VERSION "HNNBNNNYNNNNNNNNNNNNNNNNNNNNNNNNNNNNNNNNNN/4/%%%/4/'%**4NNN///"

NS_ :

BS_:

BU_: BAP_Tester BCM1 Gateway Klima_MSB Lift_VA VAS_L VAS_R

BO_ 958 Motor_14: 8 Gateway
 SG_ Motor_14_CRC : 0|8@1+ (1,0) [0|255] ""  Vector__XXX
 SG_ Motor_14_BZ : 8|4@1+ (1,0) [0|15] ""  Vector__XXX
 SG_ MO_StartStopp_Status : 12|2@1+ (1.0,0.0) [0.0|3] ""  BCM1,Klima_MSB,Lift_VA
 SG_ MO_StartStopp_Wiederstart : 14|1@1+ (1.0,0.0) [0.0|1] ""  BCM1,Klima_MSB,Lift_VA
 SG_ MO_StartStopp_Motorstopp : 15|1@1+ (1.0,0.0) [0.0|1] ""  BCM1,Klima_MSB,Lift_VA
 SG_ MO_Freig_Reku : 16|2@1+ (1.0,0.0) [0.0|3] ""  Vector__XXX
 SG_ MO_Kl_75 : 18|1@1+ (1.0,0.0) [0.0|1] ""  BCM1,Klima_MSB,VAS_L,VAS_R
 SG_ MO_Kl_50 : 19|1@1+ (1.0,0.0) [0.0|1] ""  Lift_VA
 SG_ MO_Gangposition : 20|4@1+ (1.0,0.0) [0.0|15] ""  BCM1,Klima_MSB,VAS_L,VAS_R
 SG_ MO_StartStopp_Fahrerwunsch : 24|2@1+ (1.0,0.0) [0.0|3] ""  BCM1,Klima_MSB,Lift_VA
 SG_ MO_HYB_Fahrbereitschaft : 26|1@1+ (1.0,0.0) [0.0|1] ""  BCM1,Klima_MSB
 SG_ MO_Ext_E_Fahrt_aktiv : 27|1@1+ (1.0,0.0) [0.0|1] ""  BCM1,Klima_MSB
 SG_ MO_Fahrer_bremst : 28|1@1+ (1.0,0.0) [0.0|1] ""  BCM1
 SG_ MO_QBit_Fahrer_bremst : 29|1@1+ (1.0,0.0) [0.0|1] ""  BCM1
 SG_ MO_BLS : 30|1@1+ (1.0,0.0) [0.0|1] ""  BCM1
 SG_ MO_Konsistenz_Bremsped : 31|1@1+ (1.0,0.0) [0.0|1] ""  Vector__XXX
 SG_ MO_KomFehler_ESP : 32|1@1+ (1.0,0.0) [0.0|1] ""  Vector__XXX
 SG_ MO_Klima_Eingr : 33|2@1+ (1.0,0.0) [0.0|3] ""  BCM1,Klima_MSB
 SG_ MO_Aussp_Anlass : 35|1@1+ (1.0,0.0) [0.0|1] ""  Vector__XXX
 SG_ MO_Freig_Anlass : 36|1@1+ (1.0,0.0) [0.0|1] ""  Vector__XXX
 SG_ MO_Kuppl_schalter : 37|1@1+ (1.0,0.0) [0.0|1] ""  BCM1
 SG_ MO_Interlock : 38|1@1+ (1.0,0.0) [0.0|1] ""  BCM1
 SG_ MO_Motor_laeuft : 39|1@1+ (1.0,0.0) [0.0|1] ""  BCM1,Klima_MSB,Lift_VA
 SG_ MO_Kickdown : 40|1@1+ (1.0,0.0) [0.0|1] ""  BCM1,Klima_MSB
 SG_ MO_QBit_KL_75 : 41|1@1+ (1.0,0.0) [0.0|1] ""  BCM1
 SG_ MO_EKlKomLeiRed : 42|2@1+ (1.0,0.0) [0.0|3] ""  Vector__XXX
 SG_ MO_Handshake_STH : 44|1@1+ (1.0,0.0) [0.0|1] ""  Vector__XXX
 SG_ MO_BKV_Unterdruckwarnung : 45|1@1+ (1.0,0.0) [0.0|1] ""  Vector__XXX
 SG_ MO_Freigabe_Segeln : 46|1@1+ (1.0,0.0) [0.0|1] ""  Vector__XXX
 SG_ MO_PTC_Status : 47|3@1+ (1.0,0.0) [0.0|7] ""  Vector__XXX
 SG_ MO_QBit_Gangposition : 50|1@1+ (1.0,0.0) [0.0|1] ""  Vector__XXX
 SG_ MO_Signalquelle_Gangposition : 51|1@1+ (1.0,0.0) [0.0|1] ""  Vector__XXX
 SG_ MO_Remotestart_Betrieb : 52|1@1+ (1.0,0.0) [0.0|1] ""  Vector__XXX
 SG_ MO_Remotestart_moeglich : 53|1@1+ (1.0,0.0) [0.0|1] ""  Vector__XXX
 SG_ MO_FMAus_aktiv : 55|1@1+ (1.0,0.0) [0.0|1] ""  BCM1,Klima_MSB
 SG_ MO_FMAus_Startvariante : 56|2@1+ (1.0,0.0) [0.0|3] ""  Vector__XXX
 SG_ MO_BMS_NV_Anf_stuetzen : 58|1@1+ (1.0,0.0) [0.0|1] ""  Vector__XXX
 SG_ MO_Zylinderabschaltung : 59|2@1+ (1.0,0.0) [0.0|3] ""  Vector__XXX
 SG_ MO_HYB_VM_aktiv : 61|1@1+ (1.0,0.0) [0.0|1] ""  BCM1,Klima_MSB
 SG_ MO_StartVorauss_erfuellt : 62|2@1+ (1.0,0.0) [0.0|3] ""  Vector__XXX

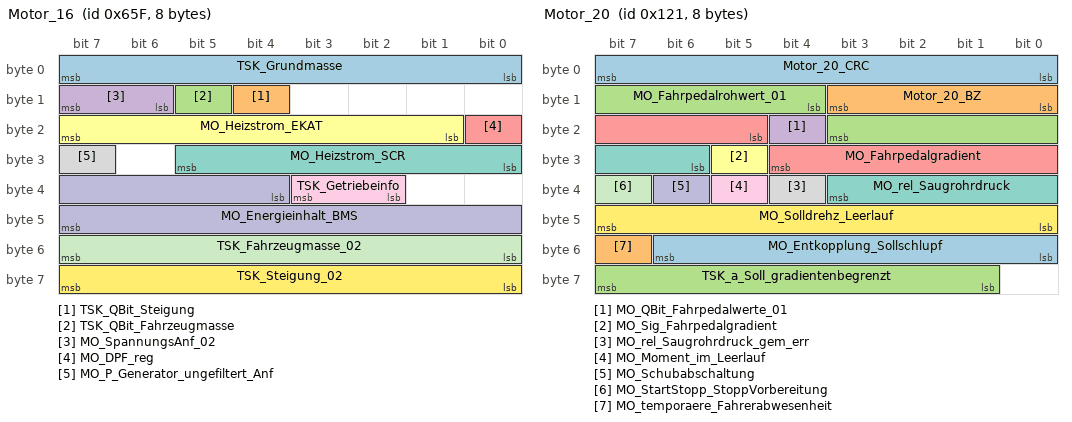
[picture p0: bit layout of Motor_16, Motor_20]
BO_ 1631 Motor_16: 8 Gateway
 SG_ TSK_Grundmasse : 0|8@1+ (32,0) [0|8128] "Unit_KiloGram"  Vector__XXX
 SG_ TSK_QBit_Steigung : 12|1@1+ (1.0,0.0) [0.0|1] ""  BCM1
 SG_ TSK_QBit_Fahrzeugmasse : 13|1@1+ (1.0,0.0) [0.0|1] ""  Vector__XXX
 SG_ MO_SpannungsAnf_02 : 14|2@1+ (1.0,0.0) [0.0|3] ""  Vector__XXX
 SG_ MO_DPF_reg : 16|1@1+ (1.0,0.0) [0.0|1] ""  Vector__XXX
 SG_ MO_Heizstrom_EKAT : 17|7@1+ (1,0) [0|126] "Unit_Amper"  Vector__XXX
 SG_ MO_Heizstrom_SCR : 24|6@1+ (1,0) [0|62] "Unit_Amper"  Vector__XXX
 SG_ MO_P_Generator_ungefiltert_Anf : 31|1@1+ (1.0,0.0) [0.0|1] ""  Vector__XXX
 SG_ TSK_Getriebeinfo : 34|2@1+ (1.0,0.0) [0.0|3] ""  Vector__XXX
 SG_ MO_Energieinhalt_BMS : 36|12@1+ (25,0) [0|102325] "Unit_WattHour"  Vector__XXX
 SG_ TSK_Fahrzeugmasse_02 : 48|8@1+ (32,0) [0|8128] "Unit_KiloGram"  Vector__XXX
 SG_ TSK_Steigung_02 : 56|8@1+ (0.8,-101.6) [-100.8|101.6] "Unit_PerCent"  BCM1

BO_ 812 Motor_17: 8 Gateway
 SG_ MO_Sperrung_FahrPr_BZS : 0|8@1+ (1.0,0.0) [0.0|255] ""  Vector__XXX
 SG_ MO_Rampenzeit_Generator_Anf : 8|4@1+ (1.0,0.0) [0.0|15] ""  Vector__XXX
 SG_ MO_Prio_MAX_Wunschdrehzahl : 12|1@1+ (1.0,0.0) [0.0|1] ""  Vector__XXX
 SG_ MO_Prio_MIN_Wunschdrehzahl : 13|1@1+ (1.0,0.0) [0.0|1] ""  Vector__XXX
 SG_ MO_Luftpfad_aktiv : 14|1@1+ (1.0,0.0) [0.0|1] ""  Vector__XXX
 SG_ MO_v_Begrenz_Aktivierbar : 15|1@1+ (1.0,0.0) [0.0|1] ""  Vector__XXX
 SG_ MO_Drehzahlbeeinflussung : 16|8@1+ (0.39,0) [0.00|99.45] "Unit_PerCent"  Vector__XXX
 SG_ MO_MIN_Wunschdrehzahl : 24|8@1+ (25,0) [0|6350] "Unit_MinutInver"  Vector__XXX
 SG_ MO_MAX_Wunschdrehzahl : 32|9@1+ (25,0) [0|12750] "Unit_MinutInver"  Vector__XXX
 SG_ MO_Charisma_FahrPr : 41|4@1+ (1.0,0.0) [0.0|15] ""  Vector__XXX
 SG_ MO_Charisma_Status : 45|2@1+ (1.0,0.0) [0.0|3] ""  Vector__XXX
 SG_ MO_StSt_Charisma_FahrPr : 47|4@1+ (1.0,0.0) [0.0|15] ""  Vector__XXX
 SG_ MO_StSt_Charisma_Status : 51|2@1+ (1.0,0.0) [0.0|3] ""  Vector__XXX
 SG_ MO_BZS_Charisma_FahrPr : 53|4@1+ (1.0,0.0) [0.0|15] ""  BCM1
 SG_ MO_BZS_Charisma_Status : 57|2@1+ (1.0,0.0) [0.0|3] ""  Vector__XXX
 SG_ MO_NGS_Position : 59|1@1+ (1.0,0.0) [0.0|1] ""  Vector__XXX
 SG_ MO_NGS_Status : 60|2@1+ (1.0,0.0) [0.0|3] ""  Vector__XXX
 SG_ MO_v_Begrenzung_Niveau : 62|2@1+ (1.0,0.0) [0.0|3] ""  Vector__XXX

BO_ 1648 Motor_18: 8 Gateway
 SG_ MO_max_Ladedruck : 0|6@1+ (0.1,0) [0.0|6.3] "Unit_Bar"  Vector__XXX
 SG_ MO_ANC_Kennfeld_Anf : 6|2@1+ (1.0,0.0) [0.0|3] ""  Vector__XXX
 SG_ MO_Bremslicht_Reku : 8|1@1+ (1.0,0.0) [0.0|1] ""  Vector__XXX
 SG_ MO_StartStopp_PopUp : 9|2@1+ (1.0,0.0) [0.0|3] ""  Vector__XXX
 SG_ MO1_Sperr_Info_WFS : 11|1@1+ (1.0,0.0) [0.0|1] ""  Vector__XXX
 SG_ MO1_Freigabe_Info_WFS : 12|1@1+ (1.0,0.0) [0.0|1] ""  Vector__XXX
 SG_ MO_EPCL : 13|3@1+ (1.0,0.0) [0.0|7] ""  Vector__XXX
 SG_ MO_Zylabsch_Texte_02 : 16|4@1+ (1.0,0.0) [0.0|15] ""  Vector__XXX
 SG_ MO_Fahrzeugtyp : 20|3@1+ (1.0,0.0) [0.0|7] ""  Vector__XXX
 SG_ MO_NMAX_Schaltanzeige : 23|9@1+ (25,0) [0|12775] "Unit_MinutInver"  Vector__XXX
 SG_ MO_Abstellzeit : 32|8@1+ (8,0) [0|2024] "Unit_Minut"  BCM1,Klima_MSB
 SG_ MO_Abstellzeit_Status : 40|2@1+ (1.0,0.0) [0.0|3] ""  BCM1,Klima_MSB
 SG_ MO1_Freigabe_Verfallsinfo_WFS : 42|1@1+ (1.0,0.0) [0.0|1] ""  Vector__XXX
 SG_ MO_Hybrid_StartStopp_LED : 43|2@1+ (1.0,0.0) [0.0|3] ""  BCM1
 SG_ MO_Fehler_Zylabsch : 45|2@1+ (1.0,0.0) [0.0|3] ""  Vector__XXX
 SG_ MO_Anzahl_Abgesch_Zyl : 47|3@1+ (1.0,0.0) [0.0|7] ""  Vector__XXX
 SG_ MO_Zylabsch_Texte : 50|2@1+ (1.0,0.0) [0.0|3] ""  Vector__XXX
 SG_ MO_Ethanol_BS_Texte : 52|3@1+ (1.0,0.0) [0.0|7] ""  Vector__XXX
 SG_ MO_Drehzahl_Warnung : 55|1@1+ (1.0,0.0) [0.0|1] ""  Vector__XXX
 SG_ MO_obere_Drehzahlgrenze : 56|8@1+ (50,0) [50|12750] "Unit_MinutInver"  Vector__XXX

BO_ 289 Motor_20: 8 Gateway
 SG_ Motor_20_CRC : 0|8@1+ (1,0) [0|255] ""  Vector__XXX
 SG_ Motor_20_BZ : 8|4@1+ (1,0) [0|15] ""  Vector__XXX
 SG_ MO_Fahrpedalrohwert_01 : 12|8@1+ (0.4,0) [0.0|101.6] "Unit_PerCent"  BCM1
 SG_ MO_QBit_Fahrpedalwerte_01 : 20|1@1+ (1.0,0.0) [0.0|1] ""  Vector__XXX
 SG_ MO_Fahrpedalgradient : 21|8@1+ (25,0) [0|6350] "Unit_PerCentPerSecon"  Vector__XXX
 SG_ MO_Sig_Fahrpedalgradient : 29|1@1+ (1.0,0.0) [0.0|1] ""  Vector__XXX
 SG_ MO_rel_Saugrohrdruck : 30|6@1+ (18,0) [0|1116] "Unit_MilliBar"  Vector__XXX
 SG_ MO_rel_Saugrohrdruck_gem_err : 36|1@1+ (1.0,0.0) [0.0|1] ""  Vector__XXX
 SG_ MO_Moment_im_Leerlauf : 37|1@1+ (1.0,0.0) [0.0|1] ""  Vector__XXX
 SG_ MO_Schubabschaltung : 38|1@1+ (1.0,0.0) [0.0|1] ""  Vector__XXX
 SG_ MO_StartStopp_StoppVorbereitung : 39|1@1+ (1.0,0.0) [0.0|1] ""  Vector__XXX
 SG_ MO_Solldrehz_Leerlauf : 40|8@1+ (10,0) [0|2540] "Unit_MinutInver"  Vector__XXX
 SG_ MO_Entkopplung_Sollschlupf : 48|7@1+ (20,0) [0|2480] "Unit_MinutInver"  Vector__XXX
 SG_ MO_temporaere_Fahrerabwesenheit : 55|1@1+ (1.0,0.0) [0.0|1] ""  Vector__XXX
 SG_ TSK_a_Soll_gradientenbegrenzt : 57|7@1+ (0.1,-7.2) [-7.2|5.4] "Unit_MeterPerSeconSquar"  Vector__XXX

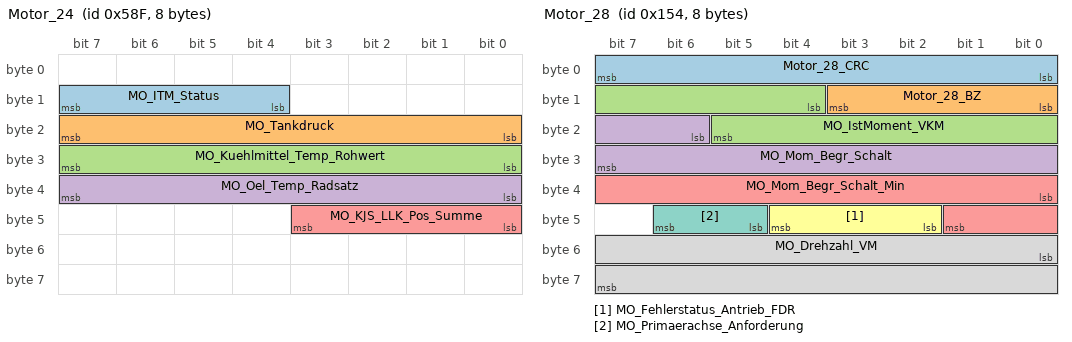
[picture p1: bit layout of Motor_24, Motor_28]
BO_ 1423 Motor_24: 8 Gateway
 SG_ MO_ITM_Status : 12|4@1+ (1.0,0.0) [0.0|15] ""  BCM1,Klima_MSB
 SG_ MO_Tankdruck : 16|8@1+ (2,-250) [-250|256] "Unit_MilliBar"  Vector__XXX
 SG_ MO_Kuehlmittel_Temp_Rohwert : 24|8@1+ (0.75,-48) [-48.00|141.75] "Unit_DegreCelsi"  Vector__XXX
 SG_ MO_Oel_Temp_Radsatz : 32|8@1+ (1,-60) [-60|193] "Unit_DegreCelsi"  Vector__XXX
 SG_ MO_KJS_LLK_Pos_Summe : 40|4@1+ (10,0) [0|100] "Unit_PerCent"  Vector__XXX

BO_ 967 Motor_26: 8 Gateway
 SG_ MO_Kuehlerluefter_MUX M  : 0|1@1+ (1.0,0.0) [0.0|1] ""  BCM1,Klima_MSB
 SG_ MO_Kuehlerluefter_1 m0  : 1|7@1+ (1,0) [0|100] "Unit_PerCent"  BCM1,Klima_MSB
 SG_ MO_Kuehlerluefter_2 m1  : 1|7@1+ (1,0) [0|100] "Unit_PerCent"  BCM1,Klima_MSB
 SG_ MO_EFLEX_Lampe : 8|2@1+ (1.0,0.0) [0.0|3] ""  Vector__XXX
 SG_ MO_KJS_nicht_bereit : 10|1@1+ (1.0,0.0) [0.0|1] ""  Vector__XXX
 SG_ MO_ITM_Warnung_Pumpe : 11|1@1+ (1.0,0.0) [0.0|1] ""  Vector__XXX
 SG_ WIV_Anzeige_aktiv : 12|1@1+ (1.0,0.0) [0.0|1] ""  Vector__XXX
 SG_ WIV_Oelmin_Warn : 13|1@1+ (1.0,0.0) [0.0|1] ""  Vector__XXX
 SG_ WIV_Sensorfehler : 14|1@1+ (1.0,0.0) [0.0|1] ""  Vector__XXX
 SG_ WIV_Schieflage : 15|1@1+ (1.0,0.0) [0.0|1] ""  Vector__XXX
 SG_ WIV_Oelstand : 16|4@1+ (12.5,0) [0.0|100.0] "Unit_PerCent"  Vector__XXX
 SG_ MO_Zustand_HWP : 20|2@1+ (1.0,0.0) [0.0|3] ""  Vector__XXX
 SG_ OLEV_Systemstoerung : 22|1@1+ (1.0,0.0) [0.0|1] ""  Vector__XXX
 SG_ MO_Oelwarnung_max : 23|1@1+ (1.0,0.0) [0.0|1] ""  Vector__XXX
 SG_ WIV_Oelsystem_aktiv : 24|1@1+ (1.0,0.0) [0.0|1] ""  Vector__XXX
 SG_ WIV_nicht_betriebswarm : 25|1@1+ (1.0,0.0) [0.0|1] ""  Vector__XXX
 SG_ WIV_Ueberfuell_Warn : 26|1@1+ (1.0,0.0) [0.0|1] ""  Vector__XXX
 SG_ WIV_laufender_Motor : 27|1@1+ (1.0,0.0) [0.0|1] ""  Vector__XXX
 SG_ MO_E_Warnungen : 28|4@1+ (1.0,0.0) [0.0|15] ""  Vector__XXX
 SG_ MO_Text_Motorstart : 32|4@1+ (1.0,0.0) [0.0|15] ""  Vector__XXX
 SG_ MO_E_Texte : 36|4@1+ (1.0,0.0) [0.0|15] ""  Vector__XXX
 SG_ WIV_Oeldyn_avl : 40|1@1+ (1.0,0.0) [0.0|1] ""  Vector__XXX
 SG_ MO_Text_Partikelfil_Reg : 41|1@1+ (1,0) [0|1] ""  Vector__XXX
 SG_ OLEV_Oelstand_nicht_vorhanden : 42|1@1+ (1.0,0.0) [0.0|1] ""  Vector__XXX
 SG_ WIV_Oelmenge : 43|5@1+ (125,0) [0|3875] "Unit_MilliLiter"  Vector__XXX
 SG_ MO_Systemlampe : 48|1@1+ (1.0,0.0) [0.0|1] ""  Vector__XXX
 SG_ MO_OBD2_Lampe : 49|1@1+ (1.0,0.0) [0.0|1] ""  Vector__XXX
 SG_ MO_Heissleuchte : 50|1@1+ (1.0,0.0) [0.0|1] ""  Vector__XXX
 SG_ MO_Partikel_Lampe : 51|1@1+ (1.0,0.0) [0.0|1] ""  Vector__XXX
 SG_ MO_RedFahrleistung_Lampe : 52|1@1+ (1.0,0.0) [0.0|1] ""  Vector__XXX
 SG_ WIV_Oelstand_nicht_vorhanden : 53|1@1+ (1.0,0.0) [0.0|1] ""  Vector__XXX
 SG_ WIV_nachfuellanzeige_ein : 54|1@1+ (1.0,0.0) [0.0|1] ""  Vector__XXX
 SG_ WIV_Ueberfuell_deaktiv : 55|1@1+ (1.0,0.0) [0.0|1] ""  Vector__XXX
 SG_ WIV_Unterfuell_Warn : 56|1@1+ (1.0,0.0) [0.0|1] ""  Vector__XXX
 SG_ MO_Tankdeckel_Lampe : 57|1@1+ (1.0,0.0) [0.0|1] ""  Vector__XXX
 SG_ MO_Text_Tankdeckelwarn : 58|1@1+ (1.0,0.0) [0.0|1] ""  Vector__XXX
 SG_ MO_Vorglueh_Lampe : 59|1@1+ (1.0,0.0) [0.0|1] ""  Vector__XXX
 SG_ WIV_Oeldr_Warn_Motor : 60|1@1+ (1.0,0.0) [0.0|1] ""  Vector__XXX
 SG_ MO_E_Mode : 61|3@1+ (1.0,0.0) [0.0|7] ""  Vector__XXX

BO_ 340 Motor_28: 8 Gateway
 SG_ Motor_28_CRC : 0|8@1+ (1,0) [0|255] ""  Vector__XXX
 SG_ Motor_28_BZ : 8|4@1+ (1,0) [0|15] ""  Vector__XXX
 SG_ MO_IstMoment_VKM : 12|10@1+ (1,-509) [-509|509] ""  Vector__XXX
 SG_ MO_Mom_Begr_Schalt : 22|10@1+ (1,-509) [-509|509] ""  Vector__XXX
 SG_ MO_Mom_Begr_Schalt_Min : 32|10@1+ (1,-509) [-509|509] ""  Vector__XXX
 SG_ MO_Fehlerstatus_Antrieb_FDR : 42|3@1+ (1.0,0.0) [0.0|7] ""  Vector__XXX
 SG_ MO_Primaerachse_Anforderung : 45|2@1+ (1.0,0.0) [0.0|3] ""  Vector__XXX
 SG_ MO_Drehzahl_VM : 48|16@1+ (0.25,0) [0.00|16383.00] "Unit_MinutInver"  BCM1,Klima_MSB

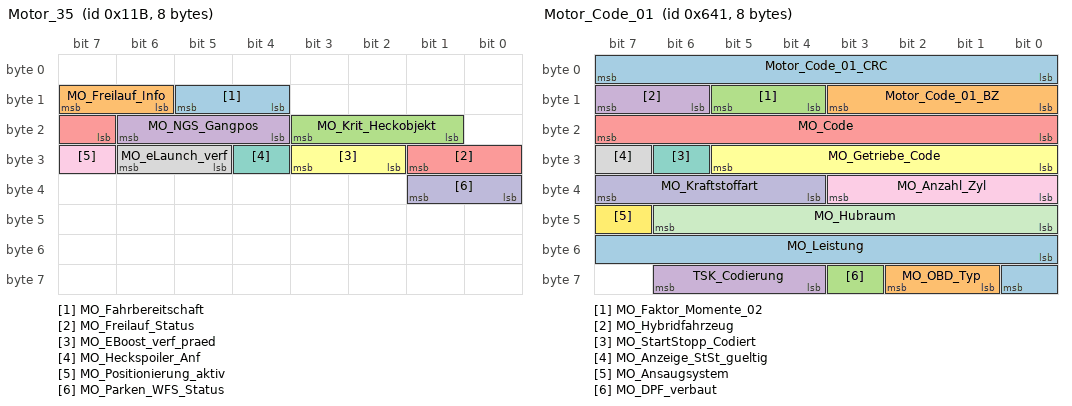
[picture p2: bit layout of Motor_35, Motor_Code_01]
BO_ 283 Motor_35: 8 Gateway
 SG_ MO_Fahrbereitschaft : 12|2@1+ (1.0,0.0) [0.0|3] ""  BCM1
 SG_ MO_Freilauf_Info : 14|2@1+ (1.0,0.0) [0.0|3] ""  Vector__XXX
 SG_ MO_Krit_Heckobjekt : 17|3@1+ (1.0,0.0) [0.0|7] ""  Vector__XXX
 SG_ MO_NGS_Gangpos : 20|3@1+ (1.0,0.0) [0.0|7] ""  Vector__XXX
 SG_ MO_Freilauf_Status : 23|3@1+ (1.0,0.0) [0.0|7] ""  Vector__XXX
 SG_ MO_EBoost_verf_praed : 26|2@1+ (1.0,0.0) [0.0|3] ""  Vector__XXX
 SG_ MO_Heckspoiler_Anf : 28|1@1+ (1.0,0.0) [0.0|1] ""  Vector__XXX
 SG_ MO_eLaunch_verf : 29|2@1+ (1.0,0.0) [0.0|3] ""  Vector__XXX
 SG_ MO_Positionierung_aktiv : 31|1@1+ (1.0,0.0) [0.0|1] ""  Vector__XXX
 SG_ MO_Parken_WFS_Status : 32|2@1+ (1.0,0.0) [0.0|3] ""  Vector__XXX

BO_ 1601 Motor_Code_01: 8 Gateway
 SG_ Motor_Code_01_CRC : 0|8@1+ (1,0) [0|255] ""  BCM1
 SG_ Motor_Code_01_BZ : 8|4@1+ (1,0) [0|15] ""  BCM1
 SG_ MO_Faktor_Momente_02 : 12|2@1+ (1,0) [1|3] "Unit_NewtoMeter"  BCM1
 SG_ MO_Hybridfahrzeug : 14|2@1+ (1.0,0.0) [0.0|3] ""  BCM1
 SG_ MO_Code : 16|8@1+ (1,0) [0|255] ""  BCM1,Klima_MSB
 SG_ MO_Getriebe_Code : 24|6@1+ (1.0,0.0) [0.0|63] ""  BCM1,Klima_MSB
 SG_ MO_StartStopp_Codiert : 30|1@1+ (1.0,0.0) [0.0|1] ""  Lift_VA
 SG_ MO_Anzeige_StSt_gueltig : 31|1@1+ (1.0,0.0) [0.0|1] ""  Vector__XXX
 SG_ MO_Anzahl_Zyl : 32|4@1+ (1.0,0.0) [0.0|15] ""  Vector__XXX
 SG_ MO_Kraftstoffart : 36|4@1+ (1.0,0.0) [0.0|15] ""  BCM1
 SG_ MO_Hubraum : 40|7@1+ (0.1,0) [0.0|12.7] "Unit_Liter"  Vector__XXX
 SG_ MO_Ansaugsystem : 47|1@1+ (1.0,0.0) [0.0|1] ""  Vector__XXX
 SG_ MO_Leistung : 48|9@1+ (1,0) [0|511] "Unit_KiloWatt"  Vector__XXX
 SG_ MO_OBD_Typ : 57|2@1+ (1.0,0.0) [0.0|3] ""  BCM1
 SG_ MO_DPF_verbaut : 59|1@1+ (1.0,0.0) [0.0|1] ""  Vector__XXX
 SG_ TSK_Codierung : 60|3@1+ (1.0,0.0) [0.0|7] ""  Vector__XXX

BO_ 394 Motor_Hybrid_11: 8 Gateway
 SG_ MO_Ablaufstatus : 12|4@1+ (1.0,0.0) [0.0|15] ""  Vector__XXX
 SG_ MO_Ablaufstrg_Betriebszustand : 16|3@1+ (1.0,0.0) [0.0|7] ""  Vector__XXX
 SG_ MO_Ablaufstrg_Zustand_VKM_Ist : 19|1@1+ (1.0,0.0) [0.0|1] ""  Vector__XXX
 SG_ MO_Ablaufstrg_Kraftschluss_Ist : 20|1@1+ (1.0,0.0) [0.0|1] ""  Vector__XXX
 SG_ MO_Ablaufstrg_Zustand_K0_Ist : 21|1@1+ (1.0,0.0) [0.0|1] ""  Vector__XXX
 SG_ MO_Ablaufstrg_Kraftschluss2_Ist : 22|1@1+ (1.0,0.0) [0.0|1] ""  Vector__XXX
 SG_ MO_HYB_LowSpeedModus : 23|1@1+ (1.0,0.0) [0.0|1] ""  Vector__XXX
 SG_ MO_Ablaufstrg_Zustand_VKM_Ziel : 24|1@1+ (1.0,0.0) [0.0|1] ""  Vector__XXX
 SG_ MO_Ablaufstrg_Kraftschluss_Ziel : 25|1@1+ (1.0,0.0) [0.0|1] ""  Vector__XXX
 SG_ MO_Ablaufstrg_Zustand_K0_Ziel : 26|1@1+ (1.0,0.0) [0.0|1] ""  Vector__XXX
 SG_ MO_Ablaufstrg_Kraftschluss2_Ziel : 27|1@1+ (1.0,0.0) [0.0|1] ""  Vector__XXX
 SG_ MO_HYB_Stoppmodus : 28|1@1+ (1.0,0.0) [0.0|1] ""  Vector__XXX
 SG_ MO_Auth_Aufforderung_WFS : 29|1@1+ (1.0,0.0) [0.0|1] ""  Vector__XXX
 SG_ MO_Start_Dynamik : 30|3@1+ (1.0,0.0) [0.0|7] ""  Vector__XXX
 SG_ MO_Start_Art : 33|3@1+ (1.0,0.0) [0.0|7] ""  BCM1,Klima_MSB
 SG_ MO_Abstellposition_02 : 36|8@1+ (2,0) [0|508] "Unit_DegreOfArc"  Vector__XXX
 SG_ MO_Mom_Freiheit_Sekundaerachse : 44|1@1+ (1.0,0.0) [0.0|1] ""  Vector__XXX
 SG_ MO_Nachlaufzeit_Kuehlerluefter : 45|6@1+ (15,0) [0|945] "Unit_Secon"  Vector__XXX
 SG_ MO_Tankklappensteuerung : 51|2@1+ (1.0,0.0) [0.0|3] ""  Vector__XXX
 SG_ MO_HYB_E_Faktor : 53|4@1+ (1.0,0.0) [0.0|15] ""  Vector__XXX
 SG_ MO_HYB_EMode_Info : 57|2@1+ (1.0,0.0) [0.0|3] ""  Vector__XXX
 SG_ MO_HYB_Adaption_aktiv : 59|1@1+ (1.0,0.0) [0.0|1] ""  Vector__XXX

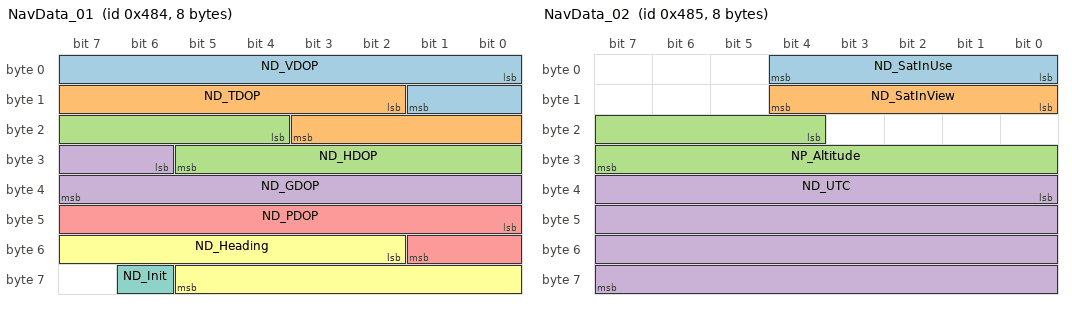
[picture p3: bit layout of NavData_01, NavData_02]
BO_ 1156 NavData_01: 8 Gateway
 SG_ ND_VDOP : 0|10@1+ (0.025,0) [0.000|25.000] ""  Vector__XXX
 SG_ ND_TDOP : 10|10@1+ (0.025,0) [0.000|25.000] ""  Vector__XXX
 SG_ ND_HDOP : 20|10@1+ (0.025,0) [0.000|25.000] ""  Vector__XXX
 SG_ ND_GDOP : 30|10@1+ (0.025,0) [0.000|25.000] ""  Vector__XXX
 SG_ ND_PDOP : 40|10@1+ (0.025,0) [0.000|25.000] ""  Vector__XXX
 SG_ ND_Heading : 50|12@1+ (0.1,0) [0.0|359.9] "Unit_DegreOfArc"  BCM1,Klima_MSB
 SG_ ND_Init : 62|1@1+ (1.0,0.0) [0.0|1] ""  BCM1

BO_ 1157 NavData_02: 8 Gateway
 SG_ ND_SatInUse : 0|5@1+ (1,0) [0|29] ""  Vector__XXX
 SG_ ND_SatInView : 8|5@1+ (1,0) [0|29] ""  Vector__XXX
 SG_ NP_Altitude : 20|12@1+ (2,-500) [-500|7686] "Unit_Meter"  BCM1,Klima_MSB
 SG_ ND_UTC : 32|32@1+ (1,0) [0|4294967293] "Unit_Secon"  BCM1

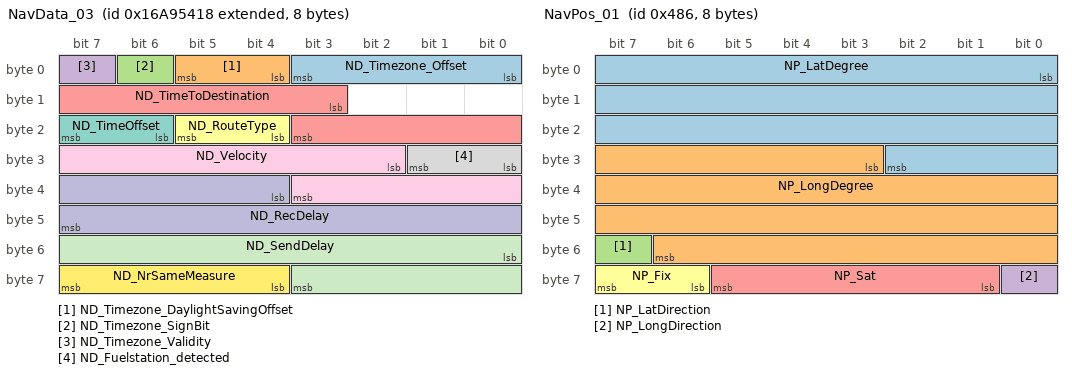
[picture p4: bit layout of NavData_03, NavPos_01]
BO_ 2527679512 NavData_03: 8 Gateway
 SG_ ND_Timezone_Offset : 0|4@1+ (1,0) [0|12] "Unit_Hours"  Klima_MSB
 SG_ ND_Timezone_DaylightSavingOffset : 4|2@1+ (30,0) [0|60] "Unit_Minut"  Klima_MSB
 SG_ ND_Timezone_SignBit : 6|1@1+ (1.0,0.0) [0.0|1] ""  Klima_MSB
 SG_ ND_Timezone_Validity : 7|1@1+ (1.0,0.0) [0.0|1] ""  Klima_MSB
 SG_ ND_TimeToDestination : 11|9@1+ (1,0) [0|509] "Unit_Minut"  Vector__XXX
 SG_ ND_RouteType : 20|2@1+ (1.0,0.0) [0.0|3] ""  Vector__XXX
 SG_ ND_TimeOffset : 22|2@1+ (1.0,0.0) [0.0|3] ""  Vector__XXX
 SG_ ND_Fuelstation_detected : 24|2@1+ (1.0,0.0) [0.0|3] ""  Vector__XXX
 SG_ ND_Velocity : 26|10@1+ (0.1,0) [0.0|102.1] "Unit_MeterPerSecon"  Vector__XXX
 SG_ ND_RecDelay : 36|12@1+ (1,0) [0|4093] "Unit_MilliSecon"  Vector__XXX
 SG_ ND_SendDelay : 48|12@1+ (1,0) [0|4093] "Unit_MilliSecon"  Vector__XXX
 SG_ ND_NrSameMeasure : 60|4@1+ (1,0) [0|8] ""  Vector__XXX

BO_ 1158 NavPos_01: 8 Gateway
 SG_ NP_LatDegree : 0|27@1+ (0.000001,0) [0.000000|90.000000] "Unit_DegreOfArc"  BCM1,Klima_MSB
 SG_ NP_LongDegree : 27|28@1+ (0.000001,0) [0.000000|180.000000] "Unit_DegreOfArc"  BCM1,Klima_MSB
 SG_ NP_LatDirection : 55|1@1+ (1.0,0.0) [0.0|1] ""  BCM1,Klima_MSB
 SG_ NP_LongDirection : 56|1@1+ (1.0,0.0) [0.0|1] ""  BCM1,Klima_MSB
 SG_ NP_Sat : 57|5@1+ (1,0) [0|29] ""  Vector__XXX
 SG_ NP_Fix : 62|2@1+ (1.0,0.0) [0.0|3] ""  Vector__XXX

BO_ 2589283496 NavPos_02_Map_Matched: 8 Gateway
 SG_ POS_MUX M  : 0|2@1+ (1.0,0.0) [0.0|3] ""  Klima_MSB
 SG_ POS_ODD_EVEN : 2|1@1+ (1.0,0.0) [0.0|1] ""  Vector__XXX
 SG_ POS_PosStati m0  : 3|4@1+ (1.0,0.0) [0.0|15] ""  Klima_MSB
 SG_ POS_Heading m1  : 4|12@1+ (0.1,0) [0.0|409.5] "Unit_DegreOfArc"  Klima_MSB
 SG_ POS_LatDirection m0  : 7|1@1+ (1.0,0.0) [0.0|1] ""  Klima_MSB
 SG_ POS_LatDegree m0  : 8|27@1+ (0.000001,0) [0.000000|90.000000] "Unit_DegreOfArc"  Klima_MSB
 SG_ POS_Last_GPS_Sync m1  : 16|14@1+ (1,0) [0|16383] "Unit_Secon"  Vector__XXX
 SG_ POS_Heading_Trust m1  : 30|2@1+ (1.0,0.0) [0.0|3] ""  Klima_MSB
 SG_ POS_UTC_REF m1  : 32|32@1+ (1,0) [0|4294967295] "Unit_Secon"  Klima_MSB
 SG_ POS_LongDirection m0  : 35|1@1+ (1.0,0.0) [0.0|1] ""  Klima_MSB
 SG_ POS_LongDegree m0  : 36|28@1+ (0.000001,0) [0.000000|180.000000] "Unit_DegreOfArc"  Klima_MSB

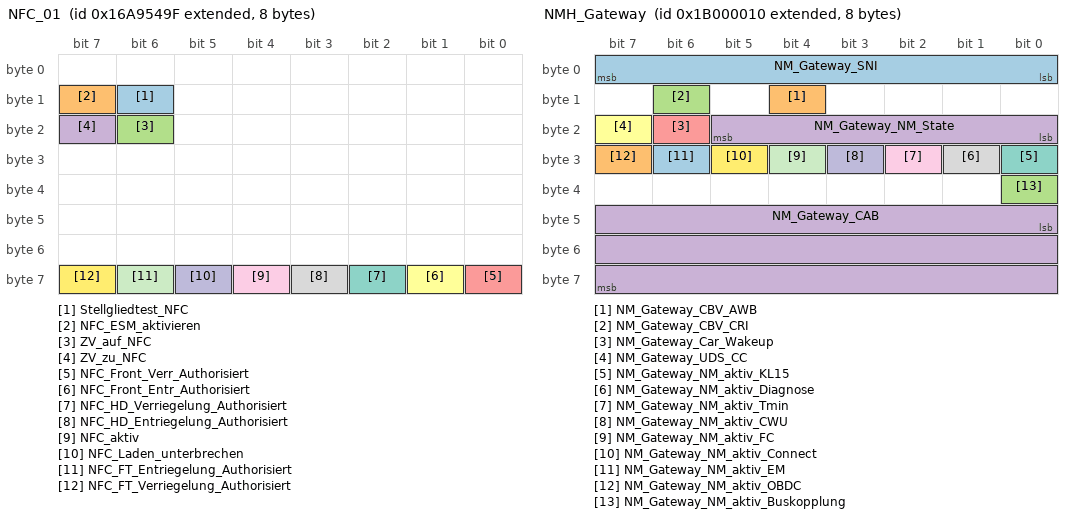
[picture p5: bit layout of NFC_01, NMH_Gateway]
BO_ 2527679647 NFC_01: 8 Gateway
 SG_ Stellgliedtest_NFC : 14|1@1+ (1.0,0.0) [0.0|1] ""  Vector__XXX
 SG_ NFC_ESM_aktivieren : 15|1@1+ (1.0,0.0) [0.0|1] ""  Vector__XXX
 SG_ ZV_auf_NFC : 22|1@1+ (1.0,0.0) [0.0|1] ""  BCM1
 SG_ ZV_zu_NFC : 23|1@1+ (1.0,0.0) [0.0|1] ""  BCM1
 SG_ NFC_Front_Verr_Authorisiert : 56|1@1+ (1.0,0.0) [0.0|1] ""  BCM1
 SG_ NFC_Front_Entr_Authorisiert : 57|1@1+ (1.0,0.0) [0.0|1] ""  BCM1
 SG_ NFC_HD_Verriegelung_Authorisiert : 58|1@1+ (1.0,0.0) [0.0|1] ""  Vector__XXX
 SG_ NFC_HD_Entriegelung_Authorisiert : 59|1@1+ (1.0,0.0) [0.0|1] ""  Vector__XXX
 SG_ NFC_aktiv : 60|1@1+ (1.0,0.0) [0.0|1] ""  Vector__XXX
 SG_ NFC_Laden_unterbrechen : 61|1@1+ (1.0,0.0) [0.0|1] ""  Vector__XXX
 SG_ NFC_FT_Entriegelung_Authorisiert : 62|1@1+ (1.0,0.0) [0.0|1] ""  Vector__XXX
 SG_ NFC_FT_Verriegelung_Authorisiert : 63|1@1+ (1.0,0.0) [0.0|1] ""  Vector__XXX

BO_ 1696 NightVision_01: 8 Gateway
 SG_ NV_aktiv : 12|1@1+ (1.0,0.0) [0.0|1] ""  Vector__XXX
 SG_ NV_Texte : 13|3@1+ (1.0,0.0) [0.0|7] ""  Vector__XXX
 SG_ NV_Gong : 16|2@1+ (1.0,0.0) [0.0|3] ""  Vector__XXX
 SG_ NV_Symbol : 18|1@1+ (1.0,0.0) [0.0|1] ""  BCM1
 SG_ NV_Hinweise : 19|2@1+ (1.0,0.0) [0.0|3] ""  Vector__XXX
 SG_ NV_Piktogramm_aktiv : 21|1@1+ (1.0,0.0) [0.0|1] ""  Vector__XXX
 SG_ NV_Akustik_deaktiviert_Icon : 22|1@1+ (1.0,0.0) [0.0|1] ""  Vector__XXX
 SG_ NV_FGM_deaktiviert_Icon : 23|1@1+ (1.0,0.0) [0.0|1] ""  Vector__XXX
 SG_ NV_Markierungslicht_links : 24|1@1+ (1.0,0.0) [0.0|1] ""  Vector__XXX
 SG_ NV_Markierungslicht_rechts : 25|1@1+ (1.0,0.0) [0.0|1] ""  Vector__XXX
 SG_ NV_Symbol_Tierwarnung : 26|1@1+ (1.0,0.0) [0.0|1] ""  BCM1
 SG_ NV_Anf_Prefill : 27|1@1+ (1.0,0.0) [0.0|1] ""  Vector__XXX
 SG_ NV_HBA_Parameter : 28|2@1+ (1.0,0.0) [0.0|3] ""  Vector__XXX
 SG_ NV_LED_Leiste : 30|2@1+ (1.0,0.0) [0.0|3] ""  Vector__XXX
 SG_ NV_PreSense_Status : 32|2@1+ (1.0,0.0) [0.0|3] ""  Vector__XXX
 SG_ NV_PreSense_Modus_System : 34|1@1+ (1.0,0.0) [0.0|1] ""  Vector__XXX
 SG_ NV_PreSense_Modus_Warnung : 35|3@1+ (1.0,0.0) [0.0|7] ""  Vector__XXX
 SG_ NV_FAS_Fkt_Status : 38|2@1+ (1.0,0.0) [0.0|3] ""  Vector__XXX
 SG_ NV_Akt_Status_MMI : 40|2@1+ (1.0,0.0) [0.0|3] ""  Vector__XXX
 SG_ NV_AnforderungBildaufschaltung : 42|1@1+ (1.0,0.0) [0.0|1] ""  Vector__XXX

BO_ 2600468494 NMH_BCM1: 8 BCM1
 SG_ NM_BCM1_SNI : 0|8@1+ (1.0,0.0) [0.0|255] ""  BCM1,Gateway,Klima_MSB,Lift_VA,VAS_L,VAS_R
 SG_ NM_BCM1_CBV_AWB : 12|1@1+ (1.0,0.0) [0.0|1] ""  Gateway
 SG_ NM_BCM1_CBV_CRI : 14|1@1+ (1.0,0.0) [0.0|1] ""  BCM1,Gateway,Klima_MSB,Lift_VA,VAS_L,VAS_R
 SG_ NM_BCM1_NM_State : 16|6@1+ (1.0,0.0) [0.0|63] ""  Vector__XXX
 SG_ NM_BCM1_Car_Wakeup : 22|1@1+ (1.0,0.0) [0.0|1] ""  Gateway
 SG_ NM_BCM1_UDS_CC : 23|1@1+ (1.0,0.0) [0.0|1] ""  Vector__XXX
 SG_ NM_BCM1_NM_aktiv_KL15 : 24|1@1+ (1.0,0.0) [0.0|1] ""  Vector__XXX
 SG_ NM_BCM1_NM_aktiv_Diagnose : 25|1@1+ (1.0,0.0) [0.0|1] ""  Vector__XXX
 SG_ NM_BCM1_NM_aktiv_Tmin : 26|1@1+ (1.0,0.0) [0.0|1] ""  Vector__XXX
 SG_ NM_BCM1_NM_aktiv_Notlaufblinken : 27|1@1+ (1.0,0.0) [0.0|1] ""  Vector__XXX
 SG_ NM_BCM1_NM_aktiv_ComingHome : 28|1@1+ (1.0,0.0) [0.0|1] ""  Vector__XXX
 SG_ NM_BCM1_NM_aktiv_LeavingHome : 29|1@1+ (1.0,0.0) [0.0|1] ""  Vector__XXX
 SG_ NM_BCM1_NM_aktiv_Taster_Schalter : 30|1@1+ (1.0,0.0) [0.0|1] ""  Vector__XXX
 SG_ NM_BCM1_NM_aktiv_LIM : 31|1@1+ (1.0,0.0) [0.0|1] ""  Vector__XXX
 SG_ NM_BCM1_NM_aktiv_Innenlicht_Dim : 32|1@1+ (1.0,0.0) [0.0|1] ""  Vector__XXX
 SG_ NM_BCM1_NM_aktiv_Aussenlicht : 33|1@1+ (1.0,0.0) [0.0|1] ""  Vector__XXX
 SG_ NM_BCM1_NM_aktiv_Klimatisierung : 34|1@1+ (1.0,0.0) [0.0|1] ""  Vector__XXX
 SG_ NM_BCM1_CAB : 40|24@1+ (1.0,0.0) [0.0|16777215] ""  BCM1,Gateway,Klima_MSB,Lift_VA,VAS_L,VAS_R

BO_ 2600468496 NMH_Gateway: 8 Gateway
 SG_ NM_Gateway_SNI : 0|8@1+ (1.0,0.0) [0.0|255] ""  BCM1,Gateway,Klima_MSB,Lift_VA,VAS_L,VAS_R
 SG_ NM_Gateway_CBV_AWB : 12|1@1+ (1.0,0.0) [0.0|1] ""  Vector__XXX
 SG_ NM_Gateway_CBV_CRI : 14|1@1+ (1.0,0.0) [0.0|1] ""  BCM1,Gateway,Klima_MSB,Lift_VA,VAS_L,VAS_R
 SG_ NM_Gateway_NM_State : 16|6@1+ (1.0,0.0) [0.0|63] ""  Vector__XXX
 SG_ NM_Gateway_Car_Wakeup : 22|1@1+ (1.0,0.0) [0.0|1] ""  Vector__XXX
 SG_ NM_Gateway_UDS_CC : 23|1@1+ (1.0,0.0) [0.0|1] ""  Vector__XXX
 SG_ NM_Gateway_NM_aktiv_KL15 : 24|1@1+ (1.0,0.0) [0.0|1] ""  Vector__XXX
 SG_ NM_Gateway_NM_aktiv_Diagnose : 25|1@1+ (1.0,0.0) [0.0|1] ""  Vector__XXX
 SG_ NM_Gateway_NM_aktiv_Tmin : 26|1@1+ (1.0,0.0) [0.0|1] ""  Vector__XXX
 SG_ NM_Gateway_NM_aktiv_CWU : 27|1@1+ (1.0,0.0) [0.0|1] ""  Vector__XXX
 SG_ NM_Gateway_NM_aktiv_FC : 28|1@1+ (1.0,0.0) [0.0|1] ""  Vector__XXX
 SG_ NM_Gateway_NM_aktiv_Connect : 29|1@1+ (1.0,0.0) [0.0|1] ""  Vector__XXX
 SG_ NM_Gateway_NM_aktiv_EM : 30|1@1+ (1.0,0.0) [0.0|1] ""  Vector__XXX
 SG_ NM_Gateway_NM_aktiv_OBDC : 31|1@1+ (1.0,0.0) [0.0|1] ""  Vector__XXX
 SG_ NM_Gateway_NM_aktiv_Buskopplung : 32|1@1+ (1.0,0.0) [0.0|1] ""  Vector__XXX
 SG_ NM_Gateway_CAB : 40|24@1+ (1.0,0.0) [0.0|16777215] ""  BCM1,Gateway,Klima_MSB,Lift_VA,VAS_L,VAS_R

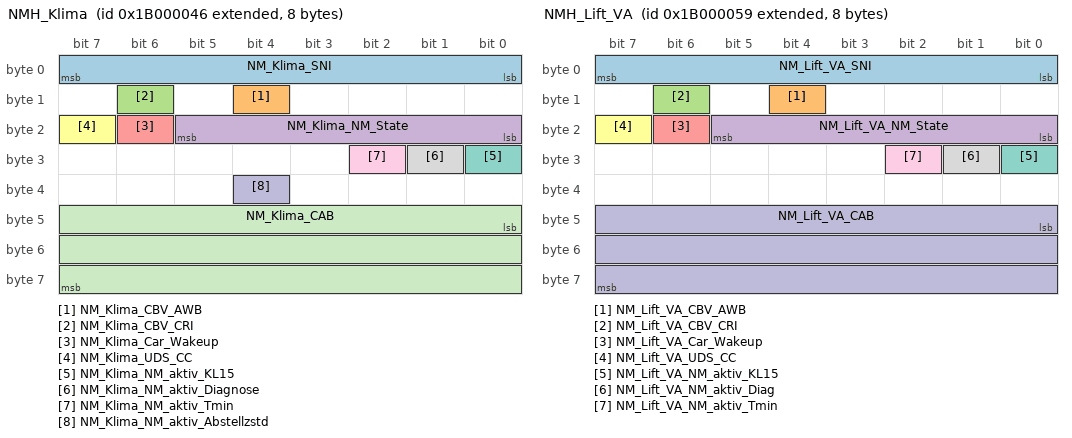
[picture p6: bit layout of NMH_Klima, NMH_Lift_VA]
BO_ 2600468550 NMH_Klima: 8 Klima_MSB
 SG_ NM_Klima_SNI : 0|8@1+ (1.0,0.0) [0.0|255] ""  BCM1,Gateway,Klima_MSB,Lift_VA,VAS_L,VAS_R
 SG_ NM_Klima_CBV_AWB : 12|1@1+ (1.0,0.0) [0.0|1] ""  Gateway
 SG_ NM_Klima_CBV_CRI : 14|1@1+ (1.0,0.0) [0.0|1] ""  BCM1,Gateway,Klima_MSB,Lift_VA,VAS_L,VAS_R
 SG_ NM_Klima_NM_State : 16|6@1+ (1.0,0.0) [0.0|63] ""  Vector__XXX
 SG_ NM_Klima_Car_Wakeup : 22|1@1+ (1.0,0.0) [0.0|1] ""  Gateway
 SG_ NM_Klima_UDS_CC : 23|1@1+ (1.0,0.0) [0.0|1] ""  Vector__XXX
 SG_ NM_Klima_NM_aktiv_KL15 : 24|1@1+ (1.0,0.0) [0.0|1] ""  Vector__XXX
 SG_ NM_Klima_NM_aktiv_Diagnose : 25|1@1+ (1.0,0.0) [0.0|1] ""  Vector__XXX
 SG_ NM_Klima_NM_aktiv_Tmin : 26|1@1+ (1.0,0.0) [0.0|1] ""  Vector__XXX
 SG_ NM_Klima_NM_aktiv_Abstellzstd : 36|1@1+ (1.0,0.0) [0.0|1] ""  Vector__XXX
 SG_ NM_Klima_CAB : 40|24@1+ (1.0,0.0) [0.0|16777215] ""  BCM1,Gateway,Klima_MSB,Lift_VA,VAS_L,VAS_R

BO_ 2600468569 NMH_Lift_VA: 8 Lift_VA
 SG_ NM_Lift_VA_SNI : 0|8@1+ (1.0,0.0) [0.0|255] ""  BCM1,Gateway,Klima_MSB,Lift_VA,VAS_L,VAS_R
 SG_ NM_Lift_VA_CBV_AWB : 12|1@1+ (1.0,0.0) [0.0|1] ""  Vector__XXX
 SG_ NM_Lift_VA_CBV_CRI : 14|1@1+ (1.0,0.0) [0.0|1] ""  BCM1,Gateway,Klima_MSB,Lift_VA,VAS_L,VAS_R
 SG_ NM_Lift_VA_NM_State : 16|6@1+ (1.0,0.0) [0.0|63] ""  Vector__XXX
 SG_ NM_Lift_VA_Car_Wakeup : 22|1@1+ (1.0,0.0) [0.0|1] ""  Vector__XXX
 SG_ NM_Lift_VA_UDS_CC : 23|1@1+ (1.0,0.0) [0.0|1] ""  Vector__XXX
 SG_ NM_Lift_VA_NM_aktiv_KL15 : 24|1@1+ (1.0,0.0) [0.0|1] ""  Vector__XXX
 SG_ NM_Lift_VA_NM_aktiv_Diag : 25|1@1+ (1.0,0.0) [0.0|1] ""  Vector__XXX
 SG_ NM_Lift_VA_NM_aktiv_Tmin : 26|1@1+ (1.0,0.0) [0.0|1] ""  Vector__XXX
 SG_ NM_Lift_VA_CAB : 40|24@1+ (1.0,0.0) [0.0|16777215] ""  BCM1,Gateway,Klima_MSB,Lift_VA,VAS_L,VAS_R

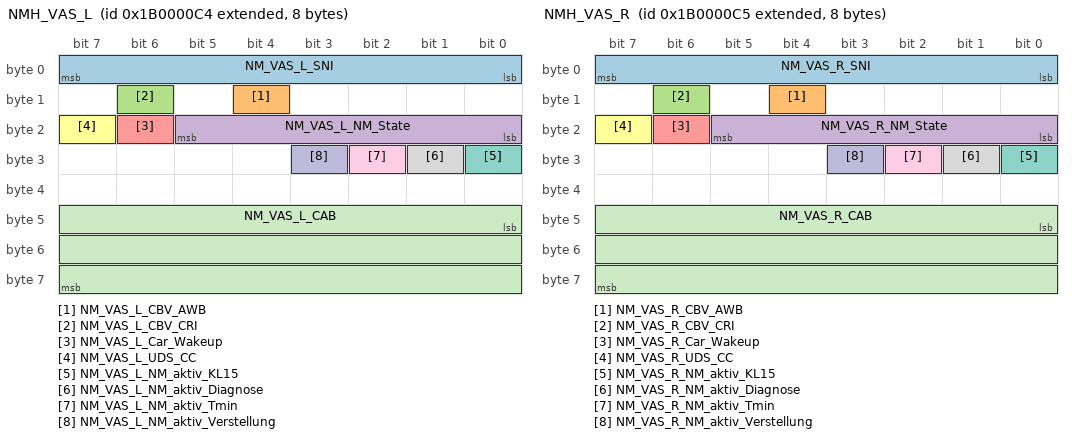
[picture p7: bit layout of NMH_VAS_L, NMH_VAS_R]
BO_ 2600468676 NMH_VAS_L: 8 VAS_L
 SG_ NM_VAS_L_SNI : 0|8@1+ (1.0,0.0) [0.0|255] ""  BCM1,Gateway,Klima_MSB,Lift_VA,VAS_L,VAS_R
 SG_ NM_VAS_L_CBV_AWB : 12|1@1+ (1.0,0.0) [0.0|1] ""  Gateway
 SG_ NM_VAS_L_CBV_CRI : 14|1@1+ (1.0,0.0) [0.0|1] ""  BCM1,Gateway,Klima_MSB,Lift_VA,VAS_L,VAS_R
 SG_ NM_VAS_L_NM_State : 16|6@1+ (1.0,0.0) [0.0|63] ""  Vector__XXX
 SG_ NM_VAS_L_Car_Wakeup : 22|1@1+ (1.0,0.0) [0.0|1] ""  Gateway
 SG_ NM_VAS_L_UDS_CC : 23|1@1+ (1.0,0.0) [0.0|1] ""  Vector__XXX
 SG_ NM_VAS_L_NM_aktiv_KL15 : 24|1@1+ (1.0,0.0) [0.0|1] ""  Vector__XXX
 SG_ NM_VAS_L_NM_aktiv_Diagnose : 25|1@1+ (1.0,0.0) [0.0|1] ""  Vector__XXX
 SG_ NM_VAS_L_NM_aktiv_Tmin : 26|1@1+ (1.0,0.0) [0.0|1] ""  Vector__XXX
 SG_ NM_VAS_L_NM_aktiv_Verstellung : 27|1@1+ (1.0,0.0) [0.0|1] ""  Vector__XXX
 SG_ NM_VAS_L_CAB : 40|24@1+ (1.0,0.0) [0.0|16777215] ""  BCM1,Gateway,Klima_MSB,Lift_VA,VAS_L,VAS_R

BO_ 2600468677 NMH_VAS_R: 8 VAS_R
 SG_ NM_VAS_R_SNI : 0|8@1+ (1.0,0.0) [0.0|255] ""  BCM1,Gateway,Klima_MSB,Lift_VA,VAS_L,VAS_R
 SG_ NM_VAS_R_CBV_AWB : 12|1@1+ (1.0,0.0) [0.0|1] ""  Gateway
 SG_ NM_VAS_R_CBV_CRI : 14|1@1+ (1.0,0.0) [0.0|1] ""  BCM1,Gateway,Klima_MSB,Lift_VA,VAS_L,VAS_R
 SG_ NM_VAS_R_NM_State : 16|6@1+ (1.0,0.0) [0.0|63] ""  Vector__XXX
 SG_ NM_VAS_R_Car_Wakeup : 22|1@1+ (1.0,0.0) [0.0|1] ""  Gateway
 SG_ NM_VAS_R_UDS_CC : 23|1@1+ (1.0,0.0) [0.0|1] ""  Vector__XXX
 SG_ NM_VAS_R_NM_aktiv_KL15 : 24|1@1+ (1.0,0.0) [0.0|1] ""  Vector__XXX
 SG_ NM_VAS_R_NM_aktiv_Diagnose : 25|1@1+ (1.0,0.0) [0.0|1] ""  Vector__XXX
 SG_ NM_VAS_R_NM_aktiv_Tmin : 26|1@1+ (1.0,0.0) [0.0|1] ""  Vector__XXX
 SG_ NM_VAS_R_NM_aktiv_Verstellung : 27|1@1+ (1.0,0.0) [0.0|1] ""  Vector__XXX
 SG_ NM_VAS_R_CAB : 40|24@1+ (1.0,0.0) [0.0|16777215] ""  BCM1,Gateway,Klima_MSB,Lift_VA,VAS_L,VAS_R

CM_ BO_ 1648 "Kombischnittstelle";
CM_ BO_ 1423 "CAN-Botschaft";
CM_ BO_ 967 "MQB - vorher Motor_06 / Umbenennung wg. ID-Wechsel";
CM_ BO_ 1601 "ab MQB mit CRC-8";
CM_ BO_ 1696 "MLBevo ohne KD-Bit";

CM_ SG_ 958 MO_Aussp_Anlass "Das Signal zeigt an, ob die Wiederholstartsperre aktiv ist. D. h. eine Ansteuerung des Anlassers wird auch bei erfüllten Startvoraussetzungen (HS: Interlock betätigt bzw. AT: P/N eingelegt und Bremse betätigt) nicht erfolgen.";
CM_ SG_ 958 MO_BKV_Unterdruckwarnung "Über die Unterdruckwarnung signalisiert das MSG dem ESP, dass kein ausreichender Unterdruck für den BKV zur Verfügung gestellt werden kann.";
CM_ SG_ 958 MO_BLS "Ungefiltertes Rohsignal des Bremslichtschalters, nur wenn HW-Eingang bestückt und ausgewertet wird. Bei Motoren ohne genutzten HW-Eingang wird kein Ersatzwert (bspw. SW-Signal über CAN) ausgegeben!
Bei AUDI muss das Signal wg. Bremslichtfunktion immer be";
CM_ SG_ 958 MO_BMS_NV_Anf_stuetzen "Garantierte Unterstützung des Zusatzspeichers ist erforderlich. Zusatzspeicher muss an das Versorgungsnezt angebunden werden. ";
CM_ SG_ 958 MO_EKlKomLeiRed "Anforderung an die Klimasteuerung, die Leistungsaufnahme des E-Kompressors bei schlechtem SOC und in bestimmten Fahrsituationen zu begrenzen. (Das bereits bestehende Signal 'Klimakompressor aus' als stets umzusetzende Anforderung bleibt unverändert besteh";
CM_ SG_ 958 MO_Ext_E_Fahrt_aktiv "Funktionsrückmeldung zum erw. E-Fahr-Betrieb über Lampe/LED im E-Mode-Taster";
CM_ SG_ 958 MO_Fahrer_bremst "Redundante Bremsinformation vom Motor.

MLB:
AUDI D4: Zykluszeit: 10ms (siehe Zykluszeit schnell/Cycletime Fast)
Im AUDI B8 wird in diesem Bit der Wert der ESP-CAN-Information 'ESP_Fahrer_bremst' ausgegeben.

Achtung:
Reduktion der Zykluszeit Motor";
CM_ SG_ 958 MO_FMAus_aktiv "Das Signal gibt Rückmeldung ob Freilauf Motor aus aktiv ist. Beleibt auch 0km/h (unterhalb der StartStopp Schwelle) weiterhin aktiv.";
CM_ SG_ 958 MO_FMAus_Startvariante "Startvariante beim Motorstart aus der Freilauf-Motor-AUS Phase";
CM_ SG_ 958 MO_Freig_Anlass "Bit wird gesetzt, wenn der Motor beim Automatikstart gestartet werden darf (Motorstillstand, Emissionsmaßnahmen sind erfüllt).";
CM_ SG_ 958 MO_Freig_Reku "Empfehlung des Motor-SG's zur Spannungsabsenkung/-anhebung für den Rekuperationsbetrieb";
CM_ SG_ 958 MO_Freigabe_Segeln "Freigabebit des Segelbetriebs im Getriebe. Bedingt durch bestimmte Diagnosen und Adaptionen des MSGs, die nur im Schub möglich sind, darf nicht jede Schubphase für einen Segelbetrieb genutzt werden. Eine Freigabe bleibt auch außerhalb einer Schubphase bes";
CM_ SG_ 958 MO_Gangposition "MLB:
Stellung des Wählhebels in der Schaltgasse des Handschaltgetriebes.
MLBevo: 
Ausweitung der Bedienung auch auf Automatikgetriebe;
Routing des Signals GE_Fahrstufe: 
1. Position_R (dez. 6) auf MO_Gangposition: Gang_R (dez. 13) wegen Entfall Signa";
CM_ SG_ 958 MO_Handshake_STH "Es gilt: Signalspec MO_Handshake v1.0

Handshake zwischen MSG und STH. Wenn das MSG die EKP aufgrund einer STH-Anforderung ansteuert und kein Fehlereintrag bzgl. EKP/KPE/NDR vorliegt, wird das Bit gesetzt.";
CM_ SG_ 958 MO_HYB_Fahrbereitschaft "Signal steuert u.a. in der Lenkhilfe zusammen mit weiteren Informationen den Modewechsel in den 'Drivemode'
Grüne Anzeige im Kombiinstrument zur Signalisierung der Bereitschaft des Hybridsystems.";
CM_ SG_ 958 MO_HYB_VM_aktiv "0 = VMotor wird nicht aktiv gehalten (nVM < n_min und keine LL-Regelung aktiv)
1 = VMotor aktiv (ab der ersten Einspritzung; gilt auch für Schubbetrieb, wenn VMotor spätestens durch LLRegelung befeuert würde)
Verwendet zur Bestimmung des Ist-Zustandes";
CM_ SG_ 958 MO_Interlock "Das Motorsteuergerät gibt die Information aus, ab wann der Kupplungsschalter durch das Motorsteuergerät als getreten gesehen wird.
Bei Systemen für Start Stopp muss das Interlocksignal für einen Start durch das MSG generiert werden, sobald der Schalthebe";
CM_ SG_ 958 MO_Kickdown "Es gilt: Signalspec MO_Kickdown v1.0";
CM_ SG_ 958 MO_Kl_50 "Klemme 50: Startausführung durch Ritzelstarter

MLB: nicht von allen Motoren gesendet
MQB/MLBevo: gesendet von allen Motoren";
CM_ SG_ 958 MO_Kl_75 "Klemme X
";
CM_ SG_ 958 MO_Klima_Eingr "Eingriffe des Motor bei der Klima";
CM_ SG_ 958 MO_KomFehler_ESP "Anzeige Kommunikationsfehler bei Empfang vom ESP";
CM_ SG_ 958 MO_Konsistenz_Bremsped "MLB:

AUDI D4: Zykluszeit: 10ms (siehe Zykluszeit schnell/Cycletime Fast)
Siehe 'Funktionsspezifikation Bremslichtinfo B8'

Achtung:
Reduktion der Zykluszeit Motor_03 auf 10ms geplant.
Projektabhängig soll künftig mit 10ms gesendet werden.
Empfäng";
CM_ SG_ 958 MO_Kuppl_schalter "MLB:
Das Motorsteuergerät gibt die Information aus, ab wann der Kupplungsschalter durch das Motorsteuergerät als getreten gesehen wird
0x0: Schalter sagt betätigt (Ausgekuppelt)
0x1: Schalter sagt nicht betätigt (Eingekuppelt)

MQB:
Nur Handschalter";
CM_ SG_ 958 MO_Motor_laeuft "Das Motorsteuergerät gibt die Information aus, ab wann der Motor verbrennungsbedingt autark läuft und durch zuschaltbare Nebenaggregate mechanisch belastbar ist (z.B. durch Generator, Klimakompressor, etc.).

Die 'Motor läuft' Information wird ausgegebe";
CM_ SG_ 958 MO_PTC_Status "Status-Rückmeldung vom MSG zum aktuellen PTC-Status (stufiges PTC, Relais am MSG). Bei Ansteuerung eines stufigen PTC durch ein anderes SG beschreibt das Signal die vom MSG freigegebene PTC-Stufe.";
CM_ SG_ 958 MO_QBit_Fahrer_bremst "MLB:
AUDI D4: Zykluszeit: 10ms (siehe Zykluszeit schnell/Cycletime Fast)

Achtung:
Reduktion der Zykluszeit Motor_03 auf 10ms geplant.
Projektabhängig soll künftig mit 10ms gesendet werden.
Empfänger die in weiteren Konzern-Projekten eingesetzt werd";
CM_ SG_ 958 MO_QBit_Gangposition "Qualitätsbit zum Signal MO_Gangposition";
CM_ SG_ 958 MO_QBit_KL_75 "Q - Bit für das KL 75 Signal zur Vermeidung der fehlerhaften Erkennung von Motorstarts. 
Wird auf 1 gesetzt, solange das Motorsteuergerät KL15 = AUS erkannt hat.";
CM_ SG_ 958 MO_Remotestart_Betrieb "Das MSG ist für den Remotestart-Betrieb bereit. Nach Empfang der Motorstartanforderung für RSt-Betrieb durch BCM wird der Fahrzeugmotor gestartet und solange der Motor läuft, bleibt dieses Bit aktiv. Dieses Signal ist nur zur Verwendung durch das BCM zur ";
CM_ SG_ 958 MO_Remotestart_moeglich "Wenn Bit gesetzt, würde das MSG bei entsprechender Anforderung durch das BCM den Remotestartbetrieb einleiten, d.h. das MSG ist remotestartfähig und es liegen aktuell keine relevanten Fehler oder andere Abbruchgründe vor.";
CM_ SG_ 958 MO_Signalquelle_Gangposition "Signalquelle des Signals MO_Gangposition
0: Signalquelle Gangpositionssensor
1: Signalquelle Modellwert (v/n)";
CM_ SG_ 958 MO_StartStopp_Fahrerwunsch "Fahreraktivität Start/Stop";
CM_ SG_ 958 MO_StartStopp_Motorstopp "Motor-Stopp durch Start/Stopp-Koordinator
HYBRID:
Wenn MO_Hybridfahrzeug = 1 gilt:
Verbrennungsmotor durch Hybrid-Koordinator im MSG ausgeschaltet. 
Die definierten Start/Stopp-Signale beziehen sich nur auf den Verbrennungsmotor!";
CM_ SG_ 958 MO_StartStopp_Status "Aktivitätsstatus Start/Stopp-Koordinator
HYBRID:
Wenn MO_Hybridfahrzeug = 1 gilt:
Signal bezieht sich nur auf den Verbrennungsmotor, nicht auf den Hybridantrieb
";
CM_ SG_ 958 MO_StartStopp_Wiederstart "Motorwiederstart durch Start/Stopp-Koordinator
HYBRID:
Wenn MO_Hybridfahrzeug =1 gilt:
Warnung vor Spannungseinbruch beim Zustart des Verbrennungsmotors. 
-nicht relevant, da derzeit kein Start über 12V-Starter geplant-
Dieses Signal wird nur vom Hyb";
CM_ SG_ 958 MO_StartVorauss_erfuellt "Dient der Fallunterscheidung bei ZAT-Betätigung im Zustand 'KL15 ein' (bei nicht gesetztem Signal folgt KL15 aus, bei gesetztem Signal folgt setzen KL50-Anf.)

0: Signal nicht bedient 
1: Voraussetzungen zur Antriebsstrangaktivierung / Startvoraussetzu";
CM_ SG_ 958 MO_Zylinderabschaltung "Status Zylinderabschaltung Motor";
CM_ SG_ 958 Motor_14_CRC "Ab MQB und MLBevo:
'Berechnung siehe Lastenheft 'End-to-End Kommunikationsabsicherung'

Endwerte siehe Begleitdokument 'S-PDU Kennungsfolgen'";

CM_ SG_ 1631 MO_DPF_reg "Regeneration Diesel-Partikel-Filter";
CM_ SG_ 1631 MO_Energieinhalt_BMS "Restenergieinhalt der Traktionsbatterie, beeinflusst durch Fahrstrategie und weiteren Faktoren der Antriebssteuerung.";
CM_ SG_ 1631 MO_Heizstrom_EKAT "Aktuelle Gesamtstromaufnahme des E-Katalysators";
CM_ SG_ 1631 MO_Heizstrom_SCR "Aktuelle Gesamtstromaufnahme der Tank-, Fördermodul- und Leitungsheizung des SCR-Systems";
CM_ SG_ 1631 MO_P_Generator_ungefiltert_Anf "Bei Empfang der Anforderung soll der Sender BEM_P_Generator ungefiltert befüllen.";
CM_ SG_ 1631 MO_SpannungsAnf_02 "Forderung des Motor-SG's zur Spannungsanhebung";
CM_ SG_ 1631 TSK_Fahrzeugmasse_02 "Neue Definition ab D4
Fahrzeugmasse in kg. Das Signal dient der Anpassung der Sollbeschleunigung vom ACC


";
CM_ SG_ 1631 TSK_Grundmasse "Fahrzeuggrundmasse in kg. Das Signal dient der Anpassung der Sollbeschleunigung vom ACC

Hinweis: Ehemaliger Fehlerwert 0x7F wird senderseitig nicht unterstützt. Diesen Wert aus Kompatibilitätsgründen nicht neu belegen!";
CM_ SG_ 1631 TSK_Steigung_02 "Steigung in % Berg. Das Signal dient der Anpassung der Sollbeschleunigung vom ACC

Positive Werte > bergauf; 
Negative Werte < bergab

Fehler: Die Steigung aufgrund eines Fehlers (mit KD-Fehlereintrag) nicht mehr berechnet werden";

CM_ SG_ 812 MO_BZS_Charisma_FahrPr "Rückmeldung des aktuellen Charisma-Fahrprogramms der MSG Betriebsstrategie

MLBevo: Aktuelles Fahrprogramm des Charisma-Teilnehmers (siehe Systemlastenheft Drive Select)
MQB: Istwert der Kennlinie (siehe Systemlastenheft MQB FPA)";
CM_ SG_ 812 MO_BZS_Charisma_Status "Charisma Systemstatus des Charisma-Teilnehmers MSG (Betriebszustände)

Wert 0x3 ist nur für Fahrzeuge ab MQB relevant";
CM_ SG_ 812 MO_Charisma_FahrPr "MLBevo: Aktuelles Fahrprogramm des Charisma-Teilnehmers (siehe Systemlastenheft Drive Select)
MQB: Istwert der Kennlinie (siehe Systemlastenheft MQB FPA)";
CM_ SG_ 812 MO_Charisma_Status "Charisma Systemstatus des Charisma-Teilnehmers

Wert 0x3 ist nur für Fahrzeuge ab MQB relevant";
CM_ SG_ 812 MO_Drehzahlbeeinflussung "Faktor zur Anhebung der Fahrdrehzahl im Warmlauf";
CM_ SG_ 812 MO_Luftpfad_aktiv "Getriebeeingriff wird zusätzlich zum Zündungspfad auch über den Luftpfad umgesetzt, kommt zu MLB neu in die PL48-Getriebe";
CM_ SG_ 812 MO_MAX_Wunschdrehzahl "maximale Motorwunschdrehzahl, die vom Getriebe nicht überschritten werden darf

Signal darf GE_Synchro_Wunschdrehzahl nicht spiegeln";
CM_ SG_ 812 MO_MIN_Wunschdrehzahl "minimale Motorwunschdrehzahl aufgrund Regeneration, die vom Getriebe nicht unterschritten werden darf

Hinweis: 
Ehemaliger Fehlerwert 0xFF wird senderseitig nicht unterstützt. 
Diesen Wert aus Kompatibilitätsgründen nicht neu belegen!";
CM_ SG_ 812 MO_NGS_Position "Messwert des Neutralgangsensors
(nur Handschalter)";
CM_ SG_ 812 MO_NGS_Status "Status des Signals MO_NGS_Position. Das MSG prüft die Plausibilität nur hinsichtlich sicher geöffnetem Triebstrang.";
CM_ SG_ 812 MO_Prio_MAX_Wunschdrehzahl "Prioritätsbit der Motorwunschdrehzahl  als MAX";
CM_ SG_ 812 MO_Prio_MIN_Wunschdrehzahl "Prioritätsbit der Motorwunschdrehzahl als MIN";
CM_ SG_ 812 MO_Rampenzeit_Generator_Anf "Das Motorsteuergerät kann eine Load-Response-Zeit des Generators vom Niedervoltenergiemanagement (NVEM) anfordern. Die Load-Response-Zeit wird vom NVEM umgesetzt, wenn dies bordnetzverträglich möglich ist.";
CM_ SG_ 812 MO_Sperrung_FahrPr_BZS "Sperrung einzelner Betriebszustände bzgl. Kommunikation zwischen Motor-SG und Charisma-SG (Gateway)";
CM_ SG_ 812 MO_StSt_Charisma_FahrPr "MLBevo: Aktuelles Fahrprogramm des Charisma-Teilnehmers (siehe Systemlastenheft Drive Select)
MQB: Istwert der Kennlinie (siehe Systemlastenheft MQB FPA)";
CM_ SG_ 812 MO_StSt_Charisma_Status "Charisma Systemstatus des Charisma-Teilnehmers

Wert 0x3 ist nur für Fahrzeuge ab MQB relevant";
CM_ SG_ 812 MO_v_Begrenz_Aktivierbar "Fehlerbit wird vom Motor-SG gesetzt, wenn dieses nicht in dieGeschwindigkeits-begrenzung gehen kann, ein Fehler während der v-Begrenzung auftritt oder v > v_Begrenzung - v_Delta";
CM_ SG_ 812 MO_v_Begrenzung_Niveau "Zeigt an, ob eine v-Begrenzung aufgrund Anforderung der Niveauregelung  im MSG aktiv ist oder nicht (Signal für Niveau zum Steuern der Kombianzeige).";

CM_ SG_ 1648 MO1_Freigabe_Info_WFS "WFS-Freigabeinformation";
CM_ SG_ 1648 MO1_Freigabe_Verfallsinfo_WFS "WFS-Freigabeverfallsinformation";
CM_ SG_ 1648 MO1_Sperr_Info_WFS "WFS-Sperrinformation";
CM_ SG_ 1648 MO_Abstellzeit "Abstelldauer nach letztem KL15 aus

Hinweis: 
Ehemaliger Fehlerwert 0xFF wird senderseitig nicht unterstützt. 
Diesen Wert aus Kompatibilitätsgründen nicht neu belegen!";
CM_ SG_ 1648 MO_Abstellzeit_Status "Statusinformation zur Abstellzeit
0: Die dem Status zugeordnete Variable konnte noch nicht berechnet werden. 
1: Die dem Status zugehörige Variable wurde korrekt berechnet. 
2: Der Wert der zugehörigen Variablen ist nur ein Minimalwert. 
3: Der Wert d";
CM_ SG_ 1648 MO_ANC_Kennfeld_Anf "Anforderung ANC Kennfeldumschaltung";
CM_ SG_ 1648 MO_Anzahl_Abgesch_Zyl "Gibt die Anzahl der abgeschalteten Zylinder an. In Übergangszuständen wird der Zielbetriebszustand angezeigt.";
CM_ SG_ 1648 MO_Bremslicht_Reku "Bremslicht (ggf. bei Rekuperation durch E-Motor) wird angesteuert";
CM_ SG_ 1648 MO_Drehzahl_Warnung "Warnhinweis zum Kombi im Fall einer fehlerbehafteten Drehzahlbegrenzung";
CM_ SG_ 1648 MO_EPCL "Die Anforderung der EPC-Lampe vom MSG ans Kombi soll durch das Bus-Signal MO_EPCL gemäß folgender Logik erfolgen:
MO_EPCL = 0 dez -> EPC Lampe aus, kein Text
MO_EPCL = 1 dez -> gelbe EPC-Symbolik, Text „Antrieb: Störung! Bitte Service aufsuchen“
MO_EPC";
CM_ SG_ 1648 MO_Ethanol_BS_Texte "Ethanol Brennstoff-Texte im Kombi

0 = kein Text
1 = E85 Warm_Up
2 = FlexFuel Warnung 3.Stufe (Too cold for ethanol)
3 = Warmfahrempfehlung MQB / FlexFuel Warnung 1.Stufe (Refuel with gasoline)
4 = FlexFuel Warnung 2. Stufe (Refuel with gasoline)
5";
CM_ SG_ 1648 MO_Fahrzeugtyp "Unterscheidet die Fahrzeugtypen bzgl. der Antriebsart";
CM_ SG_ 1648 MO_Fehler_Zylabsch "Fehlerstatus der Funktion Zylinderabschaltung ";
CM_ SG_ 1648 MO_Hybrid_StartStopp_LED "Ansteuerung der Funktions-LED der Hybrid Taste bzw. Start/Stop Deaktivierungstaste.
Der Start/Stopp-Master (derzeit im MSG) (oder ein künftiger Hybrid-Master) soll die Ansteuerung senden.";
CM_ SG_ 1648 MO_max_Ladedruck "maximal möglicher Ladedruck (zur Anpassung des Anzeigebereichs bei absoluter Ladedruckanzeige)";
CM_ SG_ 1648 MO_NMAX_Schaltanzeige "Maximaldrehzahl für Schaltanzeige";
CM_ SG_ 1648 MO_obere_Drehzahlgrenze "obere Drehzahlgrenze des Motors";
CM_ SG_ 1648 MO_StartStopp_PopUp "Das Signal zeigt an, ob der StSt-Status mittels Deaktivierungstaster geändert wurde. Ein Wechsel auf die Werte 01 oder 10 löst im Kombi ein entsprechendes PopUp aus. Bei einem Statuswechsel durch andere Signalquellen (z.B. Charisma, fehlerbedingte Abschal";
CM_ SG_ 1648 MO_Zylabsch_Texte "Zylinderabschaltung mode in Kombi, fuer Zylinderabschaltung";
CM_ SG_ 1648 MO_Zylabsch_Texte_02 "ZAS-Anzeige für den Fahrer im Kombi
0: kein ZAS (generell keinerlei ZAS-Anzeigen)  (Init für nicht ZAS-Motor)
1: ZAS im Vollmotorbetrieb  (Init für ZAS-Motor)
2: ZAS im Abschaltbetrieb: 1 Zyl aktiv
3: ZAS im Abschaltbetrieb: 2 Zyl aktiv
4: ZAS im Abs";

CM_ SG_ 289 MO_Entkopplung_Sollschlupf "MSG fordert von GSG an, das Anfahrelement (Fahr-/Wandlerkupplung) zu entkoppeln; das GSG soll die gesendete Drehzahl als Schlupf einstellen und ggf. die Regler-Parameter umschalten, damit Rucke aus dem Antrieb nicht im Fahrzeug spürbar werden; nutzbar z.B";
CM_ SG_ 289 MO_Fahrpedalgradient "Das Motorsteuergerät besitzt 2 analoge Fahrpedalsignale. Das Signal des ersten Kanals wird alle 4ms abgetastet. Um Bitschwankungen des A/D-Wandler herauszufiltern wird das Signal entjittert. Anschließend wird der Gradient berechnet. Entsprechend der Zyklu";
CM_ SG_ 289 MO_Fahrpedalrohwert_01 "AUDI D4: Zykluszeit: 10ms (siehe Zykluszeit schnell/Cycletime Fast)

Stellung des Fahrpedales (Rohwert, ohne Überlagerung durch GRA-Eingriffe etc.)

Die Funktionen zur Berechung des Fahrpedalrohwerts laufen im 10ms Raster. Der Fahrpedalwert berechnet ";
CM_ SG_ 289 MO_Moment_im_Leerlauf "Fahrerwunschmoment ist minimal: keine Momentenanforderung durch Fahrpedal, ACC oder GRA+; (Das Signal ist unabhängig von Momentenerhöhungen durch Leerlaufregler oder MSR).

AUDI D4: Zykluszeit: 10ms (siehe Zykluszeit schnell/Cycletime Fast)

Achtung:";
CM_ SG_ 289 MO_QBit_Fahrpedalwerte_01 "AUDI D4: Zykluszeit: 10ms (siehe Zykluszeit schnell/Cycletime Fast)

QBit für beide Fahrpedalwerte des Motors (Fahrpedalrohsignal für ESP, EPB, ACC; Fahrpedalwert für Getriebe)

Achtung:
Reduktion der Zykluszeit Motor_03 auf 10ms geplant.
Projektabh";
CM_ SG_ 289 MO_rel_Saugrohrdruck "Der Wert gibt an, um wieviel mbar der Saugrohrdruck unterhalb des Umgebungsdrucks liegt. Überdruck im Saugrohr wird nicht ausgegeben.
0: Saugrohrdruck=Umgebungsdruck";
CM_ SG_ 289 MO_rel_Saugrohrdruck_gem_err "0: mind. eine Modellrechnung wird zur Berechnung des relativen Saugdrucks herangezogen
1: Relativer Saugrohrdruck wird ausschließlich über Messgrößen bestimmt";
CM_ SG_ 289 MO_Schubabschaltung "ESP plausibilisiert Unterdrucksensor nur bei aktiver Schubabschaltung

MLBevo:
Signal wird nur in MLBevo Projekten mit PDKII Getriebe bedient. In allen anderen MLBevo Projekten wird das Signal mit '0' bedient
PDKII berücksichtigt Verzugszeiten, die in";
CM_ SG_ 289 MO_Sig_Fahrpedalgradient "Kennzeichnet das Vorzeichen des Signal 'Fahrpedalgradient'. Die Ausgabe erfolgt nur parallel statisch mit gesendetem Signal: 'Steuerungsbit Fahrpedalgradient' ";
CM_ SG_ 289 MO_Solldrehz_Leerlauf "Leerlaufsolldrehzahl, die im Motor eingestellt ist (Bei Parallelhybrid im E-Fahr-Betrieb Leerlaufsolldrehzahl der E-Maschine). Der Motor paßt aufgrund der Anforderung von anderen Steuergeräten seine Leerlaufsolldrehzahl an, bspw. Kat-Heizen, Anforderung v";
CM_ SG_ 289 MO_StartStopp_StoppVorbereitung "Zeigt allen aktiven Start-/Stoppteilnehmern einen möglichen Motorstopp im Anhaltevorgang an (Empfänger notwendige Vorbereitungen treffen)
Es liegen keine Vetos vor.";
CM_ SG_ 289 MO_temporaere_Fahrerabwesenheit "Das Signal dient zur Signalisierung einer temporären Abwesenheit des Fahrers. In dieser Zeit ist es ihm möglich, sich durch gewisse ¿ im Verlassenskonzept definierte ¿ Fahreraktionen im aktuellen Fahrzyklus zurückzumelden.
Das Signal wird gesetzt, sobald";
CM_ SG_ 289 Motor_20_BZ "Botschaft asynchron geroutet. Zählerwert kann springen.";
CM_ SG_ 289 Motor_20_CRC "Für MLB:
'Berechnung siehe Lastenheft 'Kommunikationsabsicherung für FlexRay und CAN''

Ab MQB und MLBevo:
'Berechnung siehe Lastenheft 'End-to-End Kommunikationsabsicherung'

Endwerte siehe Begleitdokument 'S-PDU Kennungsfolgen'";
CM_ SG_ 289 TSK_a_Soll_gradientenbegrenzt "TSK Sollbeschleunigung für Fahrerassistenzsysteme mit aktiver Längsführung (GRA, ACC, IPA...). Der Wert stellt den ruckbegrenzten Sollwert der TSK-Regelung dar und ist Basis der TSK-Antriebs- und Bremsmomentenvorsteuerung.";

CM_ SG_ 1423 MO_ITM_Status "Statusinformationen an TME-Steuergerät bzgl. Thermomanagement";
CM_ SG_ 1423 MO_KJS_LLK_Pos_Summe "Aerodynamisch wirksamer Gesamtöffnungswinkel aller Kühlerlüfter- und LLK-Jalousiesteller.

Pos_Frontendverschl_ungenau = 15 zeigt eine Fehlfunktion bzw. unbekannte Position einer oder mehrere Jalousiesteller an.";
CM_ SG_ 1423 MO_Kuehlmittel_Temp_Rohwert "Rohwert Kuehlmitteltemperatur
Das Signal wird derzeit von Diesel-Projekten nicht bedient.";
CM_ SG_ 1423 MO_Oel_Temp_Radsatz "Öltemperatur in PDK Radsatz ";
CM_ SG_ 1423 MO_Tankdruck "Tank Über-/Unterdruck wird für Ansteuerintensität der Treibstoffpumpe der Standheizung benötigt.";

CM_ SG_ 967 MO_E_Mode "Anforderung der E-Mode Statusanzeige";
CM_ SG_ 967 MO_E_Texte "Anforderung von Hinweistexten des E-Systems separat für HEV/BEV bzw. erweiterbar für PHEV";
CM_ SG_ 967 MO_E_Warnungen "Anforderung von Warnanzeigen des E-Systems separat für HEV/BEV bzw. erweiterbar für PHEV";
CM_ SG_ 967 MO_EFLEX_Lampe "Um ein Starten mit E100 zu ermöglichen, wird Kraftstoff ggf. vorgeheizt. Das Signal dient der Anzeige des Heizungsstatus.

Heizung aus -> Lampe aus
Heizung ein -> Lampe ein
Heizung ein und Startversuch -> Lampe blinkend
Heizung nicht möglich -> Lampe";
CM_ SG_ 967 MO_Heissleuchte "Ansteuerung der Kühlwassertemperatur-Heißleuchte (Sensor nur noch am Motorsteuergerät): Temperaturschaltschwellen mit Hysterese (bei VW D1/Colorado Kombi derzeit noch nicht genutzt).";
CM_ SG_ 967 MO_ITM_Warnung_Pumpe "Textanzeige: 'Motor sofort abstellen, geschaltete Wasserpumpe defekt / klemmt'";
CM_ SG_ 967 MO_KJS_nicht_bereit "Dieses Signal zeigen einen Fehler der Kühlerjalousie mit unbekannter Stellung der Lamellen. ";
CM_ SG_ 967 MO_Kuehlerluefter_1 "Ansteuertastverhaeltnis (PWM) der Kuehlerluefterendstufe 1";
CM_ SG_ 967 MO_Kuehlerluefter_2 "Ansteuertastverhaeltnis (PWM) der Kuehlerluefterendstufe 2";
CM_ SG_ 967 MO_Kuehlerluefter_MUX "Multiplexer für das Signal 'MO_Kuehlerlüfter'";
CM_ SG_ 967 MO_OBD2_Lampe "OBD bzw. MIL-Lampe wird vom Motorsteuergerät angesteuert, die Information im Signal GE_OBD_Status wird vom Motorsteuergerät an das Kombi weitergereicht";
CM_ SG_ 967 MO_Oelwarnung_max "Ölstandswarnung mit der Aufforderung zum Ölwechsel.
Hintergrund: Bei Kraftstoffeintrag (B20) ins Öl verbleibt der RME-Anteil irreversibel im Öl.";
CM_ SG_ 967 MO_Partikel_Lampe "Partikelfilter-Lampe wird eingeschaltet";
CM_ SG_ 967 MO_RedFahrleistung_Lampe "Ansteuerung der Turtle-Mode Lampe für E-Traktion Fahrzeuge";
CM_ SG_ 967 MO_Systemlampe "EGas Systemlampe (EPC) oder Vorglühlampe im Kombi, Kombi steuert immer gleiche
LED an, nur über Ziffernblatt wird die EPC von der Vorglühlampe differenziert";
CM_ SG_ 967 MO_Tankdeckel_Lampe "Ansteuerung Tankdeckel-Warnlampe Kombiinstrument (nur Ottomotoren) z.Zt. Vorhalt VW";
CM_ SG_ 967 MO_Text_Motorstart "Anzeigetexte für Start/Stopp und Motor-Start
0xB Fehler_Kupplungsschalter nur für PAG-MLB";
CM_ SG_ 967 MO_Text_Partikelfil_Reg "Über dieses Bit im Kombi wird ein Klartextanzeige erzeugt werden: 'Partikelfilter benötigt Regeneration'.
";
CM_ SG_ 967 MO_Text_Tankdeckelwarn "Textbit der Tankdeckelwarnung, z.Zt. Vorhalt VW";
CM_ SG_ 967 MO_Vorglueh_Lampe "Vorglühlampe im Kombi, Kombi steuert immer gleiche LED an. 
Mit Einführung des Einheits-Kombis sind getrennte Signalwege für Vorglühlampe und EPCL notwendig.";
CM_ SG_ 967 MO_Zustand_HWP "Rückmeldung des  Ansteuerzustand der Hauptwasserpumpe an das Klima-SG .
Der Zustand 'HWP fördert' wird übermittelt, wenn die Schaufeln der Hauptwasserpumpe frei drehen können und die Motordrehzahl und damit die Wasserpumpendrehzahl größer als Null ist. B";
CM_ SG_ 967 OLEV_Oelstand_nicht_vorhanden "Kein aktueller Ölstand vorhanden";
CM_ SG_ 967 OLEV_Systemstoerung "Systemstörung im Ölsystem";
CM_ SG_ 967 WIV_Anzeige_aktiv "Peilstabsanzeigefunktion aktiv";
CM_ SG_ 967 WIV_laufender_Motor "Messung bei laufendem Motor nicht möglich";
CM_ SG_ 967 WIV_nachfuellanzeige_ein "Steuert das Aufblenden der Nachfüllanzeige im Kombi, nach Klemme 15 ein und geöffneter Motorhaube";
CM_ SG_ 967 WIV_nicht_betriebswarm "Motor nicht betriebswarm, Messung ungenau";
CM_ SG_ 967 WIV_Oeldr_Warn_Motor "Löst im Kombiinstrument die rote Prio1-Öldruckwarnung (inkl. 3xBeep) aus.
nur MLB: die Warnauslösung erfolgt nur bei gleichzeitig gesetztem 'WIV_Enable_Oeldr_Motor'";
CM_ SG_ 967 WIV_Oeldyn_avl "Ölstand aus dynamischer Messung vorhanden";
CM_ SG_ 967 WIV_Oelmenge "Ölmenge zwischen Min und Max";
CM_ SG_ 967 WIV_Oelmin_Warn "Signal gibt an wenn der Ölstand die Min-Schwelle unterschritten hat";
CM_ SG_ 967 WIV_Oelstand "8 Segmente zur Balkenanzeige des Ölstands";
CM_ SG_ 967 WIV_Oelstand_nicht_vorhanden "Kein aktueller Ölstand vorhanden";
CM_ SG_ 967 WIV_Oelsystem_aktiv "Gesamtölsystem aktiv (entspricht Ölsensor verbaut) und das Ölstand-Untermenu im MMI aktiv";
CM_ SG_ 967 WIV_Schieflage "Fahrzeug steht nicht waagerecht, Messung ungenau";
CM_ SG_ 967 WIV_Sensorfehler "Ölstand/Öltemperatursensor (TOG) defekt";
CM_ SG_ 967 WIV_Ueberfuell_deaktiv "Unterdrückung der Warnung im Kombi die durch Signal WIV_Ueberfuel_Warn ausgelöst wird";
CM_ SG_ 967 WIV_Ueberfuell_Warn "Ölstand hat die Überfüllschwelle überschritten";
CM_ SG_ 967 WIV_Unterfuell_Warn "Ölstand hat die Unterfüllschwelle unterschritten";

CM_ SG_ 340 MO_Drehzahl_VM "Motordrehzahl des Verbrennungsmotors

für OBD freeze frame

Hinweis: 
Ehemaliger Fehlerwert 0xFFFF wird senderseitig nicht unterstützt. 
Diesen Wert aus Kompatibilitätsgründen nicht neu belegen!";
CM_ SG_ 340 MO_Fehlerstatus_Antrieb_FDR "Fehlerstatus Antrieb - FDR";
CM_ SG_ 340 MO_IstMoment_VKM "Ist-Moment des Verbrennungsmotors

einheitenloser Wert! MO_Faktor_Momente_02 in Motor_Code_01 berücksichtigen!";
CM_ SG_ 340 MO_Mom_Begr_Schalt "Einheitenloser Wert! Faktor in MO_Faktor_Momente (CAN V6.x) bzw. MO_Faktor_Momente_02 (CAN V7.x/8.x) in Motor_Code_01 beachten!

Bei aktueller Drehzahl kurzfristig (ca. 100..200 ms) für momentenerhöhende Getriebeeingriffe max. zur Verfügung stehendes Ge";
CM_ SG_ 340 MO_Mom_Begr_Schalt_Min "Bei aktueller Drehzahl im nächsten Task (im VKM Umsetzung zur nächsten möglichen Verbrennung) minmal stellbares Moment (Summe aus Verbrennungsmotor und E-Motor) aufgrund Momenten-Reduzierungs-Anforderung durch reduzierenden Getriebeeingriff.
Berücksichti";
CM_ SG_ 340 MO_Primaerachse_Anforderung "Das Signal dient der Steuerung der Primärachse.

In Start/Stopp bzw. MHEV-Projekten soll zum Starten der VKM im Stillstand (ohne Fahrerwunsch) die Getriebekupplung geöffnet werden um den VKM-Start ohne 'Ruck' im Fahrzeug auszuführen. Vor dem VKM-Start w";
CM_ SG_ 340 Motor_28_BZ "Botschaft asynchron geroutet. Zählerwert kann springen.";
CM_ SG_ 340 Motor_28_CRC "Für MLB:
'Berechnung siehe Lastenheft 'Kommunikationsabsicherung für FlexRay und CAN''

Ab MQB und MLBevo:
'Berechnung siehe Lastenheft 'End-to-End Kommunikationsabsicherung''

Endwerte siehe Begleitdokument 'S-PDU Kennungsfolgen'";

CM_ SG_ 283 MO_EBoost_verf_praed "Zeigt an, ob für eine im Projekt definierte Zeit (max. 10s) E-Boost in Höhe von EM1_maxPred_Moment verfügbar sein wird.

0 - Init_oder_nicht_verfügbar
1 - EBoost_kurzzeit_verfügbar (~3Sek.)
2 - EBoost_langzeit_verfügbar (~10Sek)";
CM_ SG_ 283 MO_eLaunch_verf "Zeigt an, ob aus Antriebssicht E-Launch verfügbar ist.";
CM_ SG_ 283 MO_Fahrbereitschaft "Das Signal MO_Fahrbereitschaft zeigt in mehreren Stufen an, ob der Motor in einem anfahrbereiten Zustand ist.";
CM_ SG_ 283 MO_Freilauf_Info "Freilauf Informationssignal vom Motorsteuergerät zum Getriebesteuergerät. Das Motorsteuergerät kann über dieses Signal den Freilauf freigeben, verhindern bzw. explizit anfordern.";
CM_ SG_ 283 MO_Freilauf_Status "Freilauf-Status-Signal vom Frailauf-Master an aktive Freilauf-Teilnehmer. In diesem Signal zeigt der Freilauf-Master an, welchen aktuellen Status die Freilauf-Betriebsstrategie hat.";
CM_ SG_ 283 MO_Heckspoiler_Anf "Anforderung den Heckspoiler zur Ladeluft- bzw. Motorraumkühlung auszufahren.";
CM_ SG_ 283 MO_Krit_Heckobjekt "Beschreibt die Kritikalität des hinter einem in der Spur fahrenden Fahrzeuges";
CM_ SG_ 283 MO_NGS_Gangpos "Gang- bzw. Neutralinformation des erweiterten Neutralgangsensors. Bedingt durch den eingeschränkten Erfassungssbereich des Sensors sind die Ganginformationen als eingelegt bzw. fast eingelegt/vorausgewählt zu interpretieren (nur Handschalter)";
CM_ SG_ 283 MO_Parken_WFS_Status "Gesammelte Rückmeldung des Limitierungsstatus aller EM in einem vom ZFAS angeforderten Parkvorgang.";
CM_ SG_ 283 MO_Positionierung_aktiv "Zeigt an, dass die Motorpositionierung mit Hilfe des Riemenstartergenerator momentan aktiv ist.";

CM_ SG_ 1601 MO_Ansaugsystem "Art des Ansaugsystems des Verbrennungsmotors";
CM_ SG_ 1601 MO_Anzahl_Zyl "Zylinderzahl des Verbrennungsmotors";
CM_ SG_ 1601 MO_Anzeige_StSt_gueltig "Zeigt die Gültigkeit der neuen StSt-Anzeigesignale an, MO_Anzeige_StSt_Text und  MO_Anzeige_Symbol. Mo_Text_Motorstart 1..5 sind zu ignorieren.";
CM_ SG_ 1601 MO_Code "Motorcodierinformation Version 11 (Details siehe Anhang)";
CM_ SG_ 1601 MO_DPF_verbaut "Verbauinformation Diesel-Partikel-Filter
";
CM_ SG_ 1601 MO_Faktor_Momente_02 "Dieses Signal schaltet den Wertebereich aller Momente vom Motor, Getriebe, TSK, Bremse ... um! Die Momente besitzen somit einen variablen Wertebereich, weil sich durch den Faktor die Momente sowohl in Auflösung als auch Maximalwerten ändert.

0x0 nicht ";
CM_ SG_ 1601 MO_Getriebe_Code "Getriebecodierung des Motors";
CM_ SG_ 1601 MO_Hubraum "Hubraum des Verbrennungsmotors";
CM_ SG_ 1601 MO_Hybridfahrzeug "Anhand dieses Signals plausibilisiert die Lenkhilfe das Bit Fahrbereitschaft.

Im Projekt Cayenne PHEV (und ggf. auch VW526 PHEV) ist aus Gründen der Abwärtskompatibilität der Wert '2' zu senden.";
CM_ SG_ 1601 MO_Kraftstoffart "Primärkraftstoff zum Antrieb des Fahrzeugs";
CM_ SG_ 1601 MO_Leistung "Nennleistung des Verbrennungsmotors";
CM_ SG_ 1601 MO_OBD_Typ "Abgastyp OBD";
CM_ SG_ 1601 MO_StartStopp_Codiert "Funktion StartStopp im aktuellen Klemmenzyklus verbaut";
CM_ SG_ 1601 Motor_Code_01_CRC "Für MLB:
'Berechnung siehe Lastenheft 'Kommunikationsabsicherung für FlexRay und CAN''

Ab MQB und MLBevo:
'Berechnung siehe Lastenheft 'End-to-End Kommunikationsabsicherung''

Endwerte siehe Begleitdokument 'S-PDU Kennungsfolgen'";
CM_ SG_ 1601 TSK_Codierung "Information über den plausibilisierten Codierungszustand des Triebstrangskoordinators auf ACC oder GRA.";

CM_ SG_ 394 MO_Ablaufstatus "aktueller Status bezüglich der Ausführung des Sollzustand

detaillierte Beschreibung der einzelnen Übergänge ist in der aktuellsten Version des Lastenhefts 'Funktionslastenheft Betriebsartenkoordination bei elektrifizierten Fahrzeugen_Vxx' zu entnehmen";
CM_ SG_ 394 MO_Ablaufstrg_Betriebszustand "Istzustand Betriebsbereitschaft

1 = Betriebsbereitschaft bedeutet: Alle Komponenten sind betriebsbereit. Fahrzeug kann kein Vortriebsmoment erzeugen.

2 = Fahrbetrieb bedeutet: Fahrzeug kann Vortriebsmoment erzeugen.";
CM_ SG_ 394 MO_Ablaufstrg_Kraftschluss2_Ist "Istzustand des Kraftschlusses der Sekundärachse in der Hybridablaufsteuerung (z.B. el. Hinterachse im B9 eQuattro).
Dieses Signal entspricht nicht einem physikalischen Zustand, sondern den Istzustand der Ablaufsteuerung.

Das Signal darf nur ausgwertet";
CM_ SG_ 394 MO_Ablaufstrg_Kraftschluss2_Ziel "Zielstatus des Kraftschlusses der Sekundärachse in der Hybridablaufsteuerung (z.B. el. Hinterachse im B9 eQuattro).
Mit dem Bit soll das Getriebe Kraftschluss herstellen oder den Kraftschluss unterbrechen.

Das Signal darf nur ausgwertet werden, wenn '";
CM_ SG_ 394 MO_Ablaufstrg_Kraftschluss_Ist "Istzustand des Kraftschlusses in der Hybridablaufsteuerung.
Dieses Signal entspricht nicht einem physikalischen Zustand, sondern den Istzustand der Ablaufsteuerung.

Das Signal darf nur ausgwertet werden, wenn 'MO_Ablaufstrg_Betriebszustand' eine Betri";
CM_ SG_ 394 MO_Ablaufstrg_Kraftschluss_Ziel "Zielstatus des Kraftschlusses in der Hybridablaufsteuerung.
Mit dem Bit soll das Getriebe Kraftschluss herstellen oder den Kraftschluss unterbrechen.

Das Signal darf nur ausgwertet werden, wenn 'MO_Ablaufstrg_Betriebszustand' eine Betriebsbereitschaft";
CM_ SG_ 394 MO_Ablaufstrg_Zustand_K0_Ist "Iststatus der K0 Kupplung in der Hybridablaufsteuerung.
Dieses Signal entspricht nicht einem physikalischen Zustand, sondern den Istzustand der Ablaufsteuerung.

Das Signal darf nur ausgwertet werden, wenn 'MO_Ablaufstrg_Betriebszustand' eine Betriebsb";
CM_ SG_ 394 MO_Ablaufstrg_Zustand_K0_Ziel "Zielstatus der K0 Kupplung in der Hybridablaufsteuerung
K0 Steuerung im Motorsteuergerät:
- Infobit an das Getriebe, dass K0 jetzt geschlossen wird
K0 Steuerung durch anderes Steuergerät:
- Bit um dem anderen SG mitzuteilen, dass dieses die K0 schlies";
CM_ SG_ 394 MO_Ablaufstrg_Zustand_VKM_Ist "Istzustand VKM
Dieses Signal entspricht nicht einem physikalischen Zustand, sondern den Istzustand der Ablaufsteuerung.

Das Signal darf nur ausgewertet werden, wenn 'MO_Ablaufstrg_Betriebszustand' eine Betriebsbereitschaft signalisiert.";
CM_ SG_ 394 MO_Ablaufstrg_Zustand_VKM_Ziel "Zielzustand VKM
Dieses Signal entspricht nicht einem physikalischen Zustand, sondern den Zielzustand der Ablaufsteuerung.

Das Signal darf nur ausgewertet werden, wenn 'MO_Ablaufstrg_Betriebszustand' eine Betriebsbereitschaft signalisiert.";
CM_ SG_ 394 MO_Abstellposition_02 "Winkelabstand (in °KW) des sog. Zielzylinders von seinem ZOT (bspw. nötig um Startmoment bei Schleppstart zu berechnen)

255 = Abstellposition kann nicht genau bestimmt werden (bspw. Rückdrehen des Motors)";
CM_ SG_ 394 MO_Auth_Aufforderung_WFS "WFS-Anforderung für Hybridumfänge";
CM_ SG_ 394 MO_HYB_Adaption_aktiv "Motor fordert Sondermaßnahmen vom Getriebe PDK2 (gültig nur für Hybridprojekte)
Das Signal wird im PDKII dazu verwendet, die Fahrkupplungen bei einem Momentenadaptionswunsch der K0-Trennkupplung nicht zu befüllen";
CM_ SG_ 394 MO_HYB_E_Faktor "Signed Nibble, verwendet vom GSG zur Interpolation zwischen VMKennfeld und dem Rekuperations-Grenzkennfeld (negative Werte des E-Faktors) bzw. dem Boost-Grenzkennfeld (positive Werte des E-Faktors).
0000 = VM-Kennfeld (keine Interpolation)
0001..0111 = ";
CM_ SG_ 394 MO_HYB_EMode_Info "Hybrid-Mode der Motorsteuerung zur Beeinflussung der Schaltkennfelder im Getriebe. Nicht-Hybridfahrzeuge senden den Initwert.";
CM_ SG_ 394 MO_HYB_LowSpeedModus "MSG legt fest:
0 = klassisches Ausrollen/Anfahren mit N_mot >= N_Leerlauf_VM
1 = elektr. Ausrollen/Anfahren mit geschl. Triebstrang mit N_mot < N_Leerlauf_VM";
CM_ SG_ 394 MO_HYB_Stoppmodus "Hybridsteuerung zeigt an, auf welche Weise gestoppt werden soll.";
CM_ SG_ 394 MO_Mom_Freiheit_Sekundaerachse "Signalisiert die Momentenfreiheit der Sekundärachse und ist damit Voraussetzung für das Abkoppeln.";
CM_ SG_ 394 MO_Nachlaufzeit_Kuehlerluefter "Nachlaufzeit Kühlerlüfter MSG für Verwendung im TME SG";
CM_ SG_ 394 MO_Start_Art "Beschreibt Art des Starts näher 

Schlupfstart kann entweder Momentenvorhalt oder Impulsstart sein oder eine Kombination aus beidem.";
CM_ SG_ 394 MO_Start_Dynamik "Zeigt die Start-Variante bzw. Start-Dynamik eines VKM-Starts an";
CM_ SG_ 394 MO_Tankklappensteuerung "Ansteuerungsanforderung der Tankklappe";

CM_ SG_ 1156 ND_GDOP "geometric dilution of precision (Gesamtgenauigkeit, 3D und Zeit) 
";
CM_ SG_ 1156 ND_HDOP "horizontal dilution of precision (Horizontalrichtung, 2D)
";
CM_ SG_ 1156 ND_Heading "Fahrtrichtung";
CM_ SG_ 1156 ND_Init "Initialisierung";
CM_ SG_ 1156 ND_PDOP "positional dilution of precision (Positionsgenauigkeit, 3D) 
";
CM_ SG_ 1156 ND_TDOP "time dilution of precision (Zeitgenauigkeit)
";
CM_ SG_ 1156 ND_VDOP "vertical dilution of precision (Vertikalrichtung, 1D)
";

CM_ SG_ 1157 ND_SatInUse "Anzahl der zur Berechnung verwendeten Satelliten";
CM_ SG_ 1157 ND_SatInView "Anzahl der sichtbaren Satelliten";
CM_ SG_ 1157 ND_UTC "UTC-Zeit, verstrichene Sekunden seit 01.01.1970 00:00
0xFFFFFFFE = Init
0xFFFFFFFF = Fehler bei Berechnung der UTC-Time";
CM_ SG_ 1157 NP_Altitude "Hoehe ueber NN
0xFFF = Fehler bei der Berechnung der Höhe über NN";

CM_ SG_ 2527679512 ND_Fuelstation_detected "Signal gibt an ob eine Tankstelle erkannt wurde";
CM_ SG_ 2527679512 ND_NrSameMeasure "GPS Anzahl der gleichen Messungen";
CM_ SG_ 2527679512 ND_RecDelay "Für MLBevo:
Zeit in ms zwischen zwei Interruptauslösungen des GPS Receiver.

Für MLBevoGen2:
Zeit in ms zwischen UTC-Sekunde und Messzeitpunkt des GPS Receiver.";
CM_ SG_ 2527679512 ND_RouteType "Routentyp.";
CM_ SG_ 2527679512 ND_SendDelay "Zeit in ms zwischen Interruptauslösung GPS Receiver (Beginn der Messung) und Senden auf den CAN Bus.";
CM_ SG_ 2527679512 ND_TimeOffset "Offset zu ND_TimeToDestination.";
CM_ SG_ 2527679512 ND_TimeToDestination "Zeit in min bis zum Erreichen des Ziel. Wird ausgegeben bei aktiver Routenführung oder bei gelernter Route (MPR).";
CM_ SG_ 2527679512 ND_Timezone_DaylightSavingOffset "Offest der Sommerzeit/Winterzeit
 
0 = kein Offset ; 
1 = 0,5h;  
2 = 1h";
CM_ SG_ 2527679512 ND_Timezone_Offset "Aktuelle Zeitzonen-Offset des Fahrzeugs.
Vorzeichen und Gültigkeit beachten";
CM_ SG_ 2527679512 ND_Timezone_SignBit "Vorzeichen des Zeitzonenoffsets.";
CM_ SG_ 2527679512 ND_Timezone_Validity "Gültigkeit des Zeitzonensignals.";
CM_ SG_ 2527679512 ND_Velocity "GPS Geschwindigkeit";

CM_ SG_ 1158 NP_LatDegree "Latitude (Nord-Süd Wert)";
CM_ SG_ 1158 NP_LatDirection "Hemisphäre Nord/Süd";
CM_ SG_ 1158 NP_LongDegree "Longitude (Ost-West Wert)";
CM_ SG_ 1158 NP_LongDirection "Hemisphäre Ost/West";
CM_ SG_ 1158 NP_Sat "Nummer der verwendeten Sateliten beim letzten Fix";

CM_ SG_ 2589283496 POS_Heading "Heading of current position
MUX(1)";
CM_ SG_ 2589283496 POS_Heading_Trust "Vertrauenswert Heading 
MUX(1) ";
CM_ SG_ 2589283496 POS_Last_GPS_Sync "Letztes bekannte GPS Sync in [s]
MUX(1)";
CM_ SG_ 2589283496 POS_LatDegree "latitude - position data of navigation
MUX(0)";
CM_ SG_ 2589283496 POS_LatDirection "latitude direction nav position
MUX(0)";
CM_ SG_ 2589283496 POS_LongDegree "long - position data of navigation
MUX(0)";
CM_ SG_ 2589283496 POS_LongDirection "longitude direction nav position
MUX(0)";
CM_ SG_ 2589283496 POS_MUX "Multiplex-Signal zum schalten des Signals der Positionen von der Navigation.
MUX(0/1)";
CM_ SG_ 2589283496 POS_ODD_EVEN "Synchronisation der MUX Pos Signale
MUX(0/1)";
CM_ SG_ 2589283496 POS_PosStati "Aktueller Status der Navgation:
MUX(0)
0   init
1   no nav available (ready_4_nav)
2   no map available (sd_removed, not_enabled)
3   nav booting
4   nav error
5   nav calibrating
6   nav no gps resync since 1h
7   nav offroad  parkgarage ramp of";
CM_ SG_ 2589283496 POS_UTC_REF "Zeitstempel der Nav
MUX(1)

UTC-Zeit, verstrichene Sekunden seit 01.01.1970 00:00
0xFFFFFFFE = Init
0xFFFFFFFF = Fehler bei Berechnung der UTC-Time";

CM_ SG_ 2527679647 NFC_aktiv "NFC-Gerät erkannt";
CM_ SG_ 2527679647 NFC_ESM_aktivieren "Energiesparmodus aktivieren, da z.B. Batterie kritisch";
CM_ SG_ 2527679647 NFC_Front_Entr_Authorisiert "Erkennung / Authorisierung NFC-Handy Front";
CM_ SG_ 2527679647 NFC_Front_Verr_Authorisiert "Erkennung / Authorisierung NFC-Handy Front";
CM_ SG_ 2527679647 NFC_FT_Entriegelung_Authorisiert "Erkennung / Authorisierung NFC-Handy FT
";
CM_ SG_ 2527679647 NFC_FT_Verriegelung_Authorisiert "Authorisierung Verriegelungssensor NFC-Handy FT";
CM_ SG_ 2527679647 NFC_HD_Entriegelung_Authorisiert "Erkennung / Authorisierung NFC-Handy Heck";
CM_ SG_ 2527679647 NFC_HD_Verriegelung_Authorisiert "Autorisierung der Schließanforderung über NFC-Handy";
CM_ SG_ 2527679647 NFC_Laden_unterbrechen "Kommunikation zur Phonebox, das Laden zu unterbrechen";
CM_ SG_ 2527679647 Stellgliedtest_NFC "Applikationssignal um NFC Stellgliedtest abzubilden";
CM_ SG_ 2527679647 ZV_auf_NFC "ZV Schliessstelle";
CM_ SG_ 2527679647 ZV_zu_NFC "ZV Schliessstelle";

CM_ SG_ 1696 NV_Akt_Status_MMI "Zustand des Nightvison Systems im MMI: Warnalgo & NV-Reiter Ein/Aus

";
CM_ SG_ 1696 NV_aktiv "Nightvision aktiviert (liefert Bild)";
CM_ SG_ 1696 NV_Akustik_deaktiviert_Icon "Ansteuerungssignal für das  Akustik-deaktiviert-Icon";
CM_ SG_ 1696 NV_Anf_Prefill "Anforderung an ESP, dass die Prefill-Funktion aktiviert werden soll.";
CM_ SG_ 1696 NV_AnforderungBildaufschaltung "Automatische Bildaufschaltung im Warnfall";
CM_ SG_ 1696 NV_FAS_Fkt_Status "Signal für FAS Profile-Master";
CM_ SG_ 1696 NV_FGM_deaktiviert_Icon "Ansteuerungssignal für das  Fussgängermarkierung-deaktiviert-Icon";
CM_ SG_ 1696 NV_Gong "Das Signal löst einen Gong des NightVision-Systems im Kombidisplay aus";
CM_ SG_ 1696 NV_HBA_Parameter "Anforderung an ESP, welcher HBA-Parametersatz verwendet werden soll. Die Festlegung der Empfindlichkeitsschwellen der verschiedenen Parametersätze erfolgt mit der Applikation des Gesamtsystems ESP/ACC bzw. des HBA.
Nur Audi B8: Umsetzung der Anforderung ";
CM_ SG_ 1696 NV_Hinweise "Das Signal dient dazu Hinweistexte in das NightVision Bild im Kombiinstrument einzublenden.Die Anzeigedauer der Hinweistexte ist Signalgesteuert. D.h., sie werden angezeigt bis das CAN-Signal s_NV_Texte seinen Wert ändert.";
CM_ SG_ 1696 NV_LED_Leiste "Ansteuerung_LED_Warnleiste";
CM_ SG_ 1696 NV_Markierungslicht_links "Das Signal steuert die Aktivierung des Markierungslicht links bei Fußgängerwarnung";
CM_ SG_ 1696 NV_Markierungslicht_rechts "Das Signal steuert die Aktivierung des Markierungslicht rechts bei Fußgängerwarnung";
CM_ SG_ 1696 NV_Piktogramm_aktiv "Signal sagt, dass das Piktogramm im NightVision-Reiter geändert werden soll";
CM_ SG_ 1696 NV_PreSense_Modus_System "Signal zur Realisierung der BAP-Kommunikation für PreSense";
CM_ SG_ 1696 NV_PreSense_Modus_Warnung "Signal zur Realisierung der BAP-Kommunikation für PreSense";
CM_ SG_ 1696 NV_PreSense_Status "Signal zur Realisierung der BAP-Kommunikation für PreSense";
CM_ SG_ 1696 NV_Symbol "Wenn das NV-System einen Fußgänger findet, fordert es mit dem Signal das HUD auf, ein Symbol zu zeigen";
CM_ SG_ 1696 NV_Symbol_Tierwarnung "Signal zur Anforderung einer Symbolanzeige für Tierwarnung.";
CM_ SG_ 1696 NV_Texte "Angeforderte Textmeldung";

CM_ SG_ 2600468494 NM_BCM1_CAB "CAB = Clusteraktivbits";
CM_ SG_ 2600468494 NM_BCM1_Car_Wakeup "Car Wakeup (Gateway wertet aus)
MQB: 
Kl.58xd, Kl.58xs, Kl.58xt eingeschaltet oder ausgeschaltet oder Dimmungssignal wurde vom Kunden geändert (nicht vom Fototransistor); S-Kontakt wurde ein- oder ausgeschaltet; Remotestartbetrieb; Tankklappe wurde gesc";
CM_ SG_ 2600468494 NM_BCM1_CBV_AWB "Das Signal ist zu setzen, wenn das SG aktiv den Bus geweckt hat";
CM_ SG_ 2600468494 NM_BCM1_CBV_CRI "Das Signal ist dauerhaft gesetzt, wenn das NM-Layout dem neuen NM-Layout für Teilnetzbetrieb entspricht";
CM_ SG_ 2600468494 NM_BCM1_NM_aktiv_Aussenlicht "Funktionsnachlauf Außenlicht (inkl. Blinken, Warnblinken, Lichthupe)";
CM_ SG_ 2600468494 NM_BCM1_NM_aktiv_ComingHome "ComingHome aktiv, max. 120s";
CM_ SG_ 2600468494 NM_BCM1_NM_aktiv_Diagnose "Diagnose befindet sich nach VW80124 in einer NonDefaultDiagnostic-Session, z.B. ExtendedDiagnostic-Session";
CM_ SG_ 2600468494 NM_BCM1_NM_aktiv_Innenlicht_Dim "Innenlicht, 58xst_xt_xd, 58xt_Ende, Vers.Kl.30G";
CM_ SG_ 2600468494 NM_BCM1_NM_aktiv_KL15 "Steuergerät hat KL15-EIN erkannt";
CM_ SG_ 2600468494 NM_BCM1_NM_aktiv_Klimatisierung "Aktiv aufgrund Klimatisierung";
CM_ SG_ 2600468494 NM_BCM1_NM_aktiv_LeavingHome "LeavingHome aktiv, max. 60s
Annaeherungslicht";
CM_ SG_ 2600468494 NM_BCM1_NM_aktiv_LIM "Aktiv aufgrund Lichtinnenmodul";
CM_ SG_ 2600468494 NM_BCM1_NM_aktiv_Notlaufblinken "Notlaufblinken bei Ausfall BCM2";
CM_ SG_ 2600468494 NM_BCM1_NM_aktiv_Taster_Schalter "Warnblink-Taster, Scheinwerferdiebstahlueberwachung, Display-Taster, Valet-Taster, Motorhaubenkontakt, SPR";
CM_ SG_ 2600468494 NM_BCM1_NM_aktiv_Tmin "Mindestaktivzeit ist noch nicht abgelaufen (bei jedem Weckereignis wird die Mindestaktivzeit neu gestartet)";
CM_ SG_ 2600468494 NM_BCM1_NM_State "1 = Zustand Repeat Message (<-- Bus-Sleep Mode)
2 = Zustand Repeat Message (<-- Prepare Bus-Sleep Mode)
4 = Zustand Normal Operation (<-- Repeat Message)
8 = Zustand Normal Operation (<-- Ready Sleep)";
CM_ SG_ 2600468494 NM_BCM1_SNI "Source Node-Identifier (SNI) identifiziert den Sender der NM-Botschaft (Knotenadresse) eindeutig im Fahrzeug";
CM_ SG_ 2600468494 NM_BCM1_UDS_CC "Funktionseinschränkung aufgrund aktivem UDS-Communication Control; siehe VW80124";

CM_ SG_ 2600468496 NM_Gateway_CAB "CAB = Clusteraktivbits";
CM_ SG_ 2600468496 NM_Gateway_Car_Wakeup "Car Wakeup (Subbusmaster wertet aus)
MQB: Diagnose- oder Komponentenschutzmaster-Funktion weckt den schlafenden Subbus (z.B. MOST)";
CM_ SG_ 2600468496 NM_Gateway_CBV_AWB "Das Signal ist zu setzen, wenn das SG aktiv den Bus geweckt hat";
CM_ SG_ 2600468496 NM_Gateway_CBV_CRI "Das Signal ist dauerhaft gesetzt, wenn das NM-Layout dem neuen NM-Layout für Teilnetzbetrieb entspricht";
CM_ SG_ 2600468496 NM_Gateway_NM_aktiv_Buskopplung "Nachlauf aufgrund Kopplung zweier Busse. z.B. K-CAN und K2-CAN";
CM_ SG_ 2600468496 NM_Gateway_NM_aktiv_Connect "Nachlauf aufgrund Connect";
CM_ SG_ 2600468496 NM_Gateway_NM_aktiv_CWU "Nachlauf aufgrund CWU Anforderung";
CM_ SG_ 2600468496 NM_Gateway_NM_aktiv_Diagnose "Diagnose befindet sich nach VW80124 in einer NonDefaultDiagnostic-Session, z.B. ExtendedDiagnostic-Session";
CM_ SG_ 2600468496 NM_Gateway_NM_aktiv_EM "Nachlauf aufgrund Energiemanagement";
CM_ SG_ 2600468496 NM_Gateway_NM_aktiv_FC "Nachlauf aufgrund Funktionscluster Anforderung";
CM_ SG_ 2600468496 NM_Gateway_NM_aktiv_KL15 "Steuergerät hat KL15-EIN erkannt";
CM_ SG_ 2600468496 NM_Gateway_NM_aktiv_OBDC "Nachlauf aufgrund OBDC";
CM_ SG_ 2600468496 NM_Gateway_NM_aktiv_Tmin "Mindestaktivzeit ist noch nicht abgelaufen (bei jedem Weckereignis wird die Mindestaktivzeit neu gestartet)";
CM_ SG_ 2600468496 NM_Gateway_NM_State "1 = Zustand Repeat Message (<-- Bus-Sleep Mode)
2 = Zustand Repeat Message (<-- Prepare Bus-Sleep Mode)
4 = Zustand Normal Operation (<-- Repeat Message)
8 = Zustand Normal Operation (<-- Ready Sleep)
16 = Zustand Repeat Message (<-- Ready Sleep)
32 ";
CM_ SG_ 2600468496 NM_Gateway_SNI "Source Node-Identifier (SNI) identifiziert den Sender der NM-Botschaft (Knotenadresse) eindeutig im Fahrzeug";
CM_ SG_ 2600468496 NM_Gateway_UDS_CC "Funktionseinschränkung aufgrund aktivem UDS-Communication Control; siehe VW80124";

CM_ SG_ 2600468550 NM_Klima_CAB "CAB = Clusteraktivbits";
CM_ SG_ 2600468550 NM_Klima_Car_Wakeup "Car Wakeup (Gateway wertet aus)
MQB: STH einschalten (Zielzeitlogik), Standheizbetrieb angefordert (Sofortheiztaste gedrückt, Ein- und Ausschalten), Restwärmefunktion angefordert, Umentscheidung STL nach STH, Ablauf max Betriebsdauer

MLBevo: STH einsc";
CM_ SG_ 2600468550 NM_Klima_CBV_AWB "Das Signal ist zu setzen, wenn das SG aktiv den Bus geweckt hat";
CM_ SG_ 2600468550 NM_Klima_CBV_CRI "Das Signal ist dauerhaft gesetzt, wenn das NM-Layout dem neuen NM-Layout für Teilnetzbetrieb entspricht";
CM_ SG_ 2600468550 NM_Klima_NM_aktiv_Abstellzstd "Abstellzustand für Klima herstellen. Definierte Beendigung der Funktionen nach KL15 AUS";
CM_ SG_ 2600468550 NM_Klima_NM_aktiv_Diagnose "Diagnose befindet sich nach VW80124 in einer NonDefaultDiagnostic-Session, z.B. ExtendedDiagnostic-Session";
CM_ SG_ 2600468550 NM_Klima_NM_aktiv_KL15 "Steuergerät hat KL15-EIN erkannt";
CM_ SG_ 2600468550 NM_Klima_NM_aktiv_Tmin "Mindestaktivzeit ist noch nicht abgelaufen (bei jedem Weckereignis wird die Mindestaktivzeit neu gestartet)";
CM_ SG_ 2600468550 NM_Klima_NM_State "1 = Zustand Repeat Message (<-- Bus-Sleep Mode)
2 = Zustand Repeat Message (<-- Prepare Bus-Sleep Mode)
4 = Zustand Normal Operation (<-- Repeat Message)
8 = Zustand Normal Operation (<-- Ready Sleep)";
CM_ SG_ 2600468550 NM_Klima_SNI "Source Node-Identifier (SNI) identifiziert den Sender der NM-Botschaft (Knotenadresse) eindeutig im Fahrzeug";
CM_ SG_ 2600468550 NM_Klima_UDS_CC "Funktionseinschränkung aufgrund aktivem UDS-Communication Control; siehe VW80124";

CM_ SG_ 2600468569 NM_Lift_VA_CAB "CAB = Clusteraktivbits";
CM_ SG_ 2600468569 NM_Lift_VA_Car_Wakeup "Car Wakeup (Gateway wertet aus)
MQB: Kl.58xd, Kl.58xs, Kl.58xt eingeschaltet oder ausgeschaltet oder Dimmungssignal wurde vom Kunden geändert (nicht vom Fototransistor); S-Kontakt wurde ein- oder ausgeschaltet; Remotestartbetrieb; Tankklappe wurde geschl";
CM_ SG_ 2600468569 NM_Lift_VA_CBV_AWB "Das Signal ist zu setzen, wenn das SG aktiv den Bus geweckt hat";
CM_ SG_ 2600468569 NM_Lift_VA_CBV_CRI "Das Signal ist dauerhaft gesetzt, wenn das NM-Layout dem neuen NM-Layout für Teilnetzbetrieb entspricht";
CM_ SG_ 2600468569 NM_Lift_VA_NM_aktiv_Diag "Diagnose befindet sich nach VW80124 in einer NonDefaultDiagnostic-Session, z.B. ExtendedDiagnostic-Session";
CM_ SG_ 2600468569 NM_Lift_VA_NM_aktiv_KL15 "Steuergerät hat KL15-EIN erkannt";
CM_ SG_ 2600468569 NM_Lift_VA_NM_aktiv_Tmin "Mindestaktivzeit ist noch nicht abgelaufen (bei jedem Weckereignis wird die Mindestaktivzeit neu gestartet)";
CM_ SG_ 2600468569 NM_Lift_VA_NM_State "1 = Zustand Repeat Message (<-- Bus-Sleep Mode)
2 = Zustand Repeat Message (<-- Prepare Bus-Sleep Mode)
4 = Zustand Normal Operation (<-- Repeat Message)
8 = Zustand Normal Operation (<-- Ready Sleep)";
CM_ SG_ 2600468569 NM_Lift_VA_SNI "Source Node-Identifier (SNI) identifiziert den Sender der NM-Botschaft (Knotenadresse) eindeutig im Fahrzeug";
CM_ SG_ 2600468569 NM_Lift_VA_UDS_CC "Funktionseinschränkung aufgrund aktivem UDS-Communication Control; siehe VW80124";

CM_ SG_ 2600468676 NM_VAS_L_CAB "CAB = Clusteraktivbits";
CM_ SG_ 2600468676 NM_VAS_L_Car_Wakeup "Car Wakeup (Gateway wertet aus)";
CM_ SG_ 2600468676 NM_VAS_L_CBV_AWB "Das Signal ist zu setzen, wenn das SG aktiv den Bus geweckt hat";
CM_ SG_ 2600468676 NM_VAS_L_CBV_CRI "Das Signal ist dauerhaft gesetzt, wenn das NM-Layout dem neuen NM-Layout für Teilnetzbetrieb entspricht";
CM_ SG_ 2600468676 NM_VAS_L_NM_aktiv_Diagnose "Diagnose befindet sich nach VW80124 in einer NonDefaultDiagnostic-Session, z.B. ExtendedDiagnostic-Session";
CM_ SG_ 2600468676 NM_VAS_L_NM_aktiv_KL15 "Steuergerät hat KL15-EIN erkannt";
CM_ SG_ 2600468676 NM_VAS_L_NM_aktiv_Tmin "Mindestaktivzeit ist noch nicht abgelaufen (bei jedem Weckereignis wird die Mindestaktivzeit neu gestartet)";
CM_ SG_ 2600468676 NM_VAS_L_NM_aktiv_Verstellung "Verstellung im Display des VAS";
CM_ SG_ 2600468676 NM_VAS_L_NM_State "1 = Zustand Repeat Message (<-- Bus-Sleep Mode)
2 = Zustand Repeat Message (<-- Prepare Bus-Sleep Mode)
4 = Zustand Normal Operation (<-- Repeat Message)
8 = Zustand Normal Operation (<-- Ready Sleep)
16 = Zustand Repeat Message (<-- Ready Sleep)
32 ";
CM_ SG_ 2600468676 NM_VAS_L_SNI "Source Node-Identifier (SNI) identifiziert den Sender der NM-Botschaft (Knotenadresse) eindeutig im Fahrzeug";
CM_ SG_ 2600468676 NM_VAS_L_UDS_CC "Funktionseinschränkung aufgrund aktivem UDS-Communication Control; siehe VW80124";

CM_ SG_ 2600468677 NM_VAS_R_CAB "CAB = Clusteraktivbits";
CM_ SG_ 2600468677 NM_VAS_R_Car_Wakeup "Car Wakeup (Gateway wertet aus)";
CM_ SG_ 2600468677 NM_VAS_R_CBV_AWB "Das Signal ist zu setzen, wenn das SG aktiv den Bus geweckt hat";
CM_ SG_ 2600468677 NM_VAS_R_CBV_CRI "Das Signal ist dauerhaft gesetzt, wenn das NM-Layout dem neuen NM-Layout für Teilnetzbetrieb entspricht";
CM_ SG_ 2600468677 NM_VAS_R_NM_aktiv_Diagnose "Diagnose befindet sich nach VW80124 in einer NonDefaultDiagnostic-Session, z.B. ExtendedDiagnostic-Session";
CM_ SG_ 2600468677 NM_VAS_R_NM_aktiv_KL15 "Steuergerät hat KL15-EIN erkannt";
CM_ SG_ 2600468677 NM_VAS_R_NM_aktiv_Tmin "Mindestaktivzeit ist noch nicht abgelaufen (bei jedem Weckereignis wird die Mindestaktivzeit neu gestartet)";
CM_ SG_ 2600468677 NM_VAS_R_NM_aktiv_Verstellung "Verstellung im Display des VAS (nur Rechtslenker)";
CM_ SG_ 2600468677 NM_VAS_R_NM_State "1 = Zustand Repeat Message (<-- Bus-Sleep Mode)
2 = Zustand Repeat Message (<-- Prepare Bus-Sleep Mode)
4 = Zustand Normal Operation (<-- Repeat Message)
8 = Zustand Normal Operation (<-- Ready Sleep)
16 = Zustand Repeat Message (<-- Ready Sleep)
32 ";
CM_ SG_ 2600468677 NM_VAS_R_SNI "Source Node-Identifier (SNI) identifiziert den Sender der NM-Botschaft (Knotenadresse) eindeutig im Fahrzeug";
CM_ SG_ 2600468677 NM_VAS_R_UDS_CC "Funktionseinschränkung aufgrund aktivem UDS-Communication Control; siehe VW80124";
BA_DEF_REL_ BU_SG_REL_  "GenSigTimeoutTime" INT 0 65535;
BA_DEF_ BO_  "DiagRequest" ENUM "No", "Yes";
BA_DEF_ BO_  "DiagResponse" ENUM "No", "Yes";
BA_DEF_ BO_  "DiagState" ENUM "No", "Yes";
BA_DEF_ BO_  "GenMsgChkConstant" HEX 0 4095;
BA_DEF_ BO_  "GenMsgCycleTime" INT 0 65535;
BA_DEF_ BO_  "GenMsgCycleTimeFast" INT 0 65535;
BA_DEF_ BO_  "GenMsgDelayTime" INT 0 100000;
BA_DEF_ BO_  "GenMsgILSupport" ENUM "No", "Yes";
BA_DEF_ BO_  "GenMsgNrOfRepetition" INT 0 100;
BA_DEF_ BO_  "GenMsgPDUConstants" STRING;
BA_DEF_ BO_  "GenMsgSendType" ENUM "Cyclic", "not_used", "not_used", "not_used", "not_used", "not_used", "not_used", "IfActive", "NoMsgSendType";
BA_DEF_ BO_  "GenMsgStartDelayTime" INT 0 100000;
BA_DEF_ BO_  "NmMessage" ENUM "No", "Yes";
BA_DEF_ BO_  "NmhMessage" ENUM "No", "Yes";
BA_DEF_ BO_  "MsgType" ENUM "Application", "NM ", "NMH", "TP2.0", "ISO-TP ", "BAP", "EID", "KS";
BA_DEF_ BO_  "VAGTP20_API" HEX 0 255;
BA_DEF_ BO_  "VAGTP20_DynConnection" ENUM "No", "Yes";
BA_DEF_ BO_  "VAGTP20_DynSetup" ENUM "No", "Yes";
BA_DEF_ BO_  "VAGTP20_StatConnection" ENUM "No", "Yes";
BA_DEF_ SG_  "GenSigActiveRepetitions" INT -2147483648 2147483647;
BA_DEF_ SG_  "GenSigInactiveValue" INT -2147483648 2147483647;
BA_DEF_ SG_  "GenSigSendType" ENUM "Cyclic", "OnWrite", "OnWriteWithRepetition", "OnChange", "OnChangeWithRepetition", "IfActive", "IfActiveWithRepetition", "NoSigSendType", "OnChangeAndIfActive", "OnChangeAndIfActiveWithRepetition";
BA_DEF_ SG_  "GenSigStartValue" INT -2147483648 2147483647;
BA_DEF_ SG_  "NWM-WakeupAllowed" ENUM "No", "Yes";
BA_DEF_ SG_  "GenSigFuncType" ENUM "NoFunction", "MsgCounter", "CRC-8", "XOR", "XOR-2", "DatedBit", "SW-Kl15", "CHK", "Constant", "Protocol", "CRC-8-SAE_J1850";
BA_DEF_ SG_  "GenSigSwitchedByIgnition" ENUM "No", "Yes";
BA_DEF_ SG_  "Fehlerwert" HEX 0 2147483647;
BA_DEF_ SG_  "GenSigMissingSourceValue" HEX 0 2147483647;
BA_DEF_DEF_REL_  "GenSigTimeoutTime" 0;
BA_DEF_DEF_  "DiagRequest" "No";
BA_DEF_DEF_  "DiagResponse" "No";
BA_DEF_DEF_  "DiagState" "No";
BA_DEF_DEF_  "GenMsgChkConstant" 0;
BA_DEF_DEF_  "GenMsgCycleTime" 0;
BA_DEF_DEF_  "GenMsgCycleTimeFast" 0;
BA_DEF_DEF_  "GenMsgDelayTime" 0;
BA_DEF_DEF_  "GenMsgILSupport" "No";
BA_DEF_DEF_  "GenMsgNrOfRepetition" 0;
BA_DEF_DEF_  "GenMsgPDUConstants" "";
BA_DEF_DEF_  "GenMsgSendType" "NoMsgSendType";
BA_DEF_DEF_  "GenMsgStartDelayTime" 0;
BA_DEF_DEF_  "NmMessage" "No";
BA_DEF_DEF_  "NmhMessage" "No";
BA_DEF_DEF_  "MsgType" "Application";
BA_DEF_DEF_  "VAGTP20_API" 0;
BA_DEF_DEF_  "VAGTP20_DynConnection" "No";
BA_DEF_DEF_  "VAGTP20_DynSetup" "No";
BA_DEF_DEF_  "VAGTP20_StatConnection" "No";
BA_DEF_DEF_  "GenSigActiveRepetitions" 0;
BA_DEF_DEF_  "GenSigInactiveValue" 0;
BA_DEF_DEF_  "GenSigSendType" "NoSigSendType";
BA_DEF_DEF_  "GenSigStartValue" 0;
BA_DEF_DEF_  "NWM-WakeupAllowed" "No";
BA_DEF_DEF_  "GenSigFuncType" "NoFunction";
BA_DEF_DEF_  "GenSigSwitchedByIgnition" "Yes";
BA_DEF_DEF_  "Fehlerwert" 0;
BA_DEF_DEF_  "GenSigMissingSourceValue" 0;
BA_ "GenMsgCycleTime" BO_ 958 100;
BA_ "GenMsgDelayTime" BO_ 958 10;
BA_ "GenMsgILSupport" BO_ 958 1;
BA_ "GenMsgPDUConstants" BO_ 958 "0x1f,0x28,0xc6,0x85,0xe6,0xf8,0xb0,0x19,0x5b,0x64,0x35,0x21,0xe4,0xf7,0x9c,0x24";
BA_ "GenMsgSendType" BO_ 958 0;
BA_ "GenMsgCycleTime" BO_ 1631 320;
BA_ "GenMsgILSupport" BO_ 1631 1;
BA_ "GenMsgSendType" BO_ 1631 0;
BA_ "GenMsgCycleTime" BO_ 812 200;
BA_ "GenMsgDelayTime" BO_ 812 40;
BA_ "GenMsgILSupport" BO_ 812 1;
BA_ "GenMsgSendType" BO_ 812 0;
BA_ "GenMsgCycleTime" BO_ 1648 500;
BA_ "GenMsgDelayTime" BO_ 1648 20;
BA_ "GenMsgILSupport" BO_ 1648 1;
BA_ "GenMsgSendType" BO_ 1648 0;
BA_ "GenMsgCycleTime" BO_ 289 40;
BA_ "GenMsgILSupport" BO_ 289 1;
BA_ "GenMsgPDUConstants" BO_ 289 "0xe9,0x65,0xae,0x6b,0x7b,0x35,0xe5,0x5f,0x4e,0xc7,0x86,0xa2,0xbb,0xdd,0xeb,0xb4";
BA_ "GenMsgSendType" BO_ 289 0;
BA_ "GenMsgCycleTime" BO_ 1423 320;
BA_ "GenMsgILSupport" BO_ 1423 1;
BA_ "GenMsgSendType" BO_ 1423 0;
BA_ "GenMsgCycleTime" BO_ 967 80;
BA_ "GenMsgILSupport" BO_ 967 1;
BA_ "GenMsgSendType" BO_ 967 0;
BA_ "GenMsgCycleTime" BO_ 340 200;
BA_ "GenMsgILSupport" BO_ 340 1;
BA_ "GenMsgPDUConstants" BO_ 340 "0x21,0x93,0x4a,0x04,0x5c,0x18,0xe0,0x69,0x14,0xce,0x26,0x8f,0x5e,0xb1,0xdf,0x53";
BA_ "GenMsgSendType" BO_ 340 0;
BA_ "GenMsgCycleTime" BO_ 283 500;
BA_ "GenMsgDelayTime" BO_ 283 10;
BA_ "GenMsgILSupport" BO_ 283 1;
BA_ "GenMsgSendType" BO_ 283 0;
BA_ "GenMsgChkConstant" BO_ 1601 71;
BA_ "GenMsgCycleTime" BO_ 1601 960;
BA_ "GenMsgILSupport" BO_ 1601 1;
BA_ "GenMsgPDUConstants" BO_ 1601 "0x47,0x47,0x47,0x47,0x47,0x47,0x47,0x47,0x47,0x47,0x47,0x47,0x47,0x47,0x47,0x47";
BA_ "GenMsgSendType" BO_ 1601 0;
BA_ "GenMsgCycleTime" BO_ 394 200;
BA_ "GenMsgDelayTime" BO_ 394 10;
BA_ "GenMsgILSupport" BO_ 394 1;
BA_ "GenMsgSendType" BO_ 394 0;
BA_ "GenMsgCycleTime" BO_ 1156 1000;
BA_ "GenMsgILSupport" BO_ 1156 1;
BA_ "GenMsgSendType" BO_ 1156 0;
BA_ "GenMsgCycleTime" BO_ 1157 1000;
BA_ "GenMsgILSupport" BO_ 1157 1;
BA_ "GenMsgSendType" BO_ 1157 0;
BA_ "GenMsgCycleTime" BO_ 2527679512 1000;
BA_ "GenMsgILSupport" BO_ 2527679512 1;
BA_ "GenMsgSendType" BO_ 2527679512 0;
BA_ "GenMsgCycleTime" BO_ 1158 1000;
BA_ "GenMsgILSupport" BO_ 1158 1;
BA_ "GenMsgSendType" BO_ 1158 0;
BA_ "GenMsgCycleTime" BO_ 2589283496 500;
BA_ "GenMsgILSupport" BO_ 2589283496 1;
BA_ "GenMsgSendType" BO_ 2589283496 0;
BA_ "GenMsgCycleTime" BO_ 2527679647 200;
BA_ "GenMsgILSupport" BO_ 2527679647 1;
BA_ "GenMsgSendType" BO_ 2527679647 0;
BA_ "GenMsgCycleTime" BO_ 1696 200;
BA_ "GenMsgDelayTime" BO_ 1696 20;
BA_ "GenMsgILSupport" BO_ 1696 1;
BA_ "GenMsgSendType" BO_ 1696 0;
BA_ "GenMsgCycleTime" BO_ 2600468494 200;
BA_ "GenMsgCycleTimeFast" BO_ 2600468494 10;
BA_ "GenMsgNrOfRepetition" BO_ 2600468494 3;
BA_ "GenMsgSendType" BO_ 2600468494 7;
BA_ "NmhMessage" BO_ 2600468494 1;
BA_ "MsgType" BO_ 2600468494 2;
BA_ "GenMsgCycleTime" BO_ 2600468496 200;
BA_ "GenMsgCycleTimeFast" BO_ 2600468496 10;
BA_ "GenMsgNrOfRepetition" BO_ 2600468496 3;
BA_ "GenMsgSendType" BO_ 2600468496 7;
BA_ "NmhMessage" BO_ 2600468496 1;
BA_ "MsgType" BO_ 2600468496 2;
BA_ "GenMsgCycleTime" BO_ 2600468550 200;
BA_ "GenMsgCycleTimeFast" BO_ 2600468550 10;
BA_ "GenMsgNrOfRepetition" BO_ 2600468550 3;
BA_ "GenMsgSendType" BO_ 2600468550 7;
BA_ "NmhMessage" BO_ 2600468550 1;
BA_ "MsgType" BO_ 2600468550 2;
BA_ "GenMsgCycleTime" BO_ 2600468569 200;
BA_ "GenMsgCycleTimeFast" BO_ 2600468569 10;
BA_ "GenMsgNrOfRepetition" BO_ 2600468569 3;
BA_ "GenMsgSendType" BO_ 2600468569 7;
BA_ "NmhMessage" BO_ 2600468569 1;
BA_ "MsgType" BO_ 2600468569 2;
BA_ "GenMsgCycleTime" BO_ 2600468676 200;
BA_ "GenMsgCycleTimeFast" BO_ 2600468676 10;
BA_ "GenMsgNrOfRepetition" BO_ 2600468676 3;
BA_ "GenMsgSendType" BO_ 2600468676 7;
BA_ "NmhMessage" BO_ 2600468676 1;
BA_ "MsgType" BO_ 2600468676 2;
BA_ "GenMsgCycleTime" BO_ 2600468677 200;
BA_ "GenMsgCycleTimeFast" BO_ 2600468677 10;
BA_ "GenMsgNrOfRepetition" BO_ 2600468677 3;
BA_ "GenMsgSendType" BO_ 2600468677 7;
BA_ "NmhMessage" BO_ 2600468677 1;
BA_ "MsgType" BO_ 2600468677 2;
BA_ "GenSigSendType" SG_ 958 MO_Aussp_Anlass 3;
BA_ "GenSigSwitchedByIgnition" SG_ 958 MO_Aussp_Anlass 0;
BA_ "GenSigSendType" SG_ 958 MO_BKV_Unterdruckwarnung 0;
BA_ "GenSigSwitchedByIgnition" SG_ 958 MO_BKV_Unterdruckwarnung 0;
BA_ "GenSigSendType" SG_ 958 MO_BLS 3;
BA_ "GenSigSwitchedByIgnition" SG_ 958 MO_BLS 0;
BA_ "GenSigSendType" SG_ 958 MO_BMS_NV_Anf_stuetzen 3;
BA_ "GenSigSwitchedByIgnition" SG_ 958 MO_BMS_NV_Anf_stuetzen 0;
BA_ "GenSigSendType" SG_ 958 MO_EKlKomLeiRed 0;
BA_ "GenSigSwitchedByIgnition" SG_ 958 MO_EKlKomLeiRed 0;
BA_ "GenSigSendType" SG_ 958 MO_Ext_E_Fahrt_aktiv 3;
BA_ "NWM-WakeupAllowed" SG_ 958 MO_Ext_E_Fahrt_aktiv 1;
BA_ "GenSigSwitchedByIgnition" SG_ 958 MO_Ext_E_Fahrt_aktiv 0;
BA_ "GenSigSendType" SG_ 958 MO_Fahrer_bremst 3;
BA_ "GenSigSwitchedByIgnition" SG_ 958 MO_Fahrer_bremst 0;
BA_ "GenSigSendType" SG_ 958 MO_FMAus_aktiv 3;
BA_ "GenSigSwitchedByIgnition" SG_ 958 MO_FMAus_aktiv 0;
BA_ "GenSigSendType" SG_ 958 MO_FMAus_Startvariante 3;
BA_ "GenSigSwitchedByIgnition" SG_ 958 MO_FMAus_Startvariante 0;
BA_ "GenSigSendType" SG_ 958 MO_Freig_Anlass 3;
BA_ "GenSigSwitchedByIgnition" SG_ 958 MO_Freig_Anlass 0;
BA_ "GenSigSendType" SG_ 958 MO_Freig_Reku 0;
BA_ "GenSigSwitchedByIgnition" SG_ 958 MO_Freig_Reku 0;
BA_ "GenSigSendType" SG_ 958 MO_Freigabe_Segeln 0;
BA_ "GenSigSwitchedByIgnition" SG_ 958 MO_Freigabe_Segeln 0;
BA_ "GenSigSendType" SG_ 958 MO_Gangposition 3;
BA_ "GenSigStartValue" SG_ 958 MO_Gangposition 14;
BA_ "GenSigSwitchedByIgnition" SG_ 958 MO_Gangposition 0;
BA_ "Fehlerwert" SG_ 958 MO_Gangposition 15;
BA_ "GenSigSendType" SG_ 958 MO_Handshake_STH 0;
BA_ "GenSigSwitchedByIgnition" SG_ 958 MO_Handshake_STH 0;
BA_ "GenSigSendType" SG_ 958 MO_HYB_Fahrbereitschaft 0;
BA_ "GenSigSwitchedByIgnition" SG_ 958 MO_HYB_Fahrbereitschaft 0;
BA_ "GenSigSendType" SG_ 958 MO_HYB_VM_aktiv 3;
BA_ "GenSigSwitchedByIgnition" SG_ 958 MO_HYB_VM_aktiv 0;
BA_ "GenSigSendType" SG_ 958 MO_Interlock 3;
BA_ "GenSigSwitchedByIgnition" SG_ 958 MO_Interlock 0;
BA_ "GenSigSendType" SG_ 958 MO_Kickdown 3;
BA_ "GenSigSwitchedByIgnition" SG_ 958 MO_Kickdown 0;
BA_ "GenSigSendType" SG_ 958 MO_Kl_50 3;
BA_ "GenSigSwitchedByIgnition" SG_ 958 MO_Kl_50 0;
BA_ "GenSigSendType" SG_ 958 MO_Kl_75 3;
BA_ "GenSigSwitchedByIgnition" SG_ 958 MO_Kl_75 0;
BA_ "GenSigSendType" SG_ 958 MO_Klima_Eingr 0;
BA_ "GenSigSwitchedByIgnition" SG_ 958 MO_Klima_Eingr 0;
BA_ "GenSigSendType" SG_ 958 MO_KomFehler_ESP 3;
BA_ "GenSigSwitchedByIgnition" SG_ 958 MO_KomFehler_ESP 0;
BA_ "Fehlerwert" SG_ 958 MO_KomFehler_ESP 1;
BA_ "GenSigSendType" SG_ 958 MO_Konsistenz_Bremsped 3;
BA_ "GenSigSwitchedByIgnition" SG_ 958 MO_Konsistenz_Bremsped 0;
BA_ "GenSigSendType" SG_ 958 MO_Kuppl_schalter 3;
BA_ "GenSigSwitchedByIgnition" SG_ 958 MO_Kuppl_schalter 0;
BA_ "GenSigSendType" SG_ 958 MO_Motor_laeuft 3;
BA_ "GenSigSwitchedByIgnition" SG_ 958 MO_Motor_laeuft 0;
BA_ "GenSigSendType" SG_ 958 MO_PTC_Status 0;
BA_ "GenSigSwitchedByIgnition" SG_ 958 MO_PTC_Status 0;
BA_ "GenSigSendType" SG_ 958 MO_QBit_Fahrer_bremst 3;
BA_ "GenSigStartValue" SG_ 958 MO_QBit_Fahrer_bremst 1;
BA_ "GenSigSwitchedByIgnition" SG_ 958 MO_QBit_Fahrer_bremst 0;
BA_ "GenSigSendType" SG_ 958 MO_QBit_Gangposition 3;
BA_ "GenSigStartValue" SG_ 958 MO_QBit_Gangposition 1;
BA_ "GenSigSwitchedByIgnition" SG_ 958 MO_QBit_Gangposition 0;
BA_ "GenSigSendType" SG_ 958 MO_QBit_KL_75 3;
BA_ "GenSigStartValue" SG_ 958 MO_QBit_KL_75 1;
BA_ "GenSigSwitchedByIgnition" SG_ 958 MO_QBit_KL_75 0;
BA_ "GenSigSendType" SG_ 958 MO_Remotestart_Betrieb 3;
BA_ "GenSigSwitchedByIgnition" SG_ 958 MO_Remotestart_Betrieb 0;
BA_ "GenSigSendType" SG_ 958 MO_Remotestart_moeglich 0;
BA_ "GenSigSwitchedByIgnition" SG_ 958 MO_Remotestart_moeglich 0;
BA_ "GenSigSendType" SG_ 958 MO_Signalquelle_Gangposition 0;
BA_ "GenSigSwitchedByIgnition" SG_ 958 MO_Signalquelle_Gangposition 0;
BA_ "GenSigSendType" SG_ 958 MO_StartStopp_Fahrerwunsch 0;
BA_ "GenSigSwitchedByIgnition" SG_ 958 MO_StartStopp_Fahrerwunsch 0;
BA_ "GenSigSendType" SG_ 958 MO_StartStopp_Motorstopp 3;
BA_ "GenSigSwitchedByIgnition" SG_ 958 MO_StartStopp_Motorstopp 0;
BA_ "GenSigSendType" SG_ 958 MO_StartStopp_Status 3;
BA_ "GenSigSwitchedByIgnition" SG_ 958 MO_StartStopp_Status 0;
BA_ "GenSigSendType" SG_ 958 MO_StartStopp_Wiederstart 3;
BA_ "GenSigSwitchedByIgnition" SG_ 958 MO_StartStopp_Wiederstart 0;
BA_ "GenSigSendType" SG_ 958 MO_StartVorauss_erfuellt 3;
BA_ "GenSigStartValue" SG_ 958 MO_StartVorauss_erfuellt 1;
BA_ "GenSigSwitchedByIgnition" SG_ 958 MO_StartVorauss_erfuellt 0;
BA_ "GenSigSendType" SG_ 958 MO_Zylinderabschaltung 3;
BA_ "GenSigSwitchedByIgnition" SG_ 958 MO_Zylinderabschaltung 0;
BA_ "GenSigSendType" SG_ 958 Motor_14_BZ 0;
BA_ "GenSigFuncType" SG_ 958 Motor_14_BZ 1;
BA_ "GenSigSwitchedByIgnition" SG_ 958 Motor_14_BZ 0;
BA_ "GenSigSendType" SG_ 958 Motor_14_CRC 0;
BA_ "GenSigFuncType" SG_ 958 Motor_14_CRC 2;
BA_ "GenSigSwitchedByIgnition" SG_ 958 Motor_14_CRC 0;
BA_ "GenSigSendType" SG_ 1631 MO_DPF_reg 0;
BA_ "GenSigSwitchedByIgnition" SG_ 1631 MO_DPF_reg 0;
BA_ "GenSigSendType" SG_ 1631 MO_Energieinhalt_BMS 0;
BA_ "GenSigStartValue" SG_ 1631 MO_Energieinhalt_BMS 4094;
BA_ "GenSigSwitchedByIgnition" SG_ 1631 MO_Energieinhalt_BMS 0;
BA_ "Fehlerwert" SG_ 1631 MO_Energieinhalt_BMS 4095;
BA_ "GenSigSendType" SG_ 1631 MO_Heizstrom_EKAT 0;
BA_ "GenSigSwitchedByIgnition" SG_ 1631 MO_Heizstrom_EKAT 0;
BA_ "Fehlerwert" SG_ 1631 MO_Heizstrom_EKAT 127;
BA_ "GenSigSendType" SG_ 1631 MO_Heizstrom_SCR 0;
BA_ "GenSigSwitchedByIgnition" SG_ 1631 MO_Heizstrom_SCR 0;
BA_ "Fehlerwert" SG_ 1631 MO_Heizstrom_SCR 63;
BA_ "GenSigSendType" SG_ 1631 MO_P_Generator_ungefiltert_Anf 0;
BA_ "GenSigSwitchedByIgnition" SG_ 1631 MO_P_Generator_ungefiltert_Anf 0;
BA_ "GenSigSendType" SG_ 1631 MO_SpannungsAnf_02 0;
BA_ "GenSigSwitchedByIgnition" SG_ 1631 MO_SpannungsAnf_02 0;
BA_ "GenSigSendType" SG_ 1631 TSK_Fahrzeugmasse_02 0;
BA_ "GenSigSwitchedByIgnition" SG_ 1631 TSK_Fahrzeugmasse_02 0;
BA_ "Fehlerwert" SG_ 1631 TSK_Fahrzeugmasse_02 255;
BA_ "GenSigSendType" SG_ 1631 TSK_Getriebeinfo 0;
BA_ "GenSigSwitchedByIgnition" SG_ 1631 TSK_Getriebeinfo 0;
BA_ "GenSigSendType" SG_ 1631 TSK_Grundmasse 0;
BA_ "GenSigSwitchedByIgnition" SG_ 1631 TSK_Grundmasse 0;
BA_ "GenSigSendType" SG_ 1631 TSK_QBit_Fahrzeugmasse 0;
BA_ "GenSigStartValue" SG_ 1631 TSK_QBit_Fahrzeugmasse 1;
BA_ "GenSigSwitchedByIgnition" SG_ 1631 TSK_QBit_Fahrzeugmasse 0;
BA_ "GenSigSendType" SG_ 1631 TSK_QBit_Steigung 0;
BA_ "GenSigStartValue" SG_ 1631 TSK_QBit_Steigung 1;
BA_ "GenSigSwitchedByIgnition" SG_ 1631 TSK_QBit_Steigung 0;
BA_ "GenSigSendType" SG_ 1631 TSK_Steigung_02 0;
BA_ "GenSigSwitchedByIgnition" SG_ 1631 TSK_Steigung_02 0;
BA_ "Fehlerwert" SG_ 1631 TSK_Steigung_02 255;
BA_ "GenSigSendType" SG_ 812 MO_BZS_Charisma_FahrPr 3;
BA_ "GenSigSwitchedByIgnition" SG_ 812 MO_BZS_Charisma_FahrPr 0;
BA_ "GenSigSendType" SG_ 812 MO_BZS_Charisma_Status 0;
BA_ "GenSigSwitchedByIgnition" SG_ 812 MO_BZS_Charisma_Status 0;
BA_ "GenSigSendType" SG_ 812 MO_Charisma_FahrPr 0;
BA_ "GenSigSwitchedByIgnition" SG_ 812 MO_Charisma_FahrPr 0;
BA_ "GenSigSendType" SG_ 812 MO_Charisma_Status 0;
BA_ "GenSigSwitchedByIgnition" SG_ 812 MO_Charisma_Status 0;
BA_ "GenSigSendType" SG_ 812 MO_Drehzahlbeeinflussung 0;
BA_ "GenSigSwitchedByIgnition" SG_ 812 MO_Drehzahlbeeinflussung 0;
BA_ "GenSigSendType" SG_ 812 MO_Luftpfad_aktiv 0;
BA_ "GenSigSwitchedByIgnition" SG_ 812 MO_Luftpfad_aktiv 0;
BA_ "GenSigSendType" SG_ 812 MO_MAX_Wunschdrehzahl 3;
BA_ "GenSigSwitchedByIgnition" SG_ 812 MO_MAX_Wunschdrehzahl 0;
BA_ "GenSigSendType" SG_ 812 MO_MIN_Wunschdrehzahl 0;
BA_ "GenSigSwitchedByIgnition" SG_ 812 MO_MIN_Wunschdrehzahl 0;
BA_ "GenSigSendType" SG_ 812 MO_NGS_Position 0;
BA_ "GenSigSwitchedByIgnition" SG_ 812 MO_NGS_Position 0;
BA_ "GenSigSendType" SG_ 812 MO_NGS_Status 0;
BA_ "GenSigSwitchedByIgnition" SG_ 812 MO_NGS_Status 0;
BA_ "Fehlerwert" SG_ 812 MO_NGS_Status 3;
BA_ "GenSigSendType" SG_ 812 MO_Prio_MAX_Wunschdrehzahl 3;
BA_ "GenSigSwitchedByIgnition" SG_ 812 MO_Prio_MAX_Wunschdrehzahl 0;
BA_ "GenSigSendType" SG_ 812 MO_Prio_MIN_Wunschdrehzahl 0;
BA_ "GenSigSwitchedByIgnition" SG_ 812 MO_Prio_MIN_Wunschdrehzahl 0;
BA_ "GenSigSendType" SG_ 812 MO_Rampenzeit_Generator_Anf 0;
BA_ "GenSigStartValue" SG_ 812 MO_Rampenzeit_Generator_Anf 15;
BA_ "GenSigSwitchedByIgnition" SG_ 812 MO_Rampenzeit_Generator_Anf 0;
BA_ "GenSigSendType" SG_ 812 MO_Sperrung_FahrPr_BZS 0;
BA_ "GenSigSwitchedByIgnition" SG_ 812 MO_Sperrung_FahrPr_BZS 0;
BA_ "GenSigSendType" SG_ 812 MO_StSt_Charisma_FahrPr 0;
BA_ "GenSigSwitchedByIgnition" SG_ 812 MO_StSt_Charisma_FahrPr 0;
BA_ "GenSigSendType" SG_ 812 MO_StSt_Charisma_Status 0;
BA_ "GenSigSwitchedByIgnition" SG_ 812 MO_StSt_Charisma_Status 0;
BA_ "GenSigSendType" SG_ 812 MO_v_Begrenz_Aktivierbar 0;
BA_ "GenSigSwitchedByIgnition" SG_ 812 MO_v_Begrenz_Aktivierbar 0;
BA_ "GenSigSendType" SG_ 812 MO_v_Begrenzung_Niveau 0;
BA_ "GenSigSwitchedByIgnition" SG_ 812 MO_v_Begrenzung_Niveau 0;
BA_ "GenSigSendType" SG_ 1648 MO1_Freigabe_Info_WFS 3;
BA_ "GenSigSwitchedByIgnition" SG_ 1648 MO1_Freigabe_Info_WFS 0;
BA_ "GenSigSendType" SG_ 1648 MO1_Freigabe_Verfallsinfo_WFS 3;
BA_ "GenSigSwitchedByIgnition" SG_ 1648 MO1_Freigabe_Verfallsinfo_WFS 0;
BA_ "GenSigSendType" SG_ 1648 MO1_Sperr_Info_WFS 3;
BA_ "GenSigSwitchedByIgnition" SG_ 1648 MO1_Sperr_Info_WFS 0;
BA_ "GenSigSendType" SG_ 1648 MO_Abstellzeit 0;
BA_ "GenSigStartValue" SG_ 1648 MO_Abstellzeit 254;
BA_ "GenSigSwitchedByIgnition" SG_ 1648 MO_Abstellzeit 0;
BA_ "GenSigSendType" SG_ 1648 MO_Abstellzeit_Status 0;
BA_ "GenSigSwitchedByIgnition" SG_ 1648 MO_Abstellzeit_Status 0;
BA_ "GenSigSendType" SG_ 1648 MO_ANC_Kennfeld_Anf 3;
BA_ "GenSigSwitchedByIgnition" SG_ 1648 MO_ANC_Kennfeld_Anf 0;
BA_ "GenSigSendType" SG_ 1648 MO_Anzahl_Abgesch_Zyl 3;
BA_ "GenSigSwitchedByIgnition" SG_ 1648 MO_Anzahl_Abgesch_Zyl 0;
BA_ "GenSigSendType" SG_ 1648 MO_Bremslicht_Reku 3;
BA_ "GenSigSwitchedByIgnition" SG_ 1648 MO_Bremslicht_Reku 0;
BA_ "GenSigSendType" SG_ 1648 MO_Drehzahl_Warnung 0;
BA_ "GenSigSwitchedByIgnition" SG_ 1648 MO_Drehzahl_Warnung 0;
BA_ "GenSigSendType" SG_ 1648 MO_EPCL 0;
BA_ "GenSigSwitchedByIgnition" SG_ 1648 MO_EPCL 0;
BA_ "GenSigSendType" SG_ 1648 MO_Ethanol_BS_Texte 0;
BA_ "GenSigSwitchedByIgnition" SG_ 1648 MO_Ethanol_BS_Texte 0;
BA_ "GenSigSendType" SG_ 1648 MO_Fahrzeugtyp 0;
BA_ "GenSigFuncType" SG_ 1648 MO_Fahrzeugtyp 8;
BA_ "GenSigSwitchedByIgnition" SG_ 1648 MO_Fahrzeugtyp 0;
BA_ "GenSigSendType" SG_ 1648 MO_Fehler_Zylabsch 0;
BA_ "GenSigSwitchedByIgnition" SG_ 1648 MO_Fehler_Zylabsch 0;
BA_ "GenSigSendType" SG_ 1648 MO_Hybrid_StartStopp_LED 3;
BA_ "GenSigSwitchedByIgnition" SG_ 1648 MO_Hybrid_StartStopp_LED 0;
BA_ "GenSigSendType" SG_ 1648 MO_max_Ladedruck 0;
BA_ "GenSigFuncType" SG_ 1648 MO_max_Ladedruck 8;
BA_ "GenSigSwitchedByIgnition" SG_ 1648 MO_max_Ladedruck 0;
BA_ "GenSigSendType" SG_ 1648 MO_NMAX_Schaltanzeige 3;
BA_ "GenSigSwitchedByIgnition" SG_ 1648 MO_NMAX_Schaltanzeige 0;
BA_ "GenSigSendType" SG_ 1648 MO_obere_Drehzahlgrenze 0;
BA_ "GenSigSwitchedByIgnition" SG_ 1648 MO_obere_Drehzahlgrenze 0;
BA_ "GenSigSendType" SG_ 1648 MO_StartStopp_PopUp 3;
BA_ "GenSigSwitchedByIgnition" SG_ 1648 MO_StartStopp_PopUp 0;
BA_ "GenSigSendType" SG_ 1648 MO_Zylabsch_Texte 0;
BA_ "GenSigSwitchedByIgnition" SG_ 1648 MO_Zylabsch_Texte 0;
BA_ "GenSigSendType" SG_ 1648 MO_Zylabsch_Texte_02 3;
BA_ "GenSigSwitchedByIgnition" SG_ 1648 MO_Zylabsch_Texte_02 0;
BA_ "GenSigSendType" SG_ 289 MO_Entkopplung_Sollschlupf 0;
BA_ "GenSigStartValue" SG_ 289 MO_Entkopplung_Sollschlupf 126;
BA_ "GenSigSwitchedByIgnition" SG_ 289 MO_Entkopplung_Sollschlupf 0;
BA_ "GenSigSendType" SG_ 289 MO_Fahrpedalgradient 0;
BA_ "GenSigSwitchedByIgnition" SG_ 289 MO_Fahrpedalgradient 0;
BA_ "Fehlerwert" SG_ 289 MO_Fahrpedalgradient 255;
BA_ "GenSigSendType" SG_ 289 MO_Fahrpedalrohwert_01 0;
BA_ "GenSigSwitchedByIgnition" SG_ 289 MO_Fahrpedalrohwert_01 0;
BA_ "Fehlerwert" SG_ 289 MO_Fahrpedalrohwert_01 255;
BA_ "GenSigSendType" SG_ 289 MO_Moment_im_Leerlauf 0;
BA_ "GenSigSwitchedByIgnition" SG_ 289 MO_Moment_im_Leerlauf 0;
BA_ "GenSigSendType" SG_ 289 MO_QBit_Fahrpedalwerte_01 0;
BA_ "GenSigStartValue" SG_ 289 MO_QBit_Fahrpedalwerte_01 1;
BA_ "GenSigSwitchedByIgnition" SG_ 289 MO_QBit_Fahrpedalwerte_01 0;
BA_ "GenSigSendType" SG_ 289 MO_rel_Saugrohrdruck 0;
BA_ "GenSigSwitchedByIgnition" SG_ 289 MO_rel_Saugrohrdruck 0;
BA_ "Fehlerwert" SG_ 289 MO_rel_Saugrohrdruck 63;
BA_ "GenSigSendType" SG_ 289 MO_rel_Saugrohrdruck_gem_err 0;
BA_ "GenSigSwitchedByIgnition" SG_ 289 MO_rel_Saugrohrdruck_gem_err 0;
BA_ "GenSigSendType" SG_ 289 MO_Schubabschaltung 0;
BA_ "GenSigSwitchedByIgnition" SG_ 289 MO_Schubabschaltung 0;
BA_ "GenSigSendType" SG_ 289 MO_Sig_Fahrpedalgradient 0;
BA_ "GenSigSwitchedByIgnition" SG_ 289 MO_Sig_Fahrpedalgradient 0;
BA_ "GenSigSendType" SG_ 289 MO_Solldrehz_Leerlauf 0;
BA_ "GenSigSwitchedByIgnition" SG_ 289 MO_Solldrehz_Leerlauf 0;
BA_ "GenSigSendType" SG_ 289 MO_StartStopp_StoppVorbereitung 0;
BA_ "GenSigSwitchedByIgnition" SG_ 289 MO_StartStopp_StoppVorbereitung 0;
BA_ "GenSigSendType" SG_ 289 MO_temporaere_Fahrerabwesenheit 0;
BA_ "GenSigSwitchedByIgnition" SG_ 289 MO_temporaere_Fahrerabwesenheit 0;
BA_ "GenSigSendType" SG_ 289 Motor_20_BZ 0;
BA_ "GenSigFuncType" SG_ 289 Motor_20_BZ 1;
BA_ "GenSigSwitchedByIgnition" SG_ 289 Motor_20_BZ 0;
BA_ "GenSigSendType" SG_ 289 Motor_20_CRC 0;
BA_ "GenSigFuncType" SG_ 289 Motor_20_CRC 2;
BA_ "GenSigSwitchedByIgnition" SG_ 289 Motor_20_CRC 0;
BA_ "GenSigSendType" SG_ 289 TSK_a_Soll_gradientenbegrenzt 0;
BA_ "GenSigStartValue" SG_ 289 TSK_a_Soll_gradientenbegrenzt 127;
BA_ "GenSigSwitchedByIgnition" SG_ 289 TSK_a_Soll_gradientenbegrenzt 0;
BA_ "GenSigSendType" SG_ 1423 MO_ITM_Status 0;
BA_ "GenSigStartValue" SG_ 1423 MO_ITM_Status 14;
BA_ "GenSigSwitchedByIgnition" SG_ 1423 MO_ITM_Status 0;
BA_ "Fehlerwert" SG_ 1423 MO_ITM_Status 15;
BA_ "GenSigSendType" SG_ 1423 MO_KJS_LLK_Pos_Summe 0;
BA_ "GenSigStartValue" SG_ 1423 MO_KJS_LLK_Pos_Summe 14;
BA_ "GenSigSwitchedByIgnition" SG_ 1423 MO_KJS_LLK_Pos_Summe 0;
BA_ "GenSigSendType" SG_ 1423 MO_Kuehlmittel_Temp_Rohwert 0;
BA_ "GenSigStartValue" SG_ 1423 MO_Kuehlmittel_Temp_Rohwert 254;
BA_ "GenSigSwitchedByIgnition" SG_ 1423 MO_Kuehlmittel_Temp_Rohwert 0;
BA_ "Fehlerwert" SG_ 1423 MO_Kuehlmittel_Temp_Rohwert 255;
BA_ "GenSigSendType" SG_ 1423 MO_Oel_Temp_Radsatz 0;
BA_ "GenSigStartValue" SG_ 1423 MO_Oel_Temp_Radsatz 254;
BA_ "GenSigSwitchedByIgnition" SG_ 1423 MO_Oel_Temp_Radsatz 0;
BA_ "Fehlerwert" SG_ 1423 MO_Oel_Temp_Radsatz 255;
BA_ "GenSigSendType" SG_ 1423 MO_Tankdruck 0;
BA_ "GenSigStartValue" SG_ 1423 MO_Tankdruck 254;
BA_ "GenSigSwitchedByIgnition" SG_ 1423 MO_Tankdruck 0;
BA_ "Fehlerwert" SG_ 1423 MO_Tankdruck 255;
BA_ "GenSigSendType" SG_ 967 MO_E_Mode 0;
BA_ "GenSigSwitchedByIgnition" SG_ 967 MO_E_Mode 0;
BA_ "GenSigSendType" SG_ 967 MO_E_Texte 0;
BA_ "GenSigSwitchedByIgnition" SG_ 967 MO_E_Texte 0;
BA_ "GenSigSendType" SG_ 967 MO_E_Warnungen 0;
BA_ "GenSigSwitchedByIgnition" SG_ 967 MO_E_Warnungen 0;
BA_ "GenSigSendType" SG_ 967 MO_EFLEX_Lampe 0;
BA_ "GenSigSwitchedByIgnition" SG_ 967 MO_EFLEX_Lampe 0;
BA_ "GenSigSendType" SG_ 967 MO_Heissleuchte 0;
BA_ "GenSigSwitchedByIgnition" SG_ 967 MO_Heissleuchte 0;
BA_ "GenSigSendType" SG_ 967 MO_ITM_Warnung_Pumpe 0;
BA_ "GenSigSwitchedByIgnition" SG_ 967 MO_ITM_Warnung_Pumpe 0;
BA_ "GenSigSendType" SG_ 967 MO_KJS_nicht_bereit 0;
BA_ "GenSigSwitchedByIgnition" SG_ 967 MO_KJS_nicht_bereit 0;
BA_ "Fehlerwert" SG_ 967 MO_KJS_nicht_bereit 1;
BA_ "GenSigStartValue" SG_ 967 MO_Kuehlerluefter_1 126;
BA_ "GenSigSwitchedByIgnition" SG_ 967 MO_Kuehlerluefter_1 0;
BA_ "Fehlerwert" SG_ 967 MO_Kuehlerluefter_1 127;
BA_ "GenSigStartValue" SG_ 967 MO_Kuehlerluefter_2 126;
BA_ "GenSigSwitchedByIgnition" SG_ 967 MO_Kuehlerluefter_2 0;
BA_ "Fehlerwert" SG_ 967 MO_Kuehlerluefter_2 127;
BA_ "GenSigSendType" SG_ 967 MO_Kuehlerluefter_MUX 0;
BA_ "GenSigSwitchedByIgnition" SG_ 967 MO_Kuehlerluefter_MUX 0;
BA_ "GenSigSendType" SG_ 967 MO_OBD2_Lampe 0;
BA_ "GenSigSwitchedByIgnition" SG_ 967 MO_OBD2_Lampe 0;
BA_ "GenSigSendType" SG_ 967 MO_Oelwarnung_max 0;
BA_ "GenSigSwitchedByIgnition" SG_ 967 MO_Oelwarnung_max 0;
BA_ "GenSigSendType" SG_ 967 MO_Partikel_Lampe 0;
BA_ "GenSigSwitchedByIgnition" SG_ 967 MO_Partikel_Lampe 0;
BA_ "GenSigSendType" SG_ 967 MO_RedFahrleistung_Lampe 0;
BA_ "GenSigSwitchedByIgnition" SG_ 967 MO_RedFahrleistung_Lampe 0;
BA_ "GenSigSendType" SG_ 967 MO_Systemlampe 0;
BA_ "GenSigSwitchedByIgnition" SG_ 967 MO_Systemlampe 0;
BA_ "GenSigSendType" SG_ 967 MO_Tankdeckel_Lampe 0;
BA_ "GenSigSwitchedByIgnition" SG_ 967 MO_Tankdeckel_Lampe 0;
BA_ "GenSigSendType" SG_ 967 MO_Text_Motorstart 0;
BA_ "GenSigSwitchedByIgnition" SG_ 967 MO_Text_Motorstart 0;
BA_ "GenSigSendType" SG_ 967 MO_Text_Partikelfil_Reg 0;
BA_ "GenSigSwitchedByIgnition" SG_ 967 MO_Text_Partikelfil_Reg 0;
BA_ "GenSigSendType" SG_ 967 MO_Text_Tankdeckelwarn 0;
BA_ "GenSigSwitchedByIgnition" SG_ 967 MO_Text_Tankdeckelwarn 0;
BA_ "GenSigSendType" SG_ 967 MO_Vorglueh_Lampe 0;
BA_ "GenSigSwitchedByIgnition" SG_ 967 MO_Vorglueh_Lampe 0;
BA_ "GenSigSendType" SG_ 967 MO_Zustand_HWP 0;
BA_ "GenSigStartValue" SG_ 967 MO_Zustand_HWP 1;
BA_ "GenSigSwitchedByIgnition" SG_ 967 MO_Zustand_HWP 0;
BA_ "GenSigSendType" SG_ 967 OLEV_Oelstand_nicht_vorhanden 0;
BA_ "GenSigSwitchedByIgnition" SG_ 967 OLEV_Oelstand_nicht_vorhanden 0;
BA_ "GenSigSendType" SG_ 967 OLEV_Systemstoerung 0;
BA_ "GenSigSwitchedByIgnition" SG_ 967 OLEV_Systemstoerung 0;
BA_ "GenSigSendType" SG_ 967 WIV_Anzeige_aktiv 0;
BA_ "GenSigSwitchedByIgnition" SG_ 967 WIV_Anzeige_aktiv 0;
BA_ "GenSigSendType" SG_ 967 WIV_laufender_Motor 0;
BA_ "GenSigSwitchedByIgnition" SG_ 967 WIV_laufender_Motor 0;
BA_ "GenSigSendType" SG_ 967 WIV_nachfuellanzeige_ein 0;
BA_ "GenSigSwitchedByIgnition" SG_ 967 WIV_nachfuellanzeige_ein 0;
BA_ "GenSigSendType" SG_ 967 WIV_nicht_betriebswarm 0;
BA_ "GenSigSwitchedByIgnition" SG_ 967 WIV_nicht_betriebswarm 0;
BA_ "GenSigSendType" SG_ 967 WIV_Oeldr_Warn_Motor 0;
BA_ "GenSigSwitchedByIgnition" SG_ 967 WIV_Oeldr_Warn_Motor 0;
BA_ "GenSigSendType" SG_ 967 WIV_Oeldyn_avl 0;
BA_ "GenSigSwitchedByIgnition" SG_ 967 WIV_Oeldyn_avl 0;
BA_ "GenSigSendType" SG_ 967 WIV_Oelmenge 0;
BA_ "GenSigSwitchedByIgnition" SG_ 967 WIV_Oelmenge 0;
BA_ "GenSigSendType" SG_ 967 WIV_Oelmin_Warn 0;
BA_ "GenSigSwitchedByIgnition" SG_ 967 WIV_Oelmin_Warn 0;
BA_ "GenSigSendType" SG_ 967 WIV_Oelstand 0;
BA_ "GenSigSwitchedByIgnition" SG_ 967 WIV_Oelstand 0;
BA_ "GenSigSendType" SG_ 967 WIV_Oelstand_nicht_vorhanden 0;
BA_ "GenSigSwitchedByIgnition" SG_ 967 WIV_Oelstand_nicht_vorhanden 0;
BA_ "GenSigSendType" SG_ 967 WIV_Oelsystem_aktiv 0;
BA_ "GenSigSwitchedByIgnition" SG_ 967 WIV_Oelsystem_aktiv 0;
BA_ "GenSigSendType" SG_ 967 WIV_Schieflage 0;
BA_ "GenSigSwitchedByIgnition" SG_ 967 WIV_Schieflage 0;
BA_ "GenSigSendType" SG_ 967 WIV_Sensorfehler 0;
BA_ "GenSigSwitchedByIgnition" SG_ 967 WIV_Sensorfehler 0;
BA_ "GenSigSendType" SG_ 967 WIV_Ueberfuell_deaktiv 0;
BA_ "GenSigSwitchedByIgnition" SG_ 967 WIV_Ueberfuell_deaktiv 0;
BA_ "GenSigSendType" SG_ 967 WIV_Ueberfuell_Warn 0;
BA_ "GenSigSwitchedByIgnition" SG_ 967 WIV_Ueberfuell_Warn 0;
BA_ "GenSigSendType" SG_ 967 WIV_Unterfuell_Warn 0;
BA_ "GenSigSwitchedByIgnition" SG_ 967 WIV_Unterfuell_Warn 0;
BA_ "GenSigSendType" SG_ 340 MO_Drehzahl_VM 0;
BA_ "GenSigSwitchedByIgnition" SG_ 340 MO_Drehzahl_VM 0;
BA_ "GenSigSendType" SG_ 340 MO_Fehlerstatus_Antrieb_FDR 0;
BA_ "GenSigSendType" SG_ 340 MO_IstMoment_VKM 0;
BA_ "GenSigStartValue" SG_ 340 MO_IstMoment_VKM 1022;
BA_ "GenSigSwitchedByIgnition" SG_ 340 MO_IstMoment_VKM 0;
BA_ "GenSigSendType" SG_ 340 MO_Mom_Begr_Schalt 0;
BA_ "GenSigStartValue" SG_ 340 MO_Mom_Begr_Schalt 1022;
BA_ "GenSigSwitchedByIgnition" SG_ 340 MO_Mom_Begr_Schalt 0;
BA_ "GenSigSendType" SG_ 340 MO_Mom_Begr_Schalt_Min 0;
BA_ "GenSigStartValue" SG_ 340 MO_Mom_Begr_Schalt_Min 1022;
BA_ "GenSigSwitchedByIgnition" SG_ 340 MO_Mom_Begr_Schalt_Min 0;
BA_ "GenSigSendType" SG_ 340 MO_Primaerachse_Anforderung 0;
BA_ "GenSigSwitchedByIgnition" SG_ 340 MO_Primaerachse_Anforderung 0;
BA_ "GenSigSendType" SG_ 340 Motor_28_BZ 0;
BA_ "GenSigFuncType" SG_ 340 Motor_28_BZ 1;
BA_ "GenSigSwitchedByIgnition" SG_ 340 Motor_28_BZ 0;
BA_ "GenSigSendType" SG_ 340 Motor_28_CRC 0;
BA_ "GenSigFuncType" SG_ 340 Motor_28_CRC 2;
BA_ "GenSigSwitchedByIgnition" SG_ 340 Motor_28_CRC 0;
BA_ "GenSigSendType" SG_ 283 MO_EBoost_verf_praed 0;
BA_ "GenSigSwitchedByIgnition" SG_ 283 MO_EBoost_verf_praed 0;
BA_ "GenSigSendType" SG_ 283 MO_eLaunch_verf 0;
BA_ "GenSigSwitchedByIgnition" SG_ 283 MO_eLaunch_verf 0;
BA_ "GenSigSendType" SG_ 283 MO_Fahrbereitschaft 3;
BA_ "GenSigSwitchedByIgnition" SG_ 283 MO_Fahrbereitschaft 0;
BA_ "GenSigSendType" SG_ 283 MO_Freilauf_Info 0;
BA_ "GenSigSwitchedByIgnition" SG_ 283 MO_Freilauf_Info 0;
BA_ "GenSigSendType" SG_ 283 MO_Freilauf_Status 3;
BA_ "GenSigSwitchedByIgnition" SG_ 283 MO_Freilauf_Status 0;
BA_ "Fehlerwert" SG_ 283 MO_Freilauf_Status 7;
BA_ "GenSigSendType" SG_ 283 MO_Heckspoiler_Anf 3;
BA_ "GenSigSwitchedByIgnition" SG_ 283 MO_Heckspoiler_Anf 0;
BA_ "GenSigSendType" SG_ 283 MO_Krit_Heckobjekt 0;
BA_ "GenSigSwitchedByIgnition" SG_ 283 MO_Krit_Heckobjekt 0;
BA_ "Fehlerwert" SG_ 283 MO_Krit_Heckobjekt 7;
BA_ "GenSigSendType" SG_ 283 MO_NGS_Gangpos 0;
BA_ "GenSigSwitchedByIgnition" SG_ 283 MO_NGS_Gangpos 0;
BA_ "Fehlerwert" SG_ 283 MO_NGS_Gangpos 7;
BA_ "GenSigSendType" SG_ 283 MO_Parken_WFS_Status 0;
BA_ "GenSigSwitchedByIgnition" SG_ 283 MO_Parken_WFS_Status 0;
BA_ "GenSigSendType" SG_ 283 MO_Positionierung_aktiv 0;
BA_ "GenSigSwitchedByIgnition" SG_ 283 MO_Positionierung_aktiv 0;
BA_ "GenSigSendType" SG_ 1601 MO_Ansaugsystem 0;
BA_ "GenSigFuncType" SG_ 1601 MO_Ansaugsystem 8;
BA_ "GenSigSwitchedByIgnition" SG_ 1601 MO_Ansaugsystem 0;
BA_ "GenSigSendType" SG_ 1601 MO_Anzahl_Zyl 0;
BA_ "GenSigFuncType" SG_ 1601 MO_Anzahl_Zyl 8;
BA_ "GenSigSwitchedByIgnition" SG_ 1601 MO_Anzahl_Zyl 0;
BA_ "GenSigSendType" SG_ 1601 MO_Anzeige_StSt_gueltig 0;
BA_ "GenSigSwitchedByIgnition" SG_ 1601 MO_Anzeige_StSt_gueltig 0;
BA_ "GenSigSendType" SG_ 1601 MO_Code 0;
BA_ "GenSigFuncType" SG_ 1601 MO_Code 8;
BA_ "GenSigSwitchedByIgnition" SG_ 1601 MO_Code 0;
BA_ "GenSigSendType" SG_ 1601 MO_DPF_verbaut 0;
BA_ "GenSigFuncType" SG_ 1601 MO_DPF_verbaut 8;
BA_ "GenSigSwitchedByIgnition" SG_ 1601 MO_DPF_verbaut 0;
BA_ "GenSigSendType" SG_ 1601 MO_Faktor_Momente_02 0;
BA_ "GenSigFuncType" SG_ 1601 MO_Faktor_Momente_02 8;
BA_ "GenSigSwitchedByIgnition" SG_ 1601 MO_Faktor_Momente_02 0;
BA_ "GenSigSendType" SG_ 1601 MO_Getriebe_Code 0;
BA_ "GenSigFuncType" SG_ 1601 MO_Getriebe_Code 8;
BA_ "GenSigSwitchedByIgnition" SG_ 1601 MO_Getriebe_Code 0;
BA_ "GenSigSendType" SG_ 1601 MO_Hubraum 0;
BA_ "GenSigFuncType" SG_ 1601 MO_Hubraum 8;
BA_ "GenSigSwitchedByIgnition" SG_ 1601 MO_Hubraum 0;
BA_ "GenSigSendType" SG_ 1601 MO_Hybridfahrzeug 0;
BA_ "GenSigFuncType" SG_ 1601 MO_Hybridfahrzeug 8;
BA_ "GenSigSwitchedByIgnition" SG_ 1601 MO_Hybridfahrzeug 0;
BA_ "GenSigSendType" SG_ 1601 MO_Kraftstoffart 0;
BA_ "GenSigFuncType" SG_ 1601 MO_Kraftstoffart 8;
BA_ "GenSigSwitchedByIgnition" SG_ 1601 MO_Kraftstoffart 0;
BA_ "GenSigSendType" SG_ 1601 MO_Leistung 0;
BA_ "GenSigFuncType" SG_ 1601 MO_Leistung 8;
BA_ "GenSigSwitchedByIgnition" SG_ 1601 MO_Leistung 0;
BA_ "GenSigSendType" SG_ 1601 MO_OBD_Typ 0;
BA_ "GenSigFuncType" SG_ 1601 MO_OBD_Typ 8;
BA_ "GenSigSwitchedByIgnition" SG_ 1601 MO_OBD_Typ 0;
BA_ "GenSigSendType" SG_ 1601 MO_StartStopp_Codiert 0;
BA_ "GenSigFuncType" SG_ 1601 MO_StartStopp_Codiert 8;
BA_ "GenSigSwitchedByIgnition" SG_ 1601 MO_StartStopp_Codiert 0;
BA_ "GenSigSendType" SG_ 1601 Motor_Code_01_BZ 0;
BA_ "GenSigFuncType" SG_ 1601 Motor_Code_01_BZ 1;
BA_ "GenSigSwitchedByIgnition" SG_ 1601 Motor_Code_01_BZ 0;
BA_ "GenSigSendType" SG_ 1601 Motor_Code_01_CRC 0;
BA_ "GenSigFuncType" SG_ 1601 Motor_Code_01_CRC 2;
BA_ "GenSigSwitchedByIgnition" SG_ 1601 Motor_Code_01_CRC 0;
BA_ "GenSigSendType" SG_ 1601 TSK_Codierung 0;
BA_ "GenSigStartValue" SG_ 1601 TSK_Codierung 7;
BA_ "GenSigSwitchedByIgnition" SG_ 1601 TSK_Codierung 0;
BA_ "GenSigSendType" SG_ 394 MO_Ablaufstatus 0;
BA_ "GenSigSwitchedByIgnition" SG_ 394 MO_Ablaufstatus 0;
BA_ "Fehlerwert" SG_ 394 MO_Ablaufstatus 15;
BA_ "GenSigSendType" SG_ 394 MO_Ablaufstrg_Betriebszustand 0;
BA_ "GenSigSwitchedByIgnition" SG_ 394 MO_Ablaufstrg_Betriebszustand 0;
BA_ "Fehlerwert" SG_ 394 MO_Ablaufstrg_Betriebszustand 7;
BA_ "GenSigSendType" SG_ 394 MO_Ablaufstrg_Kraftschluss2_Ist 0;
BA_ "GenSigSwitchedByIgnition" SG_ 394 MO_Ablaufstrg_Kraftschluss2_Ist 0;
BA_ "GenSigSendType" SG_ 394 MO_Ablaufstrg_Kraftschluss2_Ziel 0;
BA_ "GenSigSwitchedByIgnition" SG_ 394 MO_Ablaufstrg_Kraftschluss2_Ziel 0;
BA_ "GenSigSendType" SG_ 394 MO_Ablaufstrg_Kraftschluss_Ist 0;
BA_ "GenSigSwitchedByIgnition" SG_ 394 MO_Ablaufstrg_Kraftschluss_Ist 0;
BA_ "GenSigSendType" SG_ 394 MO_Ablaufstrg_Kraftschluss_Ziel 0;
BA_ "GenSigSwitchedByIgnition" SG_ 394 MO_Ablaufstrg_Kraftschluss_Ziel 0;
BA_ "GenSigSendType" SG_ 394 MO_Ablaufstrg_Zustand_K0_Ist 0;
BA_ "GenSigSwitchedByIgnition" SG_ 394 MO_Ablaufstrg_Zustand_K0_Ist 0;
BA_ "GenSigSendType" SG_ 394 MO_Ablaufstrg_Zustand_K0_Ziel 0;
BA_ "GenSigSwitchedByIgnition" SG_ 394 MO_Ablaufstrg_Zustand_K0_Ziel 0;
BA_ "GenSigSendType" SG_ 394 MO_Ablaufstrg_Zustand_VKM_Ist 0;
BA_ "GenSigSwitchedByIgnition" SG_ 394 MO_Ablaufstrg_Zustand_VKM_Ist 0;
BA_ "GenSigSendType" SG_ 394 MO_Ablaufstrg_Zustand_VKM_Ziel 0;
BA_ "GenSigSwitchedByIgnition" SG_ 394 MO_Ablaufstrg_Zustand_VKM_Ziel 0;
BA_ "GenSigSendType" SG_ 394 MO_Abstellposition_02 0;
BA_ "GenSigStartValue" SG_ 394 MO_Abstellposition_02 255;
BA_ "GenSigSwitchedByIgnition" SG_ 394 MO_Abstellposition_02 0;
BA_ "GenSigSendType" SG_ 394 MO_Auth_Aufforderung_WFS 0;
BA_ "GenSigSwitchedByIgnition" SG_ 394 MO_Auth_Aufforderung_WFS 0;
BA_ "GenSigSendType" SG_ 394 MO_HYB_Adaption_aktiv 0;
BA_ "GenSigSendType" SG_ 394 MO_HYB_E_Faktor 0;
BA_ "GenSigSwitchedByIgnition" SG_ 394 MO_HYB_E_Faktor 0;
BA_ "GenSigSendType" SG_ 394 MO_HYB_EMode_Info 0;
BA_ "GenSigSwitchedByIgnition" SG_ 394 MO_HYB_EMode_Info 0;
BA_ "GenSigSendType" SG_ 394 MO_HYB_LowSpeedModus 0;
BA_ "GenSigSwitchedByIgnition" SG_ 394 MO_HYB_LowSpeedModus 0;
BA_ "GenSigSendType" SG_ 394 MO_HYB_Stoppmodus 0;
BA_ "GenSigSendType" SG_ 394 MO_Mom_Freiheit_Sekundaerachse 0;
BA_ "GenSigSwitchedByIgnition" SG_ 394 MO_Mom_Freiheit_Sekundaerachse 0;
BA_ "GenSigSendType" SG_ 394 MO_Nachlaufzeit_Kuehlerluefter 0;
BA_ "GenSigSwitchedByIgnition" SG_ 394 MO_Nachlaufzeit_Kuehlerluefter 0;
BA_ "GenSigSendType" SG_ 394 MO_Start_Art 3;
BA_ "GenSigSwitchedByIgnition" SG_ 394 MO_Start_Art 0;
BA_ "GenSigSendType" SG_ 394 MO_Start_Dynamik 0;
BA_ "GenSigSwitchedByIgnition" SG_ 394 MO_Start_Dynamik 0;
BA_ "GenSigSendType" SG_ 394 MO_Tankklappensteuerung 3;
BA_ "GenSigSwitchedByIgnition" SG_ 394 MO_Tankklappensteuerung 0;
BA_ "GenSigSendType" SG_ 1156 ND_GDOP 0;
BA_ "GenSigStartValue" SG_ 1156 ND_GDOP 1022;
BA_ "GenSigSwitchedByIgnition" SG_ 1156 ND_GDOP 0;
BA_ "Fehlerwert" SG_ 1156 ND_GDOP 1023;
BA_ "GenSigSendType" SG_ 1156 ND_HDOP 0;
BA_ "GenSigStartValue" SG_ 1156 ND_HDOP 1022;
BA_ "GenSigSwitchedByIgnition" SG_ 1156 ND_HDOP 0;
BA_ "Fehlerwert" SG_ 1156 ND_HDOP 1023;
BA_ "GenSigSendType" SG_ 1156 ND_Heading 0;
BA_ "GenSigStartValue" SG_ 1156 ND_Heading 4094;
BA_ "GenSigSwitchedByIgnition" SG_ 1156 ND_Heading 0;
BA_ "Fehlerwert" SG_ 1156 ND_Heading 4095;
BA_ "GenSigSendType" SG_ 1156 ND_Init 0;
BA_ "GenSigSwitchedByIgnition" SG_ 1156 ND_Init 0;
BA_ "GenSigSendType" SG_ 1156 ND_PDOP 0;
BA_ "GenSigStartValue" SG_ 1156 ND_PDOP 1022;
BA_ "GenSigSwitchedByIgnition" SG_ 1156 ND_PDOP 0;
BA_ "Fehlerwert" SG_ 1156 ND_PDOP 1023;
BA_ "GenSigSendType" SG_ 1156 ND_TDOP 0;
BA_ "GenSigStartValue" SG_ 1156 ND_TDOP 1022;
BA_ "GenSigSwitchedByIgnition" SG_ 1156 ND_TDOP 0;
BA_ "Fehlerwert" SG_ 1156 ND_TDOP 1023;
BA_ "GenSigSendType" SG_ 1156 ND_VDOP 0;
BA_ "GenSigStartValue" SG_ 1156 ND_VDOP 1022;
BA_ "GenSigSwitchedByIgnition" SG_ 1156 ND_VDOP 0;
BA_ "Fehlerwert" SG_ 1156 ND_VDOP 1023;
BA_ "GenSigSendType" SG_ 1157 ND_SatInUse 0;
BA_ "GenSigStartValue" SG_ 1157 ND_SatInUse 30;
BA_ "GenSigSwitchedByIgnition" SG_ 1157 ND_SatInUse 0;
BA_ "Fehlerwert" SG_ 1157 ND_SatInUse 31;
BA_ "GenSigSendType" SG_ 1157 ND_SatInView 0;
BA_ "GenSigStartValue" SG_ 1157 ND_SatInView 30;
BA_ "GenSigSwitchedByIgnition" SG_ 1157 ND_SatInView 0;
BA_ "Fehlerwert" SG_ 1157 ND_SatInView 31;
BA_ "GenSigSendType" SG_ 1157 ND_UTC 0;
BA_ "GenSigSwitchedByIgnition" SG_ 1157 ND_UTC 0;
BA_ "GenSigSendType" SG_ 1157 NP_Altitude 0;
BA_ "GenSigStartValue" SG_ 1157 NP_Altitude 4094;
BA_ "GenSigSwitchedByIgnition" SG_ 1157 NP_Altitude 0;
BA_ "Fehlerwert" SG_ 1157 NP_Altitude 4095;
BA_ "GenSigSendType" SG_ 2527679512 ND_Fuelstation_detected 0;
BA_ "GenSigStartValue" SG_ 2527679512 ND_Fuelstation_detected 3;
BA_ "GenSigSwitchedByIgnition" SG_ 2527679512 ND_Fuelstation_detected 0;
BA_ "GenSigSendType" SG_ 2527679512 ND_NrSameMeasure 0;
BA_ "GenSigSwitchedByIgnition" SG_ 2527679512 ND_NrSameMeasure 0;
BA_ "GenSigSendType" SG_ 2527679512 ND_RecDelay 0;
BA_ "GenSigStartValue" SG_ 2527679512 ND_RecDelay 4094;
BA_ "GenSigSwitchedByIgnition" SG_ 2527679512 ND_RecDelay 0;
BA_ "Fehlerwert" SG_ 2527679512 ND_RecDelay 4095;
BA_ "GenSigSendType" SG_ 2527679512 ND_RouteType 0;
BA_ "GenSigSwitchedByIgnition" SG_ 2527679512 ND_RouteType 0;
BA_ "GenSigSendType" SG_ 2527679512 ND_SendDelay 0;
BA_ "GenSigStartValue" SG_ 2527679512 ND_SendDelay 4094;
BA_ "GenSigSwitchedByIgnition" SG_ 2527679512 ND_SendDelay 0;
BA_ "Fehlerwert" SG_ 2527679512 ND_SendDelay 4095;
BA_ "GenSigSendType" SG_ 2527679512 ND_TimeOffset 0;
BA_ "GenSigSwitchedByIgnition" SG_ 2527679512 ND_TimeOffset 0;
BA_ "GenSigSendType" SG_ 2527679512 ND_TimeToDestination 0;
BA_ "GenSigStartValue" SG_ 2527679512 ND_TimeToDestination 511;
BA_ "GenSigSwitchedByIgnition" SG_ 2527679512 ND_TimeToDestination 0;
BA_ "Fehlerwert" SG_ 2527679512 ND_TimeToDestination 510;
BA_ "GenSigSendType" SG_ 2527679512 ND_Timezone_DaylightSavingOffset 0;
BA_ "GenSigSwitchedByIgnition" SG_ 2527679512 ND_Timezone_DaylightSavingOffset 0;
BA_ "GenSigSendType" SG_ 2527679512 ND_Timezone_Offset 0;
BA_ "GenSigStartValue" SG_ 2527679512 ND_Timezone_Offset 14;
BA_ "GenSigSwitchedByIgnition" SG_ 2527679512 ND_Timezone_Offset 0;
BA_ "Fehlerwert" SG_ 2527679512 ND_Timezone_Offset 15;
BA_ "GenSigSendType" SG_ 2527679512 ND_Timezone_SignBit 0;
BA_ "GenSigSwitchedByIgnition" SG_ 2527679512 ND_Timezone_SignBit 0;
BA_ "GenSigSendType" SG_ 2527679512 ND_Timezone_Validity 0;
BA_ "GenSigSwitchedByIgnition" SG_ 2527679512 ND_Timezone_Validity 0;
BA_ "GenSigSendType" SG_ 2527679512 ND_Velocity 0;
BA_ "GenSigStartValue" SG_ 2527679512 ND_Velocity 1022;
BA_ "GenSigSwitchedByIgnition" SG_ 2527679512 ND_Velocity 0;
BA_ "Fehlerwert" SG_ 2527679512 ND_Velocity 1023;
BA_ "GenSigSendType" SG_ 1158 NP_Fix 0;
BA_ "GenSigSwitchedByIgnition" SG_ 1158 NP_Fix 0;
BA_ "GenSigSendType" SG_ 1158 NP_LatDegree 0;
BA_ "GenSigStartValue" SG_ 1158 NP_LatDegree 134217726;
BA_ "GenSigSwitchedByIgnition" SG_ 1158 NP_LatDegree 0;
BA_ "Fehlerwert" SG_ 1158 NP_LatDegree 134217727;
BA_ "GenSigSendType" SG_ 1158 NP_LatDirection 0;
BA_ "GenSigStartValue" SG_ 1158 NP_LatDirection 1;
BA_ "GenSigSwitchedByIgnition" SG_ 1158 NP_LatDirection 0;
BA_ "GenSigSendType" SG_ 1158 NP_LongDegree 0;
BA_ "GenSigStartValue" SG_ 1158 NP_LongDegree 268435454;
BA_ "GenSigSwitchedByIgnition" SG_ 1158 NP_LongDegree 0;
BA_ "Fehlerwert" SG_ 1158 NP_LongDegree 268435455;
BA_ "GenSigSendType" SG_ 1158 NP_LongDirection 0;
BA_ "GenSigStartValue" SG_ 1158 NP_LongDirection 1;
BA_ "GenSigSwitchedByIgnition" SG_ 1158 NP_LongDirection 0;
BA_ "GenSigSendType" SG_ 1158 NP_Sat 0;
BA_ "GenSigStartValue" SG_ 1158 NP_Sat 30;
BA_ "GenSigSwitchedByIgnition" SG_ 1158 NP_Sat 0;
BA_ "Fehlerwert" SG_ 1158 NP_Sat 31;
BA_ "GenSigSwitchedByIgnition" SG_ 2589283496 POS_Heading 0;
BA_ "GenSigSwitchedByIgnition" SG_ 2589283496 POS_Heading_Trust 0;
BA_ "Fehlerwert" SG_ 2589283496 POS_Heading_Trust 3;
BA_ "GenSigSwitchedByIgnition" SG_ 2589283496 POS_Last_GPS_Sync 0;
BA_ "GenSigStartValue" SG_ 2589283496 POS_LatDegree 134217726;
BA_ "GenSigSwitchedByIgnition" SG_ 2589283496 POS_LatDegree 0;
BA_ "Fehlerwert" SG_ 2589283496 POS_LatDegree 134217727;
BA_ "GenSigSwitchedByIgnition" SG_ 2589283496 POS_LatDirection 0;
BA_ "GenSigStartValue" SG_ 2589283496 POS_LongDegree 268435454;
BA_ "GenSigSwitchedByIgnition" SG_ 2589283496 POS_LongDegree 0;
BA_ "Fehlerwert" SG_ 2589283496 POS_LongDegree 268435455;
BA_ "GenSigSwitchedByIgnition" SG_ 2589283496 POS_LongDirection 0;
BA_ "GenSigSendType" SG_ 2589283496 POS_MUX 0;
BA_ "GenSigStartValue" SG_ 2589283496 POS_MUX 3;
BA_ "GenSigSwitchedByIgnition" SG_ 2589283496 POS_MUX 0;
BA_ "GenSigSendType" SG_ 2589283496 POS_ODD_EVEN 0;
BA_ "GenSigSwitchedByIgnition" SG_ 2589283496 POS_ODD_EVEN 0;
BA_ "GenSigSwitchedByIgnition" SG_ 2589283496 POS_PosStati 0;
BA_ "GenSigSwitchedByIgnition" SG_ 2589283496 POS_UTC_REF 0;
BA_ "GenSigSendType" SG_ 2527679647 NFC_aktiv 0;
BA_ "GenSigSwitchedByIgnition" SG_ 2527679647 NFC_aktiv 0;
BA_ "GenSigSendType" SG_ 2527679647 NFC_ESM_aktivieren 0;
BA_ "GenSigSwitchedByIgnition" SG_ 2527679647 NFC_ESM_aktivieren 0;
BA_ "GenSigSendType" SG_ 2527679647 NFC_Front_Entr_Authorisiert 0;
BA_ "GenSigSwitchedByIgnition" SG_ 2527679647 NFC_Front_Entr_Authorisiert 0;
BA_ "GenSigSendType" SG_ 2527679647 NFC_Front_Verr_Authorisiert 0;
BA_ "GenSigSwitchedByIgnition" SG_ 2527679647 NFC_Front_Verr_Authorisiert 0;
BA_ "GenSigSendType" SG_ 2527679647 NFC_FT_Entriegelung_Authorisiert 0;
BA_ "GenSigSwitchedByIgnition" SG_ 2527679647 NFC_FT_Entriegelung_Authorisiert 0;
BA_ "GenSigSendType" SG_ 2527679647 NFC_FT_Verriegelung_Authorisiert 0;
BA_ "GenSigSwitchedByIgnition" SG_ 2527679647 NFC_FT_Verriegelung_Authorisiert 0;
BA_ "GenSigSendType" SG_ 2527679647 NFC_HD_Entriegelung_Authorisiert 0;
BA_ "GenSigSwitchedByIgnition" SG_ 2527679647 NFC_HD_Entriegelung_Authorisiert 0;
BA_ "GenSigSendType" SG_ 2527679647 NFC_HD_Verriegelung_Authorisiert 0;
BA_ "GenSigSwitchedByIgnition" SG_ 2527679647 NFC_HD_Verriegelung_Authorisiert 0;
BA_ "GenSigSendType" SG_ 2527679647 NFC_Laden_unterbrechen 0;
BA_ "GenSigSwitchedByIgnition" SG_ 2527679647 NFC_Laden_unterbrechen 0;
BA_ "GenSigSendType" SG_ 2527679647 Stellgliedtest_NFC 0;
BA_ "GenSigSwitchedByIgnition" SG_ 2527679647 Stellgliedtest_NFC 0;
BA_ "GenSigSendType" SG_ 2527679647 ZV_auf_NFC 0;
BA_ "GenSigSwitchedByIgnition" SG_ 2527679647 ZV_auf_NFC 0;
BA_ "GenSigSendType" SG_ 2527679647 ZV_zu_NFC 0;
BA_ "GenSigSwitchedByIgnition" SG_ 2527679647 ZV_zu_NFC 0;
BA_ "GenSigSendType" SG_ 1696 NV_Akt_Status_MMI 3;
BA_ "GenSigStartValue" SG_ 1696 NV_Akt_Status_MMI 3;
BA_ "GenSigSendType" SG_ 1696 NV_aktiv 3;
BA_ "GenSigSendType" SG_ 1696 NV_Akustik_deaktiviert_Icon 3;
BA_ "GenSigSendType" SG_ 1696 NV_Anf_Prefill 3;
BA_ "GenSigSendType" SG_ 1696 NV_AnforderungBildaufschaltung 3;
BA_ "GenSigSendType" SG_ 1696 NV_FAS_Fkt_Status 0;
BA_ "Fehlerwert" SG_ 1696 NV_FAS_Fkt_Status 3;
BA_ "GenSigSendType" SG_ 1696 NV_FGM_deaktiviert_Icon 3;
BA_ "GenSigSendType" SG_ 1696 NV_Gong 3;
BA_ "GenSigSendType" SG_ 1696 NV_HBA_Parameter 3;
BA_ "GenSigSendType" SG_ 1696 NV_Hinweise 3;
BA_ "GenSigSendType" SG_ 1696 NV_LED_Leiste 3;
BA_ "GenSigSendType" SG_ 1696 NV_Markierungslicht_links 3;
BA_ "GenSigSendType" SG_ 1696 NV_Markierungslicht_rechts 3;
BA_ "GenSigSendType" SG_ 1696 NV_Piktogramm_aktiv 3;
BA_ "GenSigSendType" SG_ 1696 NV_PreSense_Modus_System 3;
BA_ "GenSigSendType" SG_ 1696 NV_PreSense_Modus_Warnung 3;
BA_ "GenSigSendType" SG_ 1696 NV_PreSense_Status 3;
BA_ "GenSigSendType" SG_ 1696 NV_Symbol 3;
BA_ "GenSigSendType" SG_ 1696 NV_Symbol_Tierwarnung 3;
BA_ "GenSigSendType" SG_ 1696 NV_Texte 3;
BA_ "GenSigActiveRepetitions" SG_ 2600468494 NM_BCM1_CAB 3;
BA_ "GenSigSendType" SG_ 2600468494 NM_BCM1_CAB 4;
BA_ "GenSigSwitchedByIgnition" SG_ 2600468494 NM_BCM1_CAB 0;
BA_ "GenSigSendType" SG_ 2600468494 NM_BCM1_Car_Wakeup 3;
BA_ "GenSigSwitchedByIgnition" SG_ 2600468494 NM_BCM1_Car_Wakeup 0;
BA_ "GenSigSwitchedByIgnition" SG_ 2600468494 NM_BCM1_CBV_AWB 0;
BA_ "GenSigFuncType" SG_ 2600468494 NM_BCM1_CBV_CRI 8;
BA_ "GenSigSwitchedByIgnition" SG_ 2600468494 NM_BCM1_CBV_CRI 0;
BA_ "GenSigSwitchedByIgnition" SG_ 2600468494 NM_BCM1_NM_aktiv_Aussenlicht 0;
BA_ "GenSigSwitchedByIgnition" SG_ 2600468494 NM_BCM1_NM_aktiv_ComingHome 0;
BA_ "GenSigSwitchedByIgnition" SG_ 2600468494 NM_BCM1_NM_aktiv_Diagnose 0;
BA_ "GenSigSwitchedByIgnition" SG_ 2600468494 NM_BCM1_NM_aktiv_Innenlicht_Dim 0;
BA_ "GenSigSwitchedByIgnition" SG_ 2600468494 NM_BCM1_NM_aktiv_KL15 0;
BA_ "GenSigSwitchedByIgnition" SG_ 2600468494 NM_BCM1_NM_aktiv_Klimatisierung 0;
BA_ "GenSigSwitchedByIgnition" SG_ 2600468494 NM_BCM1_NM_aktiv_LeavingHome 0;
BA_ "GenSigSwitchedByIgnition" SG_ 2600468494 NM_BCM1_NM_aktiv_LIM 0;
BA_ "GenSigSwitchedByIgnition" SG_ 2600468494 NM_BCM1_NM_aktiv_Notlaufblinken 0;
BA_ "GenSigSwitchedByIgnition" SG_ 2600468494 NM_BCM1_NM_aktiv_Taster_Schalter 0;
BA_ "GenSigSwitchedByIgnition" SG_ 2600468494 NM_BCM1_NM_aktiv_Tmin 0;
BA_ "GenSigSwitchedByIgnition" SG_ 2600468494 NM_BCM1_NM_State 0;
BA_ "GenSigStartValue" SG_ 2600468494 NM_BCM1_SNI 14;
BA_ "GenSigSwitchedByIgnition" SG_ 2600468494 NM_BCM1_SNI 0;
BA_ "GenSigSwitchedByIgnition" SG_ 2600468494 NM_BCM1_UDS_CC 0;
BA_ "GenSigActiveRepetitions" SG_ 2600468496 NM_Gateway_CAB 3;
BA_ "GenSigSendType" SG_ 2600468496 NM_Gateway_CAB 4;
BA_ "GenSigSwitchedByIgnition" SG_ 2600468496 NM_Gateway_CAB 0;
BA_ "GenSigSendType" SG_ 2600468496 NM_Gateway_Car_Wakeup 3;
BA_ "GenSigSwitchedByIgnition" SG_ 2600468496 NM_Gateway_Car_Wakeup 0;
BA_ "GenSigSwitchedByIgnition" SG_ 2600468496 NM_Gateway_CBV_AWB 0;
BA_ "GenSigFuncType" SG_ 2600468496 NM_Gateway_CBV_CRI 8;
BA_ "GenSigSwitchedByIgnition" SG_ 2600468496 NM_Gateway_CBV_CRI 0;
BA_ "GenSigSwitchedByIgnition" SG_ 2600468496 NM_Gateway_NM_aktiv_Buskopplung 0;
BA_ "GenSigSwitchedByIgnition" SG_ 2600468496 NM_Gateway_NM_aktiv_Connect 0;
BA_ "GenSigSwitchedByIgnition" SG_ 2600468496 NM_Gateway_NM_aktiv_CWU 0;
BA_ "GenSigSwitchedByIgnition" SG_ 2600468496 NM_Gateway_NM_aktiv_Diagnose 0;
BA_ "GenSigSwitchedByIgnition" SG_ 2600468496 NM_Gateway_NM_aktiv_EM 0;
BA_ "GenSigSwitchedByIgnition" SG_ 2600468496 NM_Gateway_NM_aktiv_FC 0;
BA_ "GenSigSwitchedByIgnition" SG_ 2600468496 NM_Gateway_NM_aktiv_KL15 0;
BA_ "GenSigSwitchedByIgnition" SG_ 2600468496 NM_Gateway_NM_aktiv_OBDC 0;
BA_ "GenSigSwitchedByIgnition" SG_ 2600468496 NM_Gateway_NM_aktiv_Tmin 0;
BA_ "GenSigSwitchedByIgnition" SG_ 2600468496 NM_Gateway_NM_State 0;
BA_ "GenSigStartValue" SG_ 2600468496 NM_Gateway_SNI 16;
BA_ "GenSigSwitchedByIgnition" SG_ 2600468496 NM_Gateway_SNI 0;
BA_ "GenSigSwitchedByIgnition" SG_ 2600468496 NM_Gateway_UDS_CC 0;
BA_ "GenSigActiveRepetitions" SG_ 2600468550 NM_Klima_CAB 3;
BA_ "GenSigSendType" SG_ 2600468550 NM_Klima_CAB 4;
BA_ "GenSigSwitchedByIgnition" SG_ 2600468550 NM_Klima_CAB 0;
BA_ "GenSigSendType" SG_ 2600468550 NM_Klima_Car_Wakeup 3;
BA_ "GenSigSwitchedByIgnition" SG_ 2600468550 NM_Klima_Car_Wakeup 0;
BA_ "GenSigSwitchedByIgnition" SG_ 2600468550 NM_Klima_CBV_AWB 0;
BA_ "GenSigFuncType" SG_ 2600468550 NM_Klima_CBV_CRI 8;
BA_ "GenSigSwitchedByIgnition" SG_ 2600468550 NM_Klima_CBV_CRI 0;
BA_ "GenSigSwitchedByIgnition" SG_ 2600468550 NM_Klima_NM_aktiv_Abstellzstd 0;
BA_ "GenSigSwitchedByIgnition" SG_ 2600468550 NM_Klima_NM_aktiv_Diagnose 0;
BA_ "GenSigSwitchedByIgnition" SG_ 2600468550 NM_Klima_NM_aktiv_KL15 0;
BA_ "GenSigSwitchedByIgnition" SG_ 2600468550 NM_Klima_NM_aktiv_Tmin 0;
BA_ "GenSigSwitchedByIgnition" SG_ 2600468550 NM_Klima_NM_State 0;
BA_ "GenSigStartValue" SG_ 2600468550 NM_Klima_SNI 70;
BA_ "GenSigSwitchedByIgnition" SG_ 2600468550 NM_Klima_SNI 0;
BA_ "GenSigSwitchedByIgnition" SG_ 2600468550 NM_Klima_UDS_CC 0;
BA_ "GenSigActiveRepetitions" SG_ 2600468569 NM_Lift_VA_CAB 3;
BA_ "GenSigSendType" SG_ 2600468569 NM_Lift_VA_CAB 4;
BA_ "GenSigSwitchedByIgnition" SG_ 2600468569 NM_Lift_VA_CAB 0;
BA_ "GenSigSendType" SG_ 2600468569 NM_Lift_VA_Car_Wakeup 3;
BA_ "GenSigSwitchedByIgnition" SG_ 2600468569 NM_Lift_VA_Car_Wakeup 0;
BA_ "GenSigSwitchedByIgnition" SG_ 2600468569 NM_Lift_VA_CBV_AWB 0;
BA_ "GenSigSwitchedByIgnition" SG_ 2600468569 NM_Lift_VA_CBV_CRI 0;
BA_ "GenSigSwitchedByIgnition" SG_ 2600468569 NM_Lift_VA_NM_aktiv_Diag 0;
BA_ "GenSigSwitchedByIgnition" SG_ 2600468569 NM_Lift_VA_NM_aktiv_KL15 0;
BA_ "GenSigSwitchedByIgnition" SG_ 2600468569 NM_Lift_VA_NM_aktiv_Tmin 0;
BA_ "GenSigSwitchedByIgnition" SG_ 2600468569 NM_Lift_VA_NM_State 0;
BA_ "GenSigStartValue" SG_ 2600468569 NM_Lift_VA_SNI 89;
BA_ "GenSigSwitchedByIgnition" SG_ 2600468569 NM_Lift_VA_SNI 0;
BA_ "GenSigSwitchedByIgnition" SG_ 2600468569 NM_Lift_VA_UDS_CC 0;
BA_ "GenSigActiveRepetitions" SG_ 2600468676 NM_VAS_L_CAB 3;
BA_ "GenSigSendType" SG_ 2600468676 NM_VAS_L_CAB 4;
BA_ "GenSigSwitchedByIgnition" SG_ 2600468676 NM_VAS_L_CAB 0;
BA_ "GenSigSendType" SG_ 2600468676 NM_VAS_L_Car_Wakeup 3;
BA_ "GenSigSwitchedByIgnition" SG_ 2600468676 NM_VAS_L_Car_Wakeup 0;
BA_ "GenSigSwitchedByIgnition" SG_ 2600468676 NM_VAS_L_CBV_AWB 0;
BA_ "GenSigSwitchedByIgnition" SG_ 2600468676 NM_VAS_L_CBV_CRI 0;
BA_ "GenSigSwitchedByIgnition" SG_ 2600468676 NM_VAS_L_NM_aktiv_Diagnose 0;
BA_ "GenSigSwitchedByIgnition" SG_ 2600468676 NM_VAS_L_NM_aktiv_KL15 0;
BA_ "GenSigSwitchedByIgnition" SG_ 2600468676 NM_VAS_L_NM_aktiv_Tmin 0;
BA_ "GenSigSwitchedByIgnition" SG_ 2600468676 NM_VAS_L_NM_aktiv_Verstellung 0;
BA_ "GenSigSwitchedByIgnition" SG_ 2600468676 NM_VAS_L_NM_State 0;
BA_ "GenSigStartValue" SG_ 2600468676 NM_VAS_L_SNI 196;
BA_ "GenSigSwitchedByIgnition" SG_ 2600468676 NM_VAS_L_SNI 0;
BA_ "GenSigSwitchedByIgnition" SG_ 2600468676 NM_VAS_L_UDS_CC 0;
BA_ "GenSigActiveRepetitions" SG_ 2600468677 NM_VAS_R_CAB 3;
BA_ "GenSigSendType" SG_ 2600468677 NM_VAS_R_CAB 4;
BA_ "GenSigSwitchedByIgnition" SG_ 2600468677 NM_VAS_R_CAB 0;
BA_ "GenSigSendType" SG_ 2600468677 NM_VAS_R_Car_Wakeup 3;
BA_ "GenSigSwitchedByIgnition" SG_ 2600468677 NM_VAS_R_Car_Wakeup 0;
BA_ "GenSigSwitchedByIgnition" SG_ 2600468677 NM_VAS_R_CBV_AWB 0;
BA_ "GenSigSwitchedByIgnition" SG_ 2600468677 NM_VAS_R_CBV_CRI 0;
BA_ "GenSigSwitchedByIgnition" SG_ 2600468677 NM_VAS_R_NM_aktiv_Diagnose 0;
BA_ "GenSigSwitchedByIgnition" SG_ 2600468677 NM_VAS_R_NM_aktiv_KL15 0;
BA_ "GenSigSwitchedByIgnition" SG_ 2600468677 NM_VAS_R_NM_aktiv_Tmin 0;
BA_ "GenSigSwitchedByIgnition" SG_ 2600468677 NM_VAS_R_NM_aktiv_Verstellung 0;
BA_ "GenSigSwitchedByIgnition" SG_ 2600468677 NM_VAS_R_NM_State 0;
BA_ "GenSigStartValue" SG_ 2600468677 NM_VAS_R_SNI 197;
BA_ "GenSigSwitchedByIgnition" SG_ 2600468677 NM_VAS_R_SNI 0;
BA_ "GenSigSwitchedByIgnition" SG_ 2600468677 NM_VAS_R_UDS_CC 0;
BA_REL_ "GenSigTimeoutTime" BU_SG_REL_ BCM1 SG_ 958 MO_StartStopp_Status 1000;
BA_REL_ "GenSigTimeoutTime" BU_SG_REL_ BCM1 SG_ 958 MO_StartStopp_Wiederstart 1000;
BA_REL_ "GenSigTimeoutTime" BU_SG_REL_ BCM1 SG_ 958 MO_StartStopp_Motorstopp 1000;
BA_REL_ "GenSigTimeoutTime" BU_SG_REL_ BCM1 SG_ 958 MO_Kl_75 1000;
BA_REL_ "GenSigTimeoutTime" BU_SG_REL_ BCM1 SG_ 958 MO_Gangposition 1000;
BA_REL_ "GenSigTimeoutTime" BU_SG_REL_ BCM1 SG_ 958 MO_StartStopp_Fahrerwunsch 1000;
BA_REL_ "GenSigTimeoutTime" BU_SG_REL_ BCM1 SG_ 958 MO_HYB_Fahrbereitschaft 1000;
BA_REL_ "GenSigTimeoutTime" BU_SG_REL_ BCM1 SG_ 958 MO_Ext_E_Fahrt_aktiv 1000;
BA_REL_ "GenSigTimeoutTime" BU_SG_REL_ BCM1 SG_ 958 MO_Fahrer_bremst 1000;
BA_REL_ "GenSigTimeoutTime" BU_SG_REL_ BCM1 SG_ 958 MO_QBit_Fahrer_bremst 1000;
BA_REL_ "GenSigTimeoutTime" BU_SG_REL_ BCM1 SG_ 958 MO_BLS 1000;
BA_REL_ "GenSigTimeoutTime" BU_SG_REL_ BCM1 SG_ 958 MO_Klima_Eingr 1000;
BA_REL_ "GenSigTimeoutTime" BU_SG_REL_ BCM1 SG_ 958 MO_Kuppl_schalter 1000;
BA_REL_ "GenSigTimeoutTime" BU_SG_REL_ BCM1 SG_ 958 MO_Interlock 1000;
BA_REL_ "GenSigTimeoutTime" BU_SG_REL_ BCM1 SG_ 958 MO_Motor_laeuft 1000;
BA_REL_ "GenSigTimeoutTime" BU_SG_REL_ BCM1 SG_ 958 MO_Kickdown 1000;
BA_REL_ "GenSigTimeoutTime" BU_SG_REL_ BCM1 SG_ 958 MO_QBit_KL_75 1000;
BA_REL_ "GenSigTimeoutTime" BU_SG_REL_ BCM1 SG_ 958 MO_FMAus_aktiv 1000;
BA_REL_ "GenSigTimeoutTime" BU_SG_REL_ BCM1 SG_ 958 MO_HYB_VM_aktiv 1000;
BA_REL_ "GenSigTimeoutTime" BU_SG_REL_ BCM1 SG_ 1631 TSK_QBit_Steigung 3200;
BA_REL_ "GenSigTimeoutTime" BU_SG_REL_ BCM1 SG_ 1631 TSK_Steigung_02 3200;
BA_REL_ "GenSigTimeoutTime" BU_SG_REL_ BCM1 SG_ 812 MO_BZS_Charisma_FahrPr 2000;
BA_REL_ "GenSigTimeoutTime" BU_SG_REL_ BCM1 SG_ 1648 MO_Abstellzeit 5000;
BA_REL_ "GenSigTimeoutTime" BU_SG_REL_ BCM1 SG_ 1648 MO_Abstellzeit_Status 5000;
BA_REL_ "GenSigTimeoutTime" BU_SG_REL_ BCM1 SG_ 1648 MO_Hybrid_StartStopp_LED 5000;
BA_REL_ "GenSigTimeoutTime" BU_SG_REL_ BCM1 SG_ 289 MO_Fahrpedalrohwert_01 500;
BA_REL_ "GenSigTimeoutTime" BU_SG_REL_ BCM1 SG_ 1423 MO_ITM_Status 3200;
BA_REL_ "GenSigTimeoutTime" BU_SG_REL_ BCM1 SG_ 967 MO_Kuehlerluefter_MUX 800;
BA_REL_ "GenSigTimeoutTime" BU_SG_REL_ BCM1 SG_ 967 MO_Kuehlerluefter_1 800;
BA_REL_ "GenSigTimeoutTime" BU_SG_REL_ BCM1 SG_ 967 MO_Kuehlerluefter_2 800;
BA_REL_ "GenSigTimeoutTime" BU_SG_REL_ BCM1 SG_ 340 MO_Drehzahl_VM 2000;
BA_REL_ "GenSigTimeoutTime" BU_SG_REL_ BCM1 SG_ 283 MO_Fahrbereitschaft 5000;
BA_REL_ "GenSigTimeoutTime" BU_SG_REL_ BCM1 SG_ 1601 Motor_Code_01_CRC 5000;
BA_REL_ "GenSigTimeoutTime" BU_SG_REL_ BCM1 SG_ 1601 Motor_Code_01_BZ 5000;
BA_REL_ "GenSigTimeoutTime" BU_SG_REL_ BCM1 SG_ 1601 MO_Faktor_Momente_02 5000;
BA_REL_ "GenSigTimeoutTime" BU_SG_REL_ BCM1 SG_ 1601 MO_Hybridfahrzeug 5000;
BA_REL_ "GenSigTimeoutTime" BU_SG_REL_ BCM1 SG_ 1601 MO_Code 5000;
BA_REL_ "GenSigTimeoutTime" BU_SG_REL_ BCM1 SG_ 1601 MO_Getriebe_Code 5000;
BA_REL_ "GenSigTimeoutTime" BU_SG_REL_ BCM1 SG_ 1601 MO_Kraftstoffart 5000;
BA_REL_ "GenSigTimeoutTime" BU_SG_REL_ BCM1 SG_ 1601 MO_OBD_Typ 5000;
BA_REL_ "GenSigTimeoutTime" BU_SG_REL_ BCM1 SG_ 394 MO_Start_Art 2000;
BA_REL_ "GenSigTimeoutTime" BU_SG_REL_ BCM1 SG_ 1156 ND_Heading 5000;
BA_REL_ "GenSigTimeoutTime" BU_SG_REL_ BCM1 SG_ 1156 ND_Init 5000;
BA_REL_ "GenSigTimeoutTime" BU_SG_REL_ BCM1 SG_ 1157 NP_Altitude 5000;
BA_REL_ "GenSigTimeoutTime" BU_SG_REL_ BCM1 SG_ 1157 ND_UTC 5000;
BA_REL_ "GenSigTimeoutTime" BU_SG_REL_ BCM1 SG_ 1158 NP_LatDegree 5000;
BA_REL_ "GenSigTimeoutTime" BU_SG_REL_ BCM1 SG_ 1158 NP_LongDegree 5000;
BA_REL_ "GenSigTimeoutTime" BU_SG_REL_ BCM1 SG_ 1158 NP_LatDirection 5000;
BA_REL_ "GenSigTimeoutTime" BU_SG_REL_ BCM1 SG_ 1158 NP_LongDirection 5000;
BA_REL_ "GenSigTimeoutTime" BU_SG_REL_ BCM1 SG_ 2527679647 ZV_auf_NFC 2000;
BA_REL_ "GenSigTimeoutTime" BU_SG_REL_ BCM1 SG_ 2527679647 ZV_zu_NFC 2000;
BA_REL_ "GenSigTimeoutTime" BU_SG_REL_ BCM1 SG_ 2527679647 NFC_Front_Verr_Authorisiert 2000;
BA_REL_ "GenSigTimeoutTime" BU_SG_REL_ BCM1 SG_ 2527679647 NFC_Front_Entr_Authorisiert 2000;
BA_REL_ "GenSigTimeoutTime" BU_SG_REL_ BCM1 SG_ 1696 NV_Symbol 2000;
BA_REL_ "GenSigTimeoutTime" BU_SG_REL_ BCM1 SG_ 1696 NV_Symbol_Tierwarnung 2000;
BA_REL_ "GenSigTimeoutTime" BU_SG_REL_ BCM1 SG_ 2600468494 NM_BCM1_SNI 2000;
BA_REL_ "GenSigTimeoutTime" BU_SG_REL_ BCM1 SG_ 2600468494 NM_BCM1_CBV_CRI 2000;
BA_REL_ "GenSigTimeoutTime" BU_SG_REL_ BCM1 SG_ 2600468494 NM_BCM1_CAB 2000;
BA_REL_ "GenSigTimeoutTime" BU_SG_REL_ BCM1 SG_ 2600468496 NM_Gateway_SNI 2000;
BA_REL_ "GenSigTimeoutTime" BU_SG_REL_ BCM1 SG_ 2600468496 NM_Gateway_CBV_CRI 2000;
BA_REL_ "GenSigTimeoutTime" BU_SG_REL_ BCM1 SG_ 2600468496 NM_Gateway_CAB 2000;
BA_REL_ "GenSigTimeoutTime" BU_SG_REL_ BCM1 SG_ 2600468550 NM_Klima_SNI 2000;
BA_REL_ "GenSigTimeoutTime" BU_SG_REL_ BCM1 SG_ 2600468550 NM_Klima_CBV_CRI 2000;
BA_REL_ "GenSigTimeoutTime" BU_SG_REL_ BCM1 SG_ 2600468550 NM_Klima_CAB 2000;
BA_REL_ "GenSigTimeoutTime" BU_SG_REL_ BCM1 SG_ 2600468569 NM_Lift_VA_SNI 2000;
BA_REL_ "GenSigTimeoutTime" BU_SG_REL_ BCM1 SG_ 2600468569 NM_Lift_VA_CBV_CRI 2000;
BA_REL_ "GenSigTimeoutTime" BU_SG_REL_ BCM1 SG_ 2600468569 NM_Lift_VA_CAB 2000;
BA_REL_ "GenSigTimeoutTime" BU_SG_REL_ BCM1 SG_ 2600468676 NM_VAS_L_SNI 2000;
BA_REL_ "GenSigTimeoutTime" BU_SG_REL_ BCM1 SG_ 2600468676 NM_VAS_L_CBV_CRI 2000;
BA_REL_ "GenSigTimeoutTime" BU_SG_REL_ BCM1 SG_ 2600468676 NM_VAS_L_CAB 2000;
BA_REL_ "GenSigTimeoutTime" BU_SG_REL_ BCM1 SG_ 2600468677 NM_VAS_R_SNI 2000;
BA_REL_ "GenSigTimeoutTime" BU_SG_REL_ BCM1 SG_ 2600468677 NM_VAS_R_CBV_CRI 2000;
BA_REL_ "GenSigTimeoutTime" BU_SG_REL_ BCM1 SG_ 2600468677 NM_VAS_R_CAB 2000;
BA_REL_ "GenSigTimeoutTime" BU_SG_REL_ Gateway SG_ 2600468494 NM_BCM1_SNI 2000;
BA_REL_ "GenSigTimeoutTime" BU_SG_REL_ Gateway SG_ 2600468494 NM_BCM1_CBV_AWB 2000;
BA_REL_ "GenSigTimeoutTime" BU_SG_REL_ Gateway SG_ 2600468494 NM_BCM1_CBV_CRI 2000;
BA_REL_ "GenSigTimeoutTime" BU_SG_REL_ Gateway SG_ 2600468494 NM_BCM1_Car_Wakeup 2000;
BA_REL_ "GenSigTimeoutTime" BU_SG_REL_ Gateway SG_ 2600468494 NM_BCM1_CAB 2000;
BA_REL_ "GenSigTimeoutTime" BU_SG_REL_ Gateway SG_ 2600468496 NM_Gateway_SNI 2000;
BA_REL_ "GenSigTimeoutTime" BU_SG_REL_ Gateway SG_ 2600468496 NM_Gateway_CBV_CRI 2000;
BA_REL_ "GenSigTimeoutTime" BU_SG_REL_ Gateway SG_ 2600468496 NM_Gateway_CAB 2000;
BA_REL_ "GenSigTimeoutTime" BU_SG_REL_ Gateway SG_ 2600468550 NM_Klima_SNI 2000;
BA_REL_ "GenSigTimeoutTime" BU_SG_REL_ Gateway SG_ 2600468550 NM_Klima_CBV_AWB 2000;
BA_REL_ "GenSigTimeoutTime" BU_SG_REL_ Gateway SG_ 2600468550 NM_Klima_CBV_CRI 2000;
BA_REL_ "GenSigTimeoutTime" BU_SG_REL_ Gateway SG_ 2600468550 NM_Klima_Car_Wakeup 2000;
BA_REL_ "GenSigTimeoutTime" BU_SG_REL_ Gateway SG_ 2600468550 NM_Klima_CAB 2000;
BA_REL_ "GenSigTimeoutTime" BU_SG_REL_ Gateway SG_ 2600468569 NM_Lift_VA_SNI 2000;
BA_REL_ "GenSigTimeoutTime" BU_SG_REL_ Gateway SG_ 2600468569 NM_Lift_VA_CBV_CRI 2000;
BA_REL_ "GenSigTimeoutTime" BU_SG_REL_ Gateway SG_ 2600468569 NM_Lift_VA_CAB 2000;
BA_REL_ "GenSigTimeoutTime" BU_SG_REL_ Gateway SG_ 2600468676 NM_VAS_L_SNI 2000;
BA_REL_ "GenSigTimeoutTime" BU_SG_REL_ Gateway SG_ 2600468676 NM_VAS_L_CBV_AWB 2000;
BA_REL_ "GenSigTimeoutTime" BU_SG_REL_ Gateway SG_ 2600468676 NM_VAS_L_CBV_CRI 2000;
BA_REL_ "GenSigTimeoutTime" BU_SG_REL_ Gateway SG_ 2600468676 NM_VAS_L_Car_Wakeup 2000;
BA_REL_ "GenSigTimeoutTime" BU_SG_REL_ Gateway SG_ 2600468676 NM_VAS_L_CAB 2000;
BA_REL_ "GenSigTimeoutTime" BU_SG_REL_ Gateway SG_ 2600468677 NM_VAS_R_SNI 2000;
BA_REL_ "GenSigTimeoutTime" BU_SG_REL_ Gateway SG_ 2600468677 NM_VAS_R_CBV_AWB 2000;
BA_REL_ "GenSigTimeoutTime" BU_SG_REL_ Gateway SG_ 2600468677 NM_VAS_R_CBV_CRI 2000;
BA_REL_ "GenSigTimeoutTime" BU_SG_REL_ Gateway SG_ 2600468677 NM_VAS_R_Car_Wakeup 2000;
BA_REL_ "GenSigTimeoutTime" BU_SG_REL_ Gateway SG_ 2600468677 NM_VAS_R_CAB 2000;
BA_REL_ "GenSigTimeoutTime" BU_SG_REL_ Klima_MSB SG_ 958 MO_StartStopp_Status 1000;
BA_REL_ "GenSigTimeoutTime" BU_SG_REL_ Klima_MSB SG_ 958 MO_StartStopp_Wiederstart 1000;
BA_REL_ "GenSigTimeoutTime" BU_SG_REL_ Klima_MSB SG_ 958 MO_StartStopp_Motorstopp 1000;
BA_REL_ "GenSigTimeoutTime" BU_SG_REL_ Klima_MSB SG_ 958 MO_Kl_75 1000;
BA_REL_ "GenSigTimeoutTime" BU_SG_REL_ Klima_MSB SG_ 958 MO_Gangposition 1000;
BA_REL_ "GenSigTimeoutTime" BU_SG_REL_ Klima_MSB SG_ 958 MO_StartStopp_Fahrerwunsch 1000;
BA_REL_ "GenSigTimeoutTime" BU_SG_REL_ Klima_MSB SG_ 958 MO_HYB_Fahrbereitschaft 1000;
BA_REL_ "GenSigTimeoutTime" BU_SG_REL_ Klima_MSB SG_ 958 MO_Ext_E_Fahrt_aktiv 1000;
BA_REL_ "GenSigTimeoutTime" BU_SG_REL_ Klima_MSB SG_ 958 MO_Klima_Eingr 1000;
BA_REL_ "GenSigTimeoutTime" BU_SG_REL_ Klima_MSB SG_ 958 MO_Motor_laeuft 1000;
BA_REL_ "GenSigTimeoutTime" BU_SG_REL_ Klima_MSB SG_ 958 MO_Kickdown 1000;
BA_REL_ "GenSigTimeoutTime" BU_SG_REL_ Klima_MSB SG_ 958 MO_FMAus_aktiv 1000;
BA_REL_ "GenSigTimeoutTime" BU_SG_REL_ Klima_MSB SG_ 958 MO_HYB_VM_aktiv 1000;
BA_REL_ "GenSigTimeoutTime" BU_SG_REL_ Klima_MSB SG_ 1648 MO_Abstellzeit 5000;
BA_REL_ "GenSigTimeoutTime" BU_SG_REL_ Klima_MSB SG_ 1648 MO_Abstellzeit_Status 5000;
BA_REL_ "GenSigTimeoutTime" BU_SG_REL_ Klima_MSB SG_ 1423 MO_ITM_Status 3200;
BA_REL_ "GenSigTimeoutTime" BU_SG_REL_ Klima_MSB SG_ 967 MO_Kuehlerluefter_MUX 800;
BA_REL_ "GenSigTimeoutTime" BU_SG_REL_ Klima_MSB SG_ 967 MO_Kuehlerluefter_1 800;
BA_REL_ "GenSigTimeoutTime" BU_SG_REL_ Klima_MSB SG_ 967 MO_Kuehlerluefter_2 800;
BA_REL_ "GenSigTimeoutTime" BU_SG_REL_ Klima_MSB SG_ 340 MO_Drehzahl_VM 2000;
BA_REL_ "GenSigTimeoutTime" BU_SG_REL_ Klima_MSB SG_ 1601 MO_Code 5000;
BA_REL_ "GenSigTimeoutTime" BU_SG_REL_ Klima_MSB SG_ 1601 MO_Getriebe_Code 5000;
BA_REL_ "GenSigTimeoutTime" BU_SG_REL_ Klima_MSB SG_ 394 MO_Start_Art 2000;
BA_REL_ "GenSigTimeoutTime" BU_SG_REL_ Klima_MSB SG_ 1156 ND_Heading 5000;
BA_REL_ "GenSigTimeoutTime" BU_SG_REL_ Klima_MSB SG_ 1157 NP_Altitude 5000;
BA_REL_ "GenSigTimeoutTime" BU_SG_REL_ Klima_MSB SG_ 2527679512 ND_Timezone_Offset 5000;
BA_REL_ "GenSigTimeoutTime" BU_SG_REL_ Klima_MSB SG_ 2527679512 ND_Timezone_DaylightSavingOffset 5000;
BA_REL_ "GenSigTimeoutTime" BU_SG_REL_ Klima_MSB SG_ 2527679512 ND_Timezone_SignBit 5000;
BA_REL_ "GenSigTimeoutTime" BU_SG_REL_ Klima_MSB SG_ 2527679512 ND_Timezone_Validity 5000;
BA_REL_ "GenSigTimeoutTime" BU_SG_REL_ Klima_MSB SG_ 1158 NP_LatDegree 5000;
BA_REL_ "GenSigTimeoutTime" BU_SG_REL_ Klima_MSB SG_ 1158 NP_LongDegree 5000;
BA_REL_ "GenSigTimeoutTime" BU_SG_REL_ Klima_MSB SG_ 1158 NP_LatDirection 5000;
BA_REL_ "GenSigTimeoutTime" BU_SG_REL_ Klima_MSB SG_ 1158 NP_LongDirection 5000;
BA_REL_ "GenSigTimeoutTime" BU_SG_REL_ Klima_MSB SG_ 2589283496 POS_MUX 5000;
BA_REL_ "GenSigTimeoutTime" BU_SG_REL_ Klima_MSB SG_ 2589283496 POS_PosStati 5000;
BA_REL_ "GenSigTimeoutTime" BU_SG_REL_ Klima_MSB SG_ 2589283496 POS_Heading 5000;
BA_REL_ "GenSigTimeoutTime" BU_SG_REL_ Klima_MSB SG_ 2589283496 POS_LatDirection 5000;
BA_REL_ "GenSigTimeoutTime" BU_SG_REL_ Klima_MSB SG_ 2589283496 POS_LatDegree 5000;
BA_REL_ "GenSigTimeoutTime" BU_SG_REL_ Klima_MSB SG_ 2589283496 POS_Heading_Trust 5000;
BA_REL_ "GenSigTimeoutTime" BU_SG_REL_ Klima_MSB SG_ 2589283496 POS_UTC_REF 5000;
BA_REL_ "GenSigTimeoutTime" BU_SG_REL_ Klima_MSB SG_ 2589283496 POS_LongDirection 5000;
BA_REL_ "GenSigTimeoutTime" BU_SG_REL_ Klima_MSB SG_ 2589283496 POS_LongDegree 5000;
BA_REL_ "GenSigTimeoutTime" BU_SG_REL_ Klima_MSB SG_ 2600468494 NM_BCM1_SNI 2000;
BA_REL_ "GenSigTimeoutTime" BU_SG_REL_ Klima_MSB SG_ 2600468494 NM_BCM1_CBV_CRI 2000;
BA_REL_ "GenSigTimeoutTime" BU_SG_REL_ Klima_MSB SG_ 2600468494 NM_BCM1_CAB 2000;
BA_REL_ "GenSigTimeoutTime" BU_SG_REL_ Klima_MSB SG_ 2600468496 NM_Gateway_SNI 2000;
BA_REL_ "GenSigTimeoutTime" BU_SG_REL_ Klima_MSB SG_ 2600468496 NM_Gateway_CBV_CRI 2000;
BA_REL_ "GenSigTimeoutTime" BU_SG_REL_ Klima_MSB SG_ 2600468496 NM_Gateway_CAB 2000;
BA_REL_ "GenSigTimeoutTime" BU_SG_REL_ Klima_MSB SG_ 2600468550 NM_Klima_SNI 2000;
BA_REL_ "GenSigTimeoutTime" BU_SG_REL_ Klima_MSB SG_ 2600468550 NM_Klima_CBV_CRI 2000;
BA_REL_ "GenSigTimeoutTime" BU_SG_REL_ Klima_MSB SG_ 2600468550 NM_Klima_CAB 2000;
BA_REL_ "GenSigTimeoutTime" BU_SG_REL_ Klima_MSB SG_ 2600468569 NM_Lift_VA_SNI 2000;
BA_REL_ "GenSigTimeoutTime" BU_SG_REL_ Klima_MSB SG_ 2600468569 NM_Lift_VA_CBV_CRI 2000;
BA_REL_ "GenSigTimeoutTime" BU_SG_REL_ Klima_MSB SG_ 2600468569 NM_Lift_VA_CAB 2000;
BA_REL_ "GenSigTimeoutTime" BU_SG_REL_ Klima_MSB SG_ 2600468676 NM_VAS_L_SNI 2000;
BA_REL_ "GenSigTimeoutTime" BU_SG_REL_ Klima_MSB SG_ 2600468676 NM_VAS_L_CBV_CRI 2000;
BA_REL_ "GenSigTimeoutTime" BU_SG_REL_ Klima_MSB SG_ 2600468676 NM_VAS_L_CAB 2000;
BA_REL_ "GenSigTimeoutTime" BU_SG_REL_ Klima_MSB SG_ 2600468677 NM_VAS_R_SNI 2000;
BA_REL_ "GenSigTimeoutTime" BU_SG_REL_ Klima_MSB SG_ 2600468677 NM_VAS_R_CBV_CRI 2000;
BA_REL_ "GenSigTimeoutTime" BU_SG_REL_ Klima_MSB SG_ 2600468677 NM_VAS_R_CAB 2000;
BA_REL_ "GenSigTimeoutTime" BU_SG_REL_ Lift_VA SG_ 958 MO_StartStopp_Status 1000;
BA_REL_ "GenSigTimeoutTime" BU_SG_REL_ Lift_VA SG_ 958 MO_StartStopp_Wiederstart 1000;
BA_REL_ "GenSigTimeoutTime" BU_SG_REL_ Lift_VA SG_ 958 MO_StartStopp_Motorstopp 1000;
BA_REL_ "GenSigTimeoutTime" BU_SG_REL_ Lift_VA SG_ 958 MO_Kl_50 1000;
BA_REL_ "GenSigTimeoutTime" BU_SG_REL_ Lift_VA SG_ 958 MO_StartStopp_Fahrerwunsch 1000;
BA_REL_ "GenSigTimeoutTime" BU_SG_REL_ Lift_VA SG_ 958 MO_Motor_laeuft 1000;
BA_REL_ "GenSigTimeoutTime" BU_SG_REL_ Lift_VA SG_ 1601 MO_StartStopp_Codiert 5000;
BA_REL_ "GenSigTimeoutTime" BU_SG_REL_ Lift_VA SG_ 2600468494 NM_BCM1_SNI 2000;
BA_REL_ "GenSigTimeoutTime" BU_SG_REL_ Lift_VA SG_ 2600468494 NM_BCM1_CBV_CRI 2000;
BA_REL_ "GenSigTimeoutTime" BU_SG_REL_ Lift_VA SG_ 2600468494 NM_BCM1_CAB 2000;
BA_REL_ "GenSigTimeoutTime" BU_SG_REL_ Lift_VA SG_ 2600468496 NM_Gateway_SNI 2000;
BA_REL_ "GenSigTimeoutTime" BU_SG_REL_ Lift_VA SG_ 2600468496 NM_Gateway_CBV_CRI 2000;
BA_REL_ "GenSigTimeoutTime" BU_SG_REL_ Lift_VA SG_ 2600468496 NM_Gateway_CAB 2000;
BA_REL_ "GenSigTimeoutTime" BU_SG_REL_ Lift_VA SG_ 2600468550 NM_Klima_SNI 2000;
BA_REL_ "GenSigTimeoutTime" BU_SG_REL_ Lift_VA SG_ 2600468550 NM_Klima_CBV_CRI 2000;
BA_REL_ "GenSigTimeoutTime" BU_SG_REL_ Lift_VA SG_ 2600468550 NM_Klima_CAB 2000;
BA_REL_ "GenSigTimeoutTime" BU_SG_REL_ Lift_VA SG_ 2600468569 NM_Lift_VA_SNI 2000;
BA_REL_ "GenSigTimeoutTime" BU_SG_REL_ Lift_VA SG_ 2600468569 NM_Lift_VA_CBV_CRI 2000;
BA_REL_ "GenSigTimeoutTime" BU_SG_REL_ Lift_VA SG_ 2600468569 NM_Lift_VA_CAB 2000;
BA_REL_ "GenSigTimeoutTime" BU_SG_REL_ Lift_VA SG_ 2600468676 NM_VAS_L_SNI 2000;
BA_REL_ "GenSigTimeoutTime" BU_SG_REL_ Lift_VA SG_ 2600468676 NM_VAS_L_CBV_CRI 2000;
BA_REL_ "GenSigTimeoutTime" BU_SG_REL_ Lift_VA SG_ 2600468676 NM_VAS_L_CAB 2000;
BA_REL_ "GenSigTimeoutTime" BU_SG_REL_ Lift_VA SG_ 2600468677 NM_VAS_R_SNI 2000;
BA_REL_ "GenSigTimeoutTime" BU_SG_REL_ Lift_VA SG_ 2600468677 NM_VAS_R_CBV_CRI 2000;
BA_REL_ "GenSigTimeoutTime" BU_SG_REL_ Lift_VA SG_ 2600468677 NM_VAS_R_CAB 2000;
BA_REL_ "GenSigTimeoutTime" BU_SG_REL_ VAS_L SG_ 958 MO_Kl_75 1000;
BA_REL_ "GenSigTimeoutTime" BU_SG_REL_ VAS_L SG_ 958 MO_Gangposition 1000;
BA_REL_ "GenSigTimeoutTime" BU_SG_REL_ VAS_L SG_ 2600468494 NM_BCM1_SNI 2000;
BA_REL_ "GenSigTimeoutTime" BU_SG_REL_ VAS_L SG_ 2600468494 NM_BCM1_CBV_CRI 2000;
BA_REL_ "GenSigTimeoutTime" BU_SG_REL_ VAS_L SG_ 2600468494 NM_BCM1_CAB 2000;
BA_REL_ "GenSigTimeoutTime" BU_SG_REL_ VAS_L SG_ 2600468496 NM_Gateway_SNI 2000;
BA_REL_ "GenSigTimeoutTime" BU_SG_REL_ VAS_L SG_ 2600468496 NM_Gateway_CBV_CRI 2000;
BA_REL_ "GenSigTimeoutTime" BU_SG_REL_ VAS_L SG_ 2600468496 NM_Gateway_CAB 2000;
BA_REL_ "GenSigTimeoutTime" BU_SG_REL_ VAS_L SG_ 2600468550 NM_Klima_SNI 2000;
BA_REL_ "GenSigTimeoutTime" BU_SG_REL_ VAS_L SG_ 2600468550 NM_Klima_CBV_CRI 2000;
BA_REL_ "GenSigTimeoutTime" BU_SG_REL_ VAS_L SG_ 2600468550 NM_Klima_CAB 2000;
BA_REL_ "GenSigTimeoutTime" BU_SG_REL_ VAS_L SG_ 2600468569 NM_Lift_VA_SNI 2000;
BA_REL_ "GenSigTimeoutTime" BU_SG_REL_ VAS_L SG_ 2600468569 NM_Lift_VA_CBV_CRI 2000;
BA_REL_ "GenSigTimeoutTime" BU_SG_REL_ VAS_L SG_ 2600468569 NM_Lift_VA_CAB 2000;
BA_REL_ "GenSigTimeoutTime" BU_SG_REL_ VAS_L SG_ 2600468676 NM_VAS_L_SNI 2000;
BA_REL_ "GenSigTimeoutTime" BU_SG_REL_ VAS_L SG_ 2600468676 NM_VAS_L_CBV_CRI 2000;
BA_REL_ "GenSigTimeoutTime" BU_SG_REL_ VAS_L SG_ 2600468676 NM_VAS_L_CAB 2000;
BA_REL_ "GenSigTimeoutTime" BU_SG_REL_ VAS_L SG_ 2600468677 NM_VAS_R_SNI 2000;
BA_REL_ "GenSigTimeoutTime" BU_SG_REL_ VAS_L SG_ 2600468677 NM_VAS_R_CBV_CRI 2000;
BA_REL_ "GenSigTimeoutTime" BU_SG_REL_ VAS_L SG_ 2600468677 NM_VAS_R_CAB 2000;
BA_REL_ "GenSigTimeoutTime" BU_SG_REL_ VAS_R SG_ 958 MO_Kl_75 1000;
BA_REL_ "GenSigTimeoutTime" BU_SG_REL_ VAS_R SG_ 958 MO_Gangposition 1000;
BA_REL_ "GenSigTimeoutTime" BU_SG_REL_ VAS_R SG_ 2600468494 NM_BCM1_SNI 2000;
BA_REL_ "GenSigTimeoutTime" BU_SG_REL_ VAS_R SG_ 2600468494 NM_BCM1_CBV_CRI 2000;
BA_REL_ "GenSigTimeoutTime" BU_SG_REL_ VAS_R SG_ 2600468494 NM_BCM1_CAB 2000;
BA_REL_ "GenSigTimeoutTime" BU_SG_REL_ VAS_R SG_ 2600468496 NM_Gateway_SNI 2000;
BA_REL_ "GenSigTimeoutTime" BU_SG_REL_ VAS_R SG_ 2600468496 NM_Gateway_CBV_CRI 2000;
BA_REL_ "GenSigTimeoutTime" BU_SG_REL_ VAS_R SG_ 2600468496 NM_Gateway_CAB 2000;
BA_REL_ "GenSigTimeoutTime" BU_SG_REL_ VAS_R SG_ 2600468550 NM_Klima_SNI 2000;
BA_REL_ "GenSigTimeoutTime" BU_SG_REL_ VAS_R SG_ 2600468550 NM_Klima_CBV_CRI 2000;
BA_REL_ "GenSigTimeoutTime" BU_SG_REL_ VAS_R SG_ 2600468550 NM_Klima_CAB 2000;
BA_REL_ "GenSigTimeoutTime" BU_SG_REL_ VAS_R SG_ 2600468569 NM_Lift_VA_SNI 2000;
BA_REL_ "GenSigTimeoutTime" BU_SG_REL_ VAS_R SG_ 2600468569 NM_Lift_VA_CBV_CRI 2000;
BA_REL_ "GenSigTimeoutTime" BU_SG_REL_ VAS_R SG_ 2600468569 NM_Lift_VA_CAB 2000;
BA_REL_ "GenSigTimeoutTime" BU_SG_REL_ VAS_R SG_ 2600468676 NM_VAS_L_SNI 2000;
BA_REL_ "GenSigTimeoutTime" BU_SG_REL_ VAS_R SG_ 2600468676 NM_VAS_L_CBV_CRI 2000;
BA_REL_ "GenSigTimeoutTime" BU_SG_REL_ VAS_R SG_ 2600468676 NM_VAS_L_CAB 2000;
BA_REL_ "GenSigTimeoutTime" BU_SG_REL_ VAS_R SG_ 2600468677 NM_VAS_R_SNI 2000;
BA_REL_ "GenSigTimeoutTime" BU_SG_REL_ VAS_R SG_ 2600468677 NM_VAS_R_CBV_CRI 2000;
BA_REL_ "GenSigTimeoutTime" BU_SG_REL_ VAS_R SG_ 2600468677 NM_VAS_R_CAB 2000;
VAL_ 958 MO_StartStopp_Status 0 "System_in_diesem_KL15_Zyklus_nicht_verfuegbar" 1 "System_aktiv_keine_Freigabe_durch_StartStop_Koordinator" 2 "System_aktiv_alle_Freigaben_liegen_vor" 3 "System_aktiv_mindestens_eine_Freigabe_fehlt" ;
VAL_ 958 MO_StartStopp_Wiederstart 0 "Wiederstart_inaktiv" 1 "Wiederstart_aktiv" ;
VAL_ 958 MO_StartStopp_Motorstopp 0 "Motor_Stop_inaktiv" 1 "Motor_Stop_aktiv" ;
VAL_ 958 MO_Freig_Reku 0 "Rekuperations-Modus aus" 1 "Empfehlung Spannungsanhebung" 2 "Empfehlung Spannungsabsenkung" 3 "Rekuperationsmodus aktiv, Spannungsvariation nicht notwendig" ;
VAL_ 958 MO_Kl_75 0 "Aus" 1 "Ein" ;
VAL_ 958 MO_Kl_50 0 "aus" 1 "KL50_ein_Startausfuehrung_Fahrer" ;
VAL_ 958 MO_Gangposition 0 "Gang_N" 1 "Gang_1" 2 "Gang_2" 3 "Gang_3" 4 "Gang_4" 5 "Gang_5" 6 "Gang_6" 7 "Gang_7" 8 "Gang_8" 9 "Automat_P" 10 "Automat_Vorwaerts_S" 11 "Automat_Vorwaerts_D/E" 12 "Zwischenstellung" 13 "Gang_R" 14 "Istgang_nicht_definiert" 15 "Fehler" ;
VAL_ 958 MO_StartStopp_Fahrerwunsch 0 "Init" 1 "Stoppverbot_durch_Fahrer" 2 "Stoppfreigabe_durch_Fahrer" 3 "Stoppanforderung_durch_Fahrer" ;
VAL_ 958 MO_HYB_Fahrbereitschaft 0 "keine_Fahrbereitschaft" 1 "Fahrbereitschaft" ;
VAL_ 958 MO_Ext_E_Fahrt_aktiv 0 "Rueckmeldung_E_Taster_aus" 1 "Rueckmeldung_E_Taster_ein" ;
VAL_ 958 MO_Fahrer_bremst 0 "kein_Bremsen" 1 "Bremse_betaetigt" ;
VAL_ 958 MO_QBit_Fahrer_bremst 0 "gueltiger_Wert" 1 "Ersatz_Init_oder_Fehlerwert" ;
VAL_ 958 MO_BLS 0 "kein_Bremsen" 1 "Bremse_betaetigt" ;
VAL_ 958 MO_Konsistenz_Bremsped 0 "Bremspedalinformation_plausibel" 1 "Bremspedalinformation_unplausibel" ;
VAL_ 958 MO_KomFehler_ESP 0 "kein_Fehler" 1 "Fehler" ;
VAL_ 958 MO_Klima_Eingr 0 "kein Eingriff" 1 "Klimakompressor ausschalten" 2 "Klimakompressor Leistungsreduzierung" 3 "Klimakompressor aufgrund der Heissleuchtenvorwarnung ausschalten" ;
VAL_ 958 MO_Aussp_Anlass 0 "Anlasser_darf_angesteuert_werden" 1 "Anlasser_ausspuren__Ansteuerung_nicht_moeglich" ;
VAL_ 958 MO_Freig_Anlass 0 "Start_nicht_zulaessig" 1 "Startfreigabe" ;
VAL_ 958 MO_Kuppl_schalter 0 "Schalter_sagt_ausgekuppelt" 1 "Schalter_sagt_eingekuppelt" ;
VAL_ 958 MO_Interlock 0 "Interlockschalter_nicht_betaetigt" 1 "Interlockschalter_betaetigt" ;
VAL_ 958 MO_Motor_laeuft 0 "Motor_laeuft_nicht" 1 "Motor_laeuft_autark_und_stabil_und_darf_mechanisch_belastet_werden" ;
VAL_ 958 MO_Kickdown 0 "kein_Kickdown" 1 "Kickdown" ;
VAL_ 958 MO_QBit_KL_75 0 "gueltiger_Wert" 1 "Ersatz_Init_oder_Fehlerwert" ;
VAL_ 958 MO_EKlKomLeiRed 0 "keine_Leistungsbegr" 1 "Leistungsbegr_75" 2 "Leistungsbegr_50" 3 "Leistungsbegr_25" ;
VAL_ 958 MO_Handshake_STH 0 "keine EKP-Ansteuerung durch STH-Anforderung" 1 "EKP-Ansteuerung durch STH-Anforderung" ;
VAL_ 958 MO_BKV_Unterdruckwarnung 0 "Unterdruckhaushalt_iO" 1 "Unterdruckhaushalt_niO" ;
VAL_ 958 MO_Freigabe_Segeln 0 "Segelbetrieb_nicht_freigegeben" 1 "Segelbetrieb_freigegeben" ;
VAL_ 958 MO_PTC_Status 0 "nicht_unterstuetzt" 1 "Stufe_0" 2 "Stufe_1" 3 "Stufe_2" 4 "Stufe_3" 7 "PTC_am_BCM" ;
VAL_ 958 MO_QBit_Gangposition 0 "gueltiger_Wert" 1 "Ersatz_Init_oder_Fehlerwert" ;
VAL_ 958 MO_Signalquelle_Gangposition 0 "Sensorsignal" 1 "Modellsignal" ;
VAL_ 958 MO_Remotestart_Betrieb 0 "MSG_nicht_bereit_fuer_RS_Betrieb" 1 "MSG_bereit_fuer_oder_im_RS_Betrieb" ;
VAL_ 958 MO_Remotestart_moeglich 0 "Remotestart_nicht_moeglich" 1 "Remotestart_moeglich" ;
VAL_ 958 MO_FMAus_aktiv 0 "inaktiv" 1 "Segeln_mit_Motor_aus_aktiv" ;
VAL_ 958 MO_FMAus_Startvariante 0 "kein_Motorstart" 1 "Motorstart_elektrischer_Starter" 2 "GetriebeAnschleppstart" 3 "GetriebeNotAnschleppstart" ;
VAL_ 958 MO_BMS_NV_Anf_stuetzen 0 "nicht_notwendig" 1 "notwendig" ;
VAL_ 958 MO_Zylinderabschaltung 0 "Vollmotorbetrieb_VMB" 1 "Uebergang_HMB_in_VMB" 2 "Uebergang_VMB_in_HMB" 3 "Halbmotorbetrieb_HMB" ;
VAL_ 958 MO_HYB_VM_aktiv 0 "VM_nicht_aktiv" 1 "VM_aktiv" ;
VAL_ 958 MO_StartVorauss_erfuellt 0 "Signal_nicht_bedient" 1 "StartVorauss_nicht_ueberpruefbar" 2 "StartVorauss_nicht_erfuellt" 3 "StartVorauss_erfuellt" ;
VAL_ 1631 TSK_QBit_Steigung 0 "gueltiger_Wert" 1 "Ersatz_Init_oder_Fehlerwert" ;
VAL_ 1631 TSK_QBit_Fahrzeugmasse 0 "gueltiger_Wert" 1 "Ersatz_Init_oder_Fehlerwert" ;
VAL_ 1631 MO_SpannungsAnf_02 0 "keine_Anforderung" 1 "Anforderung_Stufe_1" 2 "Anforderung_Stufe_2" 3 "Anforderung_Stufe_3" ;
VAL_ 1631 MO_DPF_reg 0 "DPF_regeneriert_nicht" 1 "DPF_regeneriert" ;
VAL_ 1631 MO_Heizstrom_EKAT 127 "Fehler" ;
VAL_ 1631 MO_Heizstrom_SCR 63 "Fehler" ;
VAL_ 1631 MO_P_Generator_ungefiltert_Anf 0 "nicht_angefordert" 1 "angefordert" ;
VAL_ 1631 TSK_Getriebeinfo 0 "Handschalter" 1 "AL_AQ_Getriebe" 2 "DL_DQ_Getriebe" 3 "CVT_Getriebe" ;
VAL_ 1631 MO_Energieinhalt_BMS 4094 "Init" 4095 "Fehler" ;
VAL_ 1631 TSK_Fahrzeugmasse_02 255 "Fehler" ;
VAL_ 1631 TSK_Steigung_02 0 "Init_oder_nicht_verbaut" 255 "Fehler" ;
VAL_ 812 MO_Sperrung_FahrPr_BZS 0 "keine Sperrung" 1 "Sperrung BZS1" 2 "Sperrung BZS2" 4 "Sperrung BZS3" 8 "Sperrung BZS4" 16 "Sperrung BZS5" 32 "Sperrung BZS6" 64 "Sperrung BZS7" 128 "Sperrung BZS8" ;
VAL_ 812 MO_Rampenzeit_Generator_Anf 0 "0_sec" 1 "1_sec" 2 "2_sec" 3 "3_sec" 4 "4_sec" 5 "5_sec" 6 "6_sec" 7 "7_sec" 8 "8_sec" 9 "9_sec" 10 "reserviert" 11 "reserviert" 12 "reserviert" 13 "reserviert" 14 "reserviert" 15 "keine_Anforderung" ;
VAL_ 812 MO_Prio_MAX_Wunschdrehzahl 0 "Wunsch" 1 "Zwang" ;
VAL_ 812 MO_Prio_MIN_Wunschdrehzahl 0 "Wunsch" 1 "Zwang" ;
VAL_ 812 MO_Luftpfad_aktiv 0 "kein Eingriff oder nur Eingriff über Zündpfad" 1 "Eingriff über Luftpfad" ;
VAL_ 812 MO_v_Begrenz_Aktivierbar 0 "V-Begrenzung nicht möglich" 1 "V-Begrenzung möglich" ;
VAL_ 812 MO_Charisma_FahrPr 0 "keine_Funktion" 1 "Programm_1" 2 "Programm_2" 3 "Programm_3" 4 "Programm_4" 5 "Programm_5" 6 "Programm_6" 7 "Programm_7" 8 "Programm_8" 9 "Programm_9" 10 "Programm_10" 11 "Programm_11" 12 "Programm_12" 13 "Programm_13" 14 "Programm_14" 15 "Programm_15" ;
VAL_ 812 MO_Charisma_Status 0 "Init" 1 "verfuegbar" 2 "nicht_verfuegbar" 3 "asynchron_durch_Fahrerwunsch" ;
VAL_ 812 MO_StSt_Charisma_FahrPr 0 "keine_Funktion" 1 "Programm_1" 2 "Programm_2" 3 "Programm_3" 4 "Programm_4" 5 "Programm_5" 6 "Programm_6" 7 "Programm_7" 8 "Programm_8" 9 "Programm_9" 10 "Programm_10" 11 "Programm_11" 12 "Programm_12" 13 "Programm_13" 14 "Programm_14" 15 "Programm_15" ;
VAL_ 812 MO_StSt_Charisma_Status 0 "Init" 1 "verfuegbar" 2 "nicht_verfuegbar" 3 "asynchron_durch_Fahrerwunsch" ;
VAL_ 812 MO_BZS_Charisma_FahrPr 0 "keine_Funktion" 1 "Programm_1" 2 "Programm_2" 3 "Programm_3" 4 "Programm_4" 5 "Programm_5" 6 "Programm_6" 7 "Programm_7" 8 "Programm_8" 9 "Programm_9" 10 "Programm_10" 11 "Programm_11" 12 "Programm_12" 13 "Programm_13" 14 "Programm_14" 15 "Programm_15" ;
VAL_ 812 MO_BZS_Charisma_Status 0 "Init" 1 "verfuegbar" 2 "nicht_verfuegbar" 3 "asynchron_durch_Fahrerwunsch" ;
VAL_ 812 MO_NGS_Position 0 "Neutralposition_nicht_erkannt" 1 "Neutralposition_erkannt" ;
VAL_ 812 MO_NGS_Status 0 "nicht_verbaut" 1 "nicht_plausibilisiert" 2 "plausibilisiert" 3 "Fehler" ;
VAL_ 812 MO_v_Begrenzung_Niveau 0 "keine_Begrenzung_aktiv" 1 "Sicherheitsbegrenzung_1_aktiv" 2 "Sicherheitsbegrenzung_2_aktiv" 3 "Komfortbegrenzung_aktiv" ;
VAL_ 1648 MO_ANC_Kennfeld_Anf 0 "Kennfeld_1" 1 "Uebergang_Kennfeld_2_nach_1" 2 "Uebergang_Kennfeld_1_nach_2" 3 "Kennfeld_2" ;
VAL_ 1648 MO_Bremslicht_Reku 0 "Aus" 1 "Ein" ;
VAL_ 1648 MO_StartStopp_PopUp 0 "Statuswechsel_ohne_Taster (Init)" 1 "StSt_per_Taster_deaktiviert" 2 "StSt_per_Taster_aktiviert" 3 "nicht verwendet" ;
VAL_ 1648 MO1_Sperr_Info_WFS 0 "nicht_gesperrt" 1 "gesperrt" ;
VAL_ 1648 MO1_Freigabe_Info_WFS 0 "ungueltig" 1 "gueltig" ;
VAL_ 1648 MO_EPCL 0 "EPCL_aus_kein_Text" 1 "EPCL_gelb_Stoerung" 2 "EPCL_gelb_Leistungsbeschraenkung" 3 "EPCL_rot_Fzg_sicher_abstellen" ;
VAL_ 1648 MO_Zylabsch_Texte_02 0 "ein_ZAS_generell_keine_ZAS_Anzeigen" 1 "ZAS_im_VMB" 2 "ZAS_im_ASB_1_Zyl_aktiv" 3 "ZAS_im_ASB_2_Zyl_aktiv" 4 "ZAS_im_ASB_3_Zyl_aktiv" 5 "ZAS_im_ASB_4_Zyl_aktiv" 6 "ZAS_im_ASB_5_Zyl_aktiv" 7 "ZAS_im_ASB_6_Zyl_aktiv" 8 "ZAS_im_ASB_8_Zyl_aktiv" 9 "ZAS_im_ASB_12_Zyl_aktiv" 13 "Uebergangsbetrieb" 14 "keine_ZAS_Anzeige_ggf_Stopp_Schub_Betrieb" 15 "ZAS_Stoerungs_Anzeige" ;
VAL_ 1648 MO_Fahrzeugtyp 0 "Verbrenner_Fahrzeug" 1 "Hybrid" 2 "E_Fahrzeug" 3 "E_Fahrzeug_mit_Range_Extender" 4 "Brennstoffzellenfahrzeug" 5 "tbd" 6 "tbd" 7 "tbd" ;
VAL_ 1648 MO_Abstellzeit 254 "Init" 255 "reserviert" ;
VAL_ 1648 MO_Abstellzeit_Status 0 "Abstellzeit_nicht_berechnet" 1 "Abstellzeit_berechnet" 2 "Abstellzeit_Minimalwert" 3 "Abstellzeit_ungueltig" ;
VAL_ 1648 MO1_Freigabe_Verfallsinfo_WFS 0 "verfaellt_nicht" 1 "verfaellt" ;
VAL_ 1648 MO_Hybrid_StartStopp_LED 0 "LED_aus_und_Blinken_aus" 1 "LED_ein_und_Blinken_aus" 2 "LED_ein_und_Blinken_ein_50_percent" 3 "reserviert" ;
VAL_ 1648 MO_Fehler_Zylabsch 0 "kein_Fehler" 1 "Notlauf_Vollmotorbetrieb" 2 "Notlauf_mindestens_einem_abgesch_Zylinder" ;
VAL_ 1648 MO_Anzahl_Abgesch_Zyl 0 "Vollmotorbetrieb" 1 "1_Zylinder_abgeschaltet" 2 "2_Zylinder_abgeschaltet" 3 "3_Zylinder_abgeschaltet" 4 "4_Zylinder_abgeschaltet" 5 "5_Zylinder_abgeschaltet" 6 "6_Zylinder_abgeschaltet" 7 "8_Zylinder_abgeschaltet" ;
VAL_ 1648 MO_Zylabsch_Texte 0 "keine_Texte" 1 "Zylinderabschaltung_deaktivieren" 2 "Zylinderabschaltung_aktivieren" 3 "Zylinderabschaltung_unruhig" ;
VAL_ 1648 MO_Ethanol_BS_Texte 0 "kein_Text" 1 "E85_Warm_Up" 2 "FlexFuel_Warnung_Stufe_3" 3 "Warmfahrempfehlung_MQB__FlexFuel_Warnung_Stufe_1" 4 "FlexFuel_Warnung_Stufe_2" 5 "FlexFuel_Warnung_Stufe_4" 6 "E25_Warm_Up" ;
VAL_ 1648 MO_Drehzahl_Warnung 0 "keinen_Warnhinweis_anzeigen" 1 "Warnhinweis_anzeigen" ;
VAL_ 1648 MO_obere_Drehzahlgrenze 0 "Init" ;
VAL_ 289 MO_Fahrpedalrohwert_01 255 "Fehler" ;
VAL_ 289 MO_QBit_Fahrpedalwerte_01 0 "gueltiger_Wert" 1 "Ersatz_Init_oder_Fehlerwert" ;
VAL_ 289 MO_Fahrpedalgradient 255 "Fehler" ;
VAL_ 289 MO_Sig_Fahrpedalgradient 0 "Fahrpedalgradient positiv" 1 "Fahrpedalgradient negativ" ;
VAL_ 289 MO_rel_Saugrohrdruck 0 "Init_Ueberdruck" 63 "Fehler" ;
VAL_ 289 MO_rel_Saugrohrdruck_gem_err 0 "errechnet" 1 "gemessen" ;
VAL_ 289 MO_Moment_im_Leerlauf 0 "kein_Leergas" 1 "Leergas" ;
VAL_ 289 MO_Schubabschaltung 0 "keine_Schubabschaltung" 1 "Schubabschaltung_aktiv" ;
VAL_ 289 MO_StartStopp_StoppVorbereitung 0 "Motorstopp_nicht_in_Vorbereitung" 1 "Motorstopp_in_Vorbereitung" ;
VAL_ 289 MO_Entkopplung_Sollschlupf 125 "Notoeffnen_Anfahrelement" 126 "Init" ;
VAL_ 289 MO_temporaere_Fahrerabwesenheit 0 "nicht_erkannt" 1 "erkannt" ;
VAL_ 289 TSK_a_Soll_gradientenbegrenzt 127 "Init_oder_nicht_aktiv" ;
VAL_ 1423 MO_ITM_Status 0 "stehendes_Wasser" 1 "kein_stehendes_Wasser" 2 "Entnahmegrenze_20_Grad_Celsius" 3 "Entnahmegrenze_30_Grad_Celsius" 4 "Entnahmegrenze_40_Grad_Celsius" 5 "Entnahmegrenze_50_Grad_Celsius" 6 "Entnahmegrenze_60_Grad_Celsius" 7 "keine_Entahme_erlaubt" 14 "Init" 15 "Fehler" ;
VAL_ 1423 MO_Tankdruck 254 "Init" 255 "Fehler" ;
VAL_ 1423 MO_Kuehlmittel_Temp_Rohwert 254 "Init" 255 "Fehler" ;
VAL_ 1423 MO_Oel_Temp_Radsatz 254 "Initialwert" 255 "Fehler" ;
VAL_ 1423 MO_KJS_LLK_Pos_Summe 14 "Init" 15 "Pos_Frontendverschl_ungenau" ;
VAL_ 967 MO_Kuehlerluefter_MUX 0 "Kuehlerluefter_1" 1 "Kuehlerluefter_2" ;
VAL_ 967 MO_Kuehlerluefter_1 126 "Init" 127 "Fehler" ;
VAL_ 967 MO_Kuehlerluefter_2 126 "Init" 127 "Fehler" ;
VAL_ 967 MO_EFLEX_Lampe 0 "Lampe_aus" 1 "Lampe_ein" 2 "Lampe_blinkend" 3 "Lampe_blinkend_mit_Akustik" ;
VAL_ 967 MO_KJS_nicht_bereit 0 "kein_Fehler" 1 "Fehler" ;
VAL_ 967 MO_ITM_Warnung_Pumpe 0 "keine_Warnung" 1 "ITM_Warnung" ;
VAL_ 967 WIV_Anzeige_aktiv 0 "Anzeige aus" 1 "WIV Anzeige aktiv" ;
VAL_ 967 WIV_Oelmin_Warn 0 "in_Ordnung" 1 "Warnung" ;
VAL_ 967 WIV_Sensorfehler 0 "in_Ordnung" 1 "Sensor_defekt" ;
VAL_ 967 WIV_Schieflage 0 "Fahrzeug_gerade" 1 "Fahrzeug_in_Schieflage" ;
VAL_ 967 MO_Zustand_HWP 0 "HWP_nicht_schaltbar" 1 "HWP_foerdert_nicht" 2 "HWP_foerdert" 3 "reserviert" ;
VAL_ 967 OLEV_Systemstoerung 0 "Ölsystem i.O." 1 "Systemstörung Ölsystem" ;
VAL_ 967 MO_Oelwarnung_max 0 "keine_Warnung" 1 "Warnfall_aktiv" ;
VAL_ 967 WIV_Oelsystem_aktiv 0 "Anzeige_aus" 1 "Anzeige_aktiv" ;
VAL_ 967 WIV_nicht_betriebswarm 0 "Motor_warm" 1 "Motor_nicht_betriebswarm" ;
VAL_ 967 WIV_Ueberfuell_Warn 0 "in_Ordnung" 1 "Ueberfuellwarnung" ;
VAL_ 967 WIV_laufender_Motor 0 "Messung_moeglich" 1 "Messung_nicht_moeglich" ;
VAL_ 967 MO_E_Warnungen 0 "keine_Anzeige" 1 "Fehler_Elektrosystem_Anhalten" 2 "Fehler_Elektrosystem_Werkstatt" 3 "Elektrosystem_ueberhitzt_Stopp" 4 "Fehler_Hybridsystem_Anhalten" 5 "Fehler_Hybridsystem_Werkstatt" 6 "Fehler_Wasserstoffsystem_Anhalte" 7 "Fehler_Wasserstoffsystem_Werksta" 8 "reserviert_keine_Anzeige" 9 "reserviert_keine_Anzeige" 10 "reserviert_keine_Anzeige" 11 "reserviert_keine_Anzeige" 12 "reserviert_keine_Anzeige" 13 "reserviert_keine_Anzeige" 14 "reserviert_keine_Anzeige" 15 "reserviert_keine_Anzeige" ;
VAL_ 967 MO_Text_Motorstart 0 "keine_Anzeige" 1 "Motor_im_Stoppbetrieb" 2 "StartStopp_sicherheitsbedingt_deaktiviert" 3 "System_fordert_Wiederstart" 4 "Aufforderung_Motorstart" 5 "Motorlauf_noetig" 6 "Motorlaufwarnung" 9 "Unerwuenschter_Motorstillstand" 11 "Fehler_Kupplungsschalter" 12 "Motor_startet" 13 "Kupplung_betaetigen" 14 "Waehlhebel_in_PN_Position" 15 "Bremse_treten" ;
VAL_ 967 MO_E_Texte 0 "keine_Anzeige" 1 "Batterie_fast_leer" 2 "Ladestecker_nicht_fahrbereit" 3 "VM_Betrieb_erforderlich" 4 "Batterie_laedt_Nicht_ausschalten" 5 "Bitte_Bremse_treten" 6 "manueller_Neustart_erforderlich" 7 "Stopp_Fahrzeug_nicht_abschleppen" 8 "kein_Neustart_Haube_nicht_oeffnen" 9 "Motorstart_im_naechsten_Zyklus" 10 "VM_erforderlich_EVMode_abwaehlen" 11 "laengerer_VMBetrieb_Bordbuch" 12 "Tank_leer_VM_nicht_verfuegbar" 13 "Bitte_warten_Motor_startet" 14 "kein_Start_Batterietemperatur" 15 "Ende_elektrische_Reichweite_erreicht" ;
VAL_ 967 WIV_Oeldyn_avl 0 "Oeldyn_nicht_vorhanden" 1 "Oeldyn_vorhanden" ;
VAL_ 967 OLEV_Oelstand_nicht_vorhanden 0 "Ölstand vorhanden" 1 "Ölstand nicht vorhanden" ;
VAL_ 967 MO_Systemlampe 0 "Lampe aus" 1 "Lampe ein" ;
VAL_ 967 MO_OBD2_Lampe 0 "Lampe aus" 1 "Lampe ein" ;
VAL_ 967 MO_Heissleuchte 0 "Lampe aus" 1 "Lampe ein" ;
VAL_ 967 MO_Partikel_Lampe 0 "Lampe aus" 1 "Lampe ein" ;
VAL_ 967 MO_RedFahrleistung_Lampe 0 "Lampe_aus" 1 "Lampe_ein" ;
VAL_ 967 WIV_Oelstand_nicht_vorhanden 0 "Ölstand vorhanden" 1 "Ölstand nicht vorhanden" ;
VAL_ 967 WIV_nachfuellanzeige_ein 0 "keine_Nachfuellanzeige" 1 "Nachfuellanzeige" ;
VAL_ 967 WIV_Ueberfuell_deaktiv 0 "Ueberfuellwarnung_am_Kombi_aktiv" 1 "Ueberfuellwarnung_am_Kombi_deaktiv" ;
VAL_ 967 WIV_Unterfuell_Warn 0 "in_Ordnung" 1 "Unterfuellwarnung" ;
VAL_ 967 MO_Tankdeckel_Lampe 0 "Lampe aus" 1 "Lampe ein" ;
VAL_ 967 MO_Text_Tankdeckelwarn 0 "kein_Text" 1 "Anzeige_Text_Tankdeckelwarnung_im_Kombi" ;
VAL_ 967 MO_Vorglueh_Lampe 0 "Lampe_aus" 1 "Lampe_ein" ;
VAL_ 967 WIV_Oeldr_Warn_Motor 0 "keine_Warnung" 1 "niedrige_Oeldruckstufe_nicht_erreicht" ;
VAL_ 967 MO_E_Mode 0 "keine_Anzeige" 1 "E_Mode_passiv" 2 "E_Mode_aktiv" 3 "E_Mode_inaktiv_nicht_verfuegbar" 4 "E_Mode_aktiv_nicht_verfuegbar" 5 "reserviert_keine_Anzeige" 6 "reserviert_keine_Anzeige" 7 "reserviert_keine_Anzeige" ;
VAL_ 340 MO_IstMoment_VKM 1022 "Init" ;
VAL_ 340 MO_Mom_Begr_Schalt 1022 "Init" ;
VAL_ 340 MO_Mom_Begr_Schalt_Min 1022 "Init" ;
VAL_ 340 MO_Fehlerstatus_Antrieb_FDR 0 "FDR_Normalbetrieb" 1 "FDR_abschalten" 2 "FDR_Regelung_beenden" 3 "FDR_abschalten_temporaer" 4 "FDR_Regelung_temporaer_beenden" ;
VAL_ 340 MO_Primaerachse_Anforderung 0 "Init_Freilaufsteuerung_MSG" 1 "Anforderung_Abkoppeln" 2 "Anforderung_Ankoppeln" ;
VAL_ 283 MO_Fahrbereitschaft 0 "Fahrzykl_inaktiv__kein_Antrieb" 1 "Fahrzykl_aktiv__kein_Antrieb" 2 "Fahrzykl_aktiv__Antrieb_moeglich" ;
VAL_ 283 MO_Freilauf_Info 0 "Freilauf_freigegeben" 1 "Uebergang_in_Freilauf_unzulaessig" 2 "Freilauf_nicht_freigegeben_Abbruch" 3 "Freilauf_Anforderung" ;
VAL_ 283 MO_Krit_Heckobjekt 0 "Init_kein_relevantes_Objekt" 1 "Entfernung_grosser_Abstand" 2 "Annaeherung_grosser_Abstand" 3 "Entfernung_geringer_Abstand" 4 "Annaeherung_geringer_Abstand" 7 "Fehler" ;
VAL_ 283 MO_NGS_Gangpos 0 "nicht_bedient" 1 "1_3_oder_5" 2 "2_4_6_oder_R" 3 "R" 4 "Neutralposition" 5 "Zwischenposition" 6 "Sensor_temp_nicht_verfuegbar" 7 "Fehler" ;
VAL_ 283 MO_Freilauf_Status 0 "Freilauf_inaktiv_aber_moeglich" 1 "Freilauf_aktiv" 2 "Freilauf_nicht_moegl_1Verhinderer" 3 "Freilauf_nicht_moegl_gr_1Verhinderer" 7 "Fehler" ;
VAL_ 283 MO_EBoost_verf_praed 0 "Init_oder_nicht_verfuegbar" 1 "EBoost_kurzzeit_verfuegbar" 2 "EBoost_langzeit_verfuegbar" ;
VAL_ 283 MO_Heckspoiler_Anf 0 "nicht_angefordert" 1 "angefordert" ;
VAL_ 283 MO_eLaunch_verf 0 "Init" 1 "nicht_verfuegbar" 2 "verfuegbar" ;
VAL_ 283 MO_Positionierung_aktiv 0 "keine_Positionierung_aktiv" 1 "Positionierung_aktiv" ;
VAL_ 283 MO_Parken_WFS_Status 0 "Limitierung_Inaktiv" 1 "Limitierung_Aktiv" 2 "Abbruch" ;
VAL_ 1601 MO_Faktor_Momente_02 0 "nicht_belegt" ;
VAL_ 1601 MO_Hybridfahrzeug 0 "kein_Hybridfahrzeug" 1 "Mild_Hybrid" 2 "Full_Hybrid" 3 "PlugIn_Hybrid" ;
VAL_ 1601 MO_Getriebe_Code 0 "Init" 2 "DL501" 3 "DL800" 4 "VL381" 5 "DL382_Front" 6 "DL382_Allrad" 7 "DL702" 8 "AL552_Allrad" 9 "AL552_Front" 10 "AL651" 11 "AL551__AL951__AL1000_8A" 12 "PDK_PAG" 13 "AL551_Hybrid" 15 "Handschalter_konventionell" 16 "AQ250_160" 17 "AQ450" 18 "DQ200" 19 "DQ250" 20 "DQ500" 21 "SQ100" 22 "SQ200" 23 "DQ400E" 24 "DQ381" 25 "AL550" 26 "AQ300" 31 "DL800E" 32 "Single_Gear__ohne_GSG_WH_am_MSG" ;
VAL_ 1601 MO_StartStopp_Codiert 0 "Start_Stopp_nicht_verbaut" 1 "Start_Stopp_verbaut" ;
VAL_ 1601 MO_Anzeige_StSt_gueltig 0 "MO_Text_Motorstart_gueltig" 1 "Signale_MO_Anzeige_StSt_gueltig" ;
VAL_ 1601 MO_Anzahl_Zyl 0 "kein_Zylinder" 1 "1_Zylinder" 2 "2_Zylinder" 3 "3_Zylinder" 4 "4_Zylinder" 5 "5_Zylinder" 6 "6_Zylinder" 7 "7_Zylinder" 8 "8_Zylinder" 9 "9_Zylinder" 10 "10_Zylinder" 11 "11_Zylinder" 12 "12_Zylinder" 13 "15_Zylinder" 14 "16_Zylinder" 15 "18_Zylinder" ;
VAL_ 1601 MO_Kraftstoffart 0 "Diesel" 1 "Benzin_inkl_E25_E85" 2 "CNG" 3 "LPG" 4 "Wasserstoff" 5 "E100_Ethanol" 15 "kein_Verbrennungskraftstoff" ;
VAL_ 1601 MO_Ansaugsystem 0 "Turbo" 1 "Sauger" ;
VAL_ 1601 MO_OBD_Typ 0 "NoOBD_RdW" 1 "EOBD" 2 "US_OBD" 3 "reserviert" ;
VAL_ 1601 MO_DPF_verbaut 0 "kein_DPF_verbaut" 1 "DPF_verbaut" ;
VAL_ 1601 TSK_Codierung 0 "kein_Fahrgeschwindigkeitsregler" 1 "GRA" 2 "GRA_Plus" 3 "Basis_ACC" 4 "ACC_Follow_to_Stop" 5 "ACC_Stop_and_Go" 7 "Codierung_in_Plausibilisierungsphase" ;
VAL_ 394 MO_Ablaufstatus 0 "keine_Aktion" 1 "Aktion_regulaerer_Uebergang" 2 "Aktion_regulaerer_Uebergang" 3 "Aktion_regulaerer_Uebergang" 4 "Aktion_regulaerer_Uebergang" 5 "Aktion_regulaerer_Uebergang" 6 "Aktion_regulaerer_Uebergang" 7 "Aktion_regulaerer_Uebergang" 8 "regulaerer_Uebergang_fertig" 9 "Aktion_Abbruch_Uebergang" 10 "Aktion_Abbruch_Uebergang" 11 "Aktion_Abbruch_Uebergang" 12 "Aktion_Abbruch_Uebergang" 13 "Aktion_Abbruch_Uebergang" 14 "Abbruch_Uebergang_fertig" 15 "Fehler" ;
VAL_ 394 MO_Ablaufstrg_Betriebszustand 0 "Init_Nicht_Betriebsbereit" 1 "Betriebsbereitschaft" 2 "Fahrbetrieb" 7 "Fehler" ;
VAL_ 394 MO_Ablaufstrg_Zustand_VKM_Ist 0 "VKM_aus" 1 "VKM_ein" ;
VAL_ 394 MO_Ablaufstrg_Kraftschluss_Ist 0 "kein_Kraftschluss" 1 "Kraftschluss" ;
VAL_ 394 MO_Ablaufstrg_Zustand_K0_Ist 0 "K0_Kupplung_auf" 1 "K0_Kupplung_zu" ;
VAL_ 394 MO_Ablaufstrg_Kraftschluss2_Ist 0 "Sekundärachse abgekoppelt" 1 "Sekundärachse angekoppelt" ;
VAL_ 394 MO_HYB_LowSpeedModus 0 "LowSpeed_mit_LLDZ" 1 "LowSpeed_ohne_LLDZ" ;
VAL_ 394 MO_Ablaufstrg_Zustand_VKM_Ziel 0 "VKM_aus" 1 "VKM_ein" ;
VAL_ 394 MO_Ablaufstrg_Kraftschluss_Ziel 0 "kein_Kraftschluss" 1 "Kraftschluss" ;
VAL_ 394 MO_Ablaufstrg_Zustand_K0_Ziel 0 "K0_Kupplung_auf" 1 "K0_Kupplung_zu" ;
VAL_ 394 MO_Ablaufstrg_Kraftschluss2_Ziel 0 "Anforderung Sekundaerachse abkoppeln" 1 "Anforderung Sekundaerachse ankoppeln" ;
VAL_ 394 MO_HYB_Stoppmodus 0 "Softstopp" 1 "Dynamikstopp" ;
VAL_ 394 MO_Auth_Aufforderung_WFS 0 "Aus" 1 "Ein" ;
VAL_ 394 MO_Start_Dynamik 0 "Kein_Start" 1 "VKM_IDLE_Start" 2 "Softstart_Schubankoppeln_unbefeu" 3 "Komfortstart_befeuert" 4 "Dynamikstart_befeuert" 5 "Sportstart_befeuert" 6 "plausibilisierter_Schleppstart" 7 "Notstart" ;
VAL_ 394 MO_Start_Art 0 "Init" 1 "Zustarteinrichtung" 2 "Schlupfstart" 3 "Schleppstart" ;
VAL_ 394 MO_Abstellposition_02 255 "Abstellposition_ungenau" ;
VAL_ 394 MO_Mom_Freiheit_Sekundaerachse 0 "Sekundaerachse ist nicht momentenfrei" 1 "Sekundaerachse ist momentenfrei" ;
VAL_ 394 MO_Tankklappensteuerung 0 "Init_nicht_verbaut" 1 "Tankklappe_soll_entriegeln" 2 "Tankklappe_soll_verriegeln" 3 "keine_Aktion" ;
VAL_ 394 MO_HYB_E_Faktor 0 "null" 1 "plus_1" 2 "plus_2" 3 "plus_3" 4 "plus_4" 5 "plus_5" 6 "plus_6" 7 "plus_7" 8 "minus_8" 9 "minus_7" 10 "minus_6" 11 "minus_5" 12 "minus_4" 13 "minus_3" 14 "minus_2" 15 "minus_1" ;
VAL_ 394 MO_HYB_EMode_Info 0 "Normal_Mode" 1 "Depleting_Mode" 2 "Charge_Mode" 3 "Sonder_Schaltprogramm" ;
VAL_ 394 MO_HYB_Adaption_aktiv 0 "Keine_Adaption_aktiv" 1 "Adaption_aktiv" ;
VAL_ 1156 ND_VDOP 1022 "Init" 1023 "Fehler" ;
VAL_ 1156 ND_TDOP 1022 "Init" 1023 "Fehler" ;
VAL_ 1156 ND_HDOP 1022 "Init" 1023 "Fehler" ;
VAL_ 1156 ND_GDOP 1022 "Init" 1023 "Fehler" ;
VAL_ 1156 ND_PDOP 1022 "Init" 1023 "Fehler" ;
VAL_ 1156 ND_Heading 4094 "Init" 4095 "Fehler" ;
VAL_ 1156 ND_Init 0 "nicht_Initialisiert" 1 "Initialisiert" ;
VAL_ 1157 ND_SatInUse 30 "Init" 31 "Fehler" ;
VAL_ 1157 ND_SatInView 30 "Init" 31 "Fehler" ;
VAL_ 1157 NP_Altitude 4094 "Init" 4095 "Fehler" ;
VAL_ 2527679512 ND_Timezone_Offset 14 "Init" 15 "Fehler" ;
VAL_ 2527679512 ND_Timezone_SignBit 0 "PLUS_Vorzeichen" 1 "MINUS_Vorzeichen" ;
VAL_ 2527679512 ND_Timezone_Validity 0 "invalid" 1 "valid" ;
VAL_ 2527679512 ND_TimeToDestination 510 "Fehler" 511 "Init" ;
VAL_ 2527679512 ND_RouteType 0 "keine_Zielfuehrung_oder_MPR_aktiv" 1 "MPR_aktiv" 2 "Zielfuehrung_aktiv" 3 "reserviert" ;
VAL_ 2527679512 ND_TimeOffset 0 "Ziel_in_gleicher_Zeitzone" 1 "Ziel_in_Zeitzone_plus_1" 2 "Ziel_in_Zeitzone_minus_1" 3 "Zielzeitzone_groesser_plus_minus_1" ;
VAL_ 2527679512 ND_Fuelstation_detected 0 "nicht_verbaut" 1 "Tankstelle_nicht_erkannt" 2 "Tankstelle_erkannt" 3 "Init" ;
VAL_ 2527679512 ND_Velocity 1022 "Init" 1023 "Fehler" ;
VAL_ 2527679512 ND_RecDelay 4094 "Init" 4095 "Fehler" ;
VAL_ 2527679512 ND_SendDelay 4094 "Init" 4095 "Fehler" ;
VAL_ 1158 NP_LatDegree 134217726 "Init" 134217727 "Fehler" ;
VAL_ 1158 NP_LongDegree 268435454 "Init" 268435455 "Fehler" ;
VAL_ 1158 NP_LatDirection 0 "Nord" 1 "Sued" ;
VAL_ 1158 NP_LongDirection 0 "Ost" 1 "West" ;
VAL_ 1158 NP_Sat 30 "Init" 31 "Fehler" ;
VAL_ 1158 NP_Fix 0 "Init" 1 "No_Fix" 2 "2D_Fix" 3 "3D_Fix" ;
VAL_ 2589283496 POS_MUX 0 "MUX_0" 1 "MUX_1" 2 "reserved" 3 "Init" ;
VAL_ 2589283496 POS_ODD_EVEN 0 "ODD" 1 "EVEN" ;
VAL_ 2589283496 POS_PosStati 0 "Init" 1 "NoNavAvailable" 2 "NoMapAvailable" 3 "NavBooting" 4 "NavError" 5 "NavCalibrating" 6 "NavNoGpsResyncSince1h" 7 "NavOffroadParkgarageRampOffset2" 8 "DeadReckoningWithoutGps" 9 "DeadReckoningWithGps" 10 "MapMatchedLowConfidence" 11 "MapMatchedLimitedConfidence" 12 "OffroadHighConfidence" 13 "MapMatchedHighConfidence" 14 "PosInSyncWithGpsAndMAP" ;
VAL_ 2589283496 POS_LatDirection 0 "North" 1 "South" ;
VAL_ 2589283496 POS_LatDegree 134217726 "Init" 134217727 "Fehler" ;
VAL_ 2589283496 POS_Heading_Trust 0 "Init" 1 "TrustLevel01" 2 "TrustLevel02" 3 "Fehler" ;
VAL_ 2589283496 POS_LongDirection 0 "East" 1 "West" ;
VAL_ 2589283496 POS_LongDegree 268435454 "Init" 268435455 "Fehler" ;
VAL_ 2527679647 Stellgliedtest_NFC 0 "Init_kein_Stellgliedtest" 1 "Stellgliedtest_angefordert" ;
VAL_ 2527679647 NFC_ESM_aktivieren 0 "Init_kein_ESM" 1 "ESM_aktivieren" ;
VAL_ 2527679647 ZV_auf_NFC 0 "Init_keine_Meldung" 1 "ZV_auf_NFC" ;
VAL_ 2527679647 ZV_zu_NFC 0 "Init_keine_Meldung" 1 "ZV_zu_NFC" ;
VAL_ 2527679647 NFC_Front_Verr_Authorisiert 0 "kein_NFC_Handy_erkannt" 1 "NFC_Handy_erkannt_und_authorisiert" ;
VAL_ 2527679647 NFC_Front_Entr_Authorisiert 0 "kein_NFC_Handy_erkannt" 1 "NFC_Handy_erkannt_und_authorisiert" ;
VAL_ 2527679647 NFC_HD_Verriegelung_Authorisiert 0 "kein_NFC_Handy_erkannt" 1 "NFC_Handy_erkannt_und_authorisiert" ;
VAL_ 2527679647 NFC_HD_Entriegelung_Authorisiert 0 "kein_NFC_Handy_erkannt" 1 "NFC_Handy_erkannt_und_authorisiert" ;
VAL_ 2527679647 NFC_aktiv 0 "NFC_nicht_aktiv" 1 "NFC_Kommunikation_aktiv" ;
VAL_ 2527679647 NFC_Laden_unterbrechen 0 "Laden_nicht_unterbrechen" 1 "Laden_unterbrechen" ;
VAL_ 2527679647 NFC_FT_Entriegelung_Authorisiert 0 "kein_NFC_Handy_erkannt" 1 "NFC_Handy_erkannt_und_authorisiert" ;
VAL_ 2527679647 NFC_FT_Verriegelung_Authorisiert 0 "kein_NFC_Handy_erkannt" 1 "NFC_Handy_erkannt_und_authorisiert" ;
VAL_ 1696 NV_aktiv 0 "NV nicht aktiv" 1 "NV aktiv" ;
VAL_ 1696 NV_Texte 0 "Init" 1 "Abblendlicht_einschalten" 2 "Fussgaengermarkierung_n_v" 3 "zur_Zeit_nicht_verfuegbar" 4 "Systemfehler" 5 "Fussgaengermarkierung_deakt" 6 "Blindheit_erkannt" 7 "kein_Text" ;
VAL_ 1696 NV_Gong 0 "kein_Gong" 1 "Gong_leise" 2 "Gong_mittel" 3 "Gong_laut" ;
VAL_ 1696 NV_Symbol 0 "kein_Symbol_anzeigen" 1 "Symbol_fuer_erkanntes_Objekt_anzeigen" ;
VAL_ 1696 NV_Hinweise 0 "keine_Anzeige" 1 "Disclaimer" 2 "Fussgaenger_Markierung_nicht_verfuegbar" 3 "Nachtsichtsystem_wird_initialisiert" ;
VAL_ 1696 NV_Piktogramm_aktiv 0 "keine_Anzeigenprioritaet" 1 "Anzeigenprioritaet" ;
VAL_ 1696 NV_Akustik_deaktiviert_Icon 0 "aus" 1 "ein" ;
VAL_ 1696 NV_FGM_deaktiviert_Icon 0 "aus" 1 "ein" ;
VAL_ 1696 NV_Markierungslicht_links 0 "Aus" 1 "Ein" ;
VAL_ 1696 NV_Markierungslicht_rechts 0 "Aus" 1 "Ein" ;
VAL_ 1696 NV_Symbol_Tierwarnung 0 "Aus" 1 "Ein" ;
VAL_ 1696 NV_Anf_Prefill 0 "nicht_angefordert" 1 "angefordert" ;
VAL_ 1696 NV_HBA_Parameter 0 "Defaultparametersatz" 1 "Parametersatz_mit_leicht_erhoehter_Empfindlichkeit" 2 "Parametersatz_mit_erhoehter_Empfindlichkeit" 3 "Parametersatz_mit_hoechster_Empfindlichkeit" ;
VAL_ 1696 NV_LED_Leiste 0 "AUS_keine_Anzeige" 1 "Stufe_1_glimmen" 2 "Stufe_2_leuchten" 3 "Stufe_3_blinken" ;
VAL_ 1696 NV_PreSense_Status 0 "Init" 1 "verfuegbar" 2 "nicht_verfuegbar" ;
VAL_ 1696 NV_PreSense_Modus_System 0 "deaktiviert" 1 "aktiviert" ;
VAL_ 1696 NV_PreSense_Modus_Warnung 0 "Aus" 1 "Setting_2" 2 "Setting_3" 3 "Setting_4" 4 "Setting_5" 5 "Ein" ;
VAL_ 1696 NV_FAS_Fkt_Status 0 "Init" 1 "Funktion_Ist_Ein" 2 "Funktion_Ist_Aus" 3 "Fehler" ;
VAL_ 1696 NV_Akt_Status_MMI 0 "deaktiviert" 1 "aktiviert" 3 "Init" ;
VAL_ 1696 NV_AnforderungBildaufschaltung 0 "KeineBildaufschaltung" 1 "Bildaufschaltung" ;
VAL_ 2600468494 NM_BCM1_SNI 14 "BCM1" ;
VAL_ 2600468494 NM_BCM1_CBV_AWB 0 "Passiver_WakeUp" 1 "Aktiver_WakeUp" ;
VAL_ 2600468494 NM_BCM1_CBV_CRI 0 "Standard_Layout" 1 "TNB_Layout" ;
VAL_ 2600468494 NM_BCM1_NM_State 0 "Init" 1 "NM_RM_aus_BSM" 2 "NM_RM_aus_PBSM" 4 "NM_NO_aus_RM" 8 "NM_NO_aus_RS" 16 "NM_RM_aus_RS" 32 "NM_RM_aus_NO" ;
VAL_ 2600468494 NM_BCM1_Car_Wakeup 0 "Inaktiv" 1 "Car_Wakeup" ;
VAL_ 2600468494 NM_BCM1_UDS_CC 0 "Init" 1 "CC_aktiv" ;
VAL_ 2600468494 NM_BCM1_NM_aktiv_KL15 0 "Inaktiv" 1 "KL15_EIN" ;
VAL_ 2600468494 NM_BCM1_NM_aktiv_Diagnose 0 "Init" 1 "Diagnose_aktiv" ;
VAL_ 2600468494 NM_BCM1_NM_aktiv_Tmin 0 "Inaktiv" 1 "Mindestaktivzeit" ;
VAL_ 2600468494 NM_BCM1_NM_aktiv_Notlaufblinken 1 "Notlaufblinken_aktiv" ;
VAL_ 2600468494 NM_BCM1_NM_aktiv_ComingHome 1 "ComingHome_aktiv" ;
VAL_ 2600468494 NM_BCM1_NM_aktiv_LeavingHome 1 "LeavingHome_aktiv" ;
VAL_ 2600468494 NM_BCM1_NM_aktiv_Taster_Schalter 0 "inaktiv" 1 "Nachlauf_aktiv" ;
VAL_ 2600468494 NM_BCM1_NM_aktiv_LIM 0 "inaktiv" 1 "LIM_aktiv" ;
VAL_ 2600468494 NM_BCM1_NM_aktiv_Innenlicht_Dim 0 "inaktiv" 1 "Innenlicht_Dimmung_aktiv" ;
VAL_ 2600468494 NM_BCM1_NM_aktiv_Aussenlicht 0 "Init" 1 "Aussenlicht_aktiv" ;
VAL_ 2600468494 NM_BCM1_NM_aktiv_Klimatisierung 0 "inaktiv" 1 "Klimatisierung_aktiv" ;
VAL_ 2600468494 NM_BCM1_CAB 0 "inaktiv" 1 "CAB_01__Tueren" 2 "CAB_02__Anhaenger" 4 "CAB_03__Nightvision" 8 "CAB_04__Sitzverstellung" 16 "CAB_05__Klappen" 32 "CAB_06__Infotainment" 64 "CAB_07__Sub_Infotainment" 128 "CAB_08__Anzeige" 256 "CAB_09__Laden" 512 "CAB_10__Klima" 1024 "CAB_11__FlexRay" 2097152 "CAB_22_VLAN_Connect" 4194304 "CAB_23_VLAN_Infotainment" 8388608 "CAB_24_VLAN_FAS" ;
VAL_ 2600468496 NM_Gateway_SNI 16 "Gateway" ;
VAL_ 2600468496 NM_Gateway_CBV_AWB 0 "Passiver_WakeUp" 1 "Aktiver_WakeUp" ;
VAL_ 2600468496 NM_Gateway_CBV_CRI 0 "Standard_Layout" 1 "TNB_Layout" ;
VAL_ 2600468496 NM_Gateway_NM_State 1 "NM_RM_aus_BSM" 2 "NM_RM_aus_PBSM" 4 "NM_NO_aus_RM" 8 "NM_NO_aus_RS" 16 "NM_RM_aus_RS" 32 "NM_RM_aus_NO" ;
VAL_ 2600468496 NM_Gateway_Car_Wakeup 0 "Inaktiv" 1 "Car_Wakeup" ;
VAL_ 2600468496 NM_Gateway_UDS_CC 0 "Init" 1 "CC_aktiv" ;
VAL_ 2600468496 NM_Gateway_NM_aktiv_KL15 0 "Inaktiv" 1 "KL15_EIN" ;
VAL_ 2600468496 NM_Gateway_NM_aktiv_Diagnose 0 "Init" 1 "Diagnose_aktiv" ;
VAL_ 2600468496 NM_Gateway_NM_aktiv_Tmin 0 "Inaktiv" 1 "Mindestaktivzeit" ;
VAL_ 2600468496 NM_Gateway_NM_aktiv_CWU 0 "kein_CWU_gesetzt" 1 "CWU_gesetzt" ;
VAL_ 2600468496 NM_Gateway_NM_aktiv_FC 0 "kein_FC_gesetzt" 1 "FC_gesetzt" ;
VAL_ 2600468496 NM_Gateway_NM_aktiv_Connect 0 "inaktiv" 1 "Nachlauf_aufgrund_Connect" ;
VAL_ 2600468496 NM_Gateway_NM_aktiv_EM 0 "inaktiv" 1 "Nachlauf_aufgrund_Energiemanagement" ;
VAL_ 2600468496 NM_Gateway_NM_aktiv_OBDC 0 "kein_Nachlauf" 1 "Nachlauf_aufgrund_OBDC" ;
VAL_ 2600468496 NM_Gateway_NM_aktiv_Buskopplung 0 "inaktiv" 1 "Nachlauf_aufgrund_Buskopplung" ;
VAL_ 2600468496 NM_Gateway_CAB 0 "inaktiv" 1 "CAB_01__Tueren" 2 "CAB_02__Anhaenger" 4 "CAB_03__Nightvision" 8 "CAB_04__Sitzverstellung" 16 "CAB_05__Klappen" 32 "CAB_06__Infotainment" 64 "CAB_07__Sub_Infotainment" 128 "CAB_08__Anzeige" 256 "CAB_09__Laden" 512 "CAB_10__Klima" 1024 "CAB_11__FlexRay" 2097152 "CAB_22_VLAN_Connect" 4194304 "CAB_23_VLAN_Infotainment" 8388608 "CAB_24_VLAN_FAS" ;
VAL_ 2600468550 NM_Klima_SNI 70 "Klima" ;
VAL_ 2600468550 NM_Klima_CBV_AWB 0 "Passiver_WakeUp" 1 "Aktiver_WakeUp" ;
VAL_ 2600468550 NM_Klima_CBV_CRI 0 "Standard_Layout" 1 "TNB_Layout" ;
VAL_ 2600468550 NM_Klima_NM_State 0 "Init" 1 "NM_RM_aus_BSM" 2 "NM_RM_aus_PBSM" 4 "NM_NO_aus_RM" 8 "NM_NO_aus_RS" 16 "NM_RM_aus_RS" 32 "NM_RM_aus_NO" ;
VAL_ 2600468550 NM_Klima_Car_Wakeup 0 "Inaktiv" 1 "Car_Wakeup" ;
VAL_ 2600468550 NM_Klima_UDS_CC 0 "Init" 1 "CC_aktiv" ;
VAL_ 2600468550 NM_Klima_NM_aktiv_KL15 0 "Inaktiv" 1 "KL15_EIN" ;
VAL_ 2600468550 NM_Klima_NM_aktiv_Diagnose 0 "Init" 1 "Diagnose_aktiv" ;
VAL_ 2600468550 NM_Klima_NM_aktiv_Tmin 0 "Inaktiv" 1 "Mindestaktivzeit" ;
VAL_ 2600468550 NM_Klima_NM_aktiv_Abstellzstd 0 "inaktiv" 1 "Abstellzustand_aktiv" ;
VAL_ 2600468550 NM_Klima_CAB 0 "inaktiv" 1 "CAB_01__Tueren" 2 "CAB_02__Anhaenger" 4 "CAB_03__Nightvision" 8 "CAB_04__Sitzverstellung" 16 "CAB_05__Klappen" 32 "CAB_06__Infotainment" 64 "CAB_07__Sub_Infotainment" 128 "CAB_08__Anzeige" 256 "CAB_09__Laden" 512 "CAB_10__Klima" 1024 "CAB_11__FlexRay" 2097152 "CAB_22_VLAN_Connect" 4194304 "CAB_23_VLAN_Infotainment" 8388608 "CAB_24_VLAN_FAS" ;
VAL_ 2600468569 NM_Lift_VA_SNI 89 "Lift_VA" ;
VAL_ 2600468569 NM_Lift_VA_CBV_AWB 0 "Passiver_WakeUp" 1 "Aktiver_WakeUp" ;
VAL_ 2600468569 NM_Lift_VA_CBV_CRI 0 "Standard_Layout" 1 "TNB_Layout" ;
VAL_ 2600468569 NM_Lift_VA_NM_State 1 "NM_RM_aus_BSM" 2 "NM_RM_aus_PBSM" 4 "NM_NO_aus_RM" 8 "NM_NO_aus_RS" ;
VAL_ 2600468569 NM_Lift_VA_Car_Wakeup 0 "Inaktiv" 1 "Car_Wakeup" ;
VAL_ 2600468569 NM_Lift_VA_UDS_CC 1 "CC_aktiv" ;
VAL_ 2600468569 NM_Lift_VA_NM_aktiv_KL15 0 "Inaktiv" 1 "KL15_EIN" ;
VAL_ 2600468569 NM_Lift_VA_NM_aktiv_Diag 0 "Inaktiv" 1 "Diagnose_aktiv" ;
VAL_ 2600468569 NM_Lift_VA_NM_aktiv_Tmin 0 "Inaktiv" 1 "Mindestaktivzeit" ;
VAL_ 2600468569 NM_Lift_VA_CAB 0 "inaktiv" 1 "CAB_01__Tueren" 2 "CAB_02__Anhaenger" 4 "CAB_03__Nightvision" 8 "CAB_04__Sitzverstellung" 16 "CAB_05__Klappen" 32 "CAB_06__Infotainment" 64 "CAB_07__Sub_Infotainment" 128 "CAB_08__Anzeige" 256 "CAB_09__Laden" 512 "CAB_10__Klima" 1024 "CAB_11__FlexRay" 2097152 "CAB_22_VLAN_Connect" 4194304 "CAB_23_VLAN_Infotainment" 8388608 "CAB_24_VLAN_FAS" ;
VAL_ 2600468676 NM_VAS_L_SNI 196 "VAS_L" ;
VAL_ 2600468676 NM_VAS_L_CBV_AWB 0 "Passiver_WakeUp" 1 "Aktiver_WakeUp" ;
VAL_ 2600468676 NM_VAS_L_CBV_CRI 0 "Standard_Layout" 1 "TNB_Layout" ;
VAL_ 2600468676 NM_VAS_L_NM_State 0 "Init" 1 "NM_RM_aus_BSM" 2 "NM_RM_aus_PBSM" 4 "NM_NO_aus_RM" 8 "NM_NO_aus_RS" 16 "NM_RM_aus_RS" 32 "NM_RM_aus_NO" ;
VAL_ 2600468676 NM_VAS_L_Car_Wakeup 0 "Inaktiv" 1 "Car_Wakeup" ;
VAL_ 2600468676 NM_VAS_L_UDS_CC 0 "Init" 1 "CC_aktiv" ;
VAL_ 2600468676 NM_VAS_L_NM_aktiv_KL15 0 "Inaktiv" 1 "KL15_EIN" ;
VAL_ 2600468676 NM_VAS_L_NM_aktiv_Diagnose 0 "Init" 1 "Diagnose_aktiv" ;
VAL_ 2600468676 NM_VAS_L_NM_aktiv_Tmin 0 "Inaktiv" 1 "Mindestaktivzeit" ;
VAL_ 2600468676 NM_VAS_L_NM_aktiv_Verstellung 0 "Inaktiv" 1 "Verstellung_aktiv" ;
VAL_ 2600468676 NM_VAS_L_CAB 0 "inaktiv" 1 "CAB_01__Tueren" 2 "CAB_02__Anhaenger" 4 "CAB_03__Nightvision" 8 "CAB_04__Sitzverstellung" 16 "CAB_05__Klappen" 32 "CAB_06__Infotainment" 64 "CAB_07__Sub_Infotainment" 128 "CAB_08__Anzeige" 256 "CAB_09__Laden" 512 "CAB_10__Klima" 1024 "CAB_11__FlexRay" 2097152 "CAB_22_VLAN_Connect" 4194304 "CAB_23_VLAN_Infotainment" 8388608 "CAB_24_VLAN_FAS" ;
VAL_ 2600468677 NM_VAS_R_SNI 197 "VAS_R" ;
VAL_ 2600468677 NM_VAS_R_CBV_AWB 0 "Passiver_WakeUp" 1 "Aktiver_WakeUp" ;
VAL_ 2600468677 NM_VAS_R_CBV_CRI 0 "Standard_Layout" 1 "TNB_Layout" ;
VAL_ 2600468677 NM_VAS_R_NM_State 0 "Init" 1 "NM_RM_aus_BSM" 2 "NM_RM_aus_PBSM" 4 "NM_NO_aus_RM" 8 "NM_NO_aus_RS" 16 "NM_RM_aus_RS" 32 "NM_RM_aus_NO" ;
VAL_ 2600468677 NM_VAS_R_Car_Wakeup 0 "Inaktiv" 1 "Car_Wakeup" ;
VAL_ 2600468677 NM_VAS_R_UDS_CC 0 "Init" 1 "CC_aktiv" ;
VAL_ 2600468677 NM_VAS_R_NM_aktiv_KL15 0 "Inaktiv" 1 "KL15_EIN" ;
VAL_ 2600468677 NM_VAS_R_NM_aktiv_Diagnose 0 "Init" 1 "Diagnose_aktiv" ;
VAL_ 2600468677 NM_VAS_R_NM_aktiv_Tmin 0 "Inaktiv" 1 "Mindestaktivzeit" ;
VAL_ 2600468677 NM_VAS_R_NM_aktiv_Verstellung 0 "Inaktiv" 1 "Verstellung_aktiv" ;
VAL_ 2600468677 NM_VAS_R_CAB 0 "inaktiv" 1 "CAB_01__Tueren" 2 "CAB_02__Anhaenger" 4 "CAB_03__Nightvision" 8 "CAB_04__Sitzverstellung" 16 "CAB_05__Klappen" 32 "CAB_06__Infotainment" 64 "CAB_07__Sub_Infotainment" 128 "CAB_08__Anzeige" 256 "CAB_09__Laden" 512 "CAB_10__Klima" 1024 "CAB_11__FlexRay" 2097152 "CAB_22_VLAN_Connect" 4194304 "CAB_23_VLAN_Infotainment" 8388608 "CAB_24_VLAN_FAS" ;
